VERSION ""

NS_ :

BS_:

BU_: CH DIPF DIPR ETH FC HVI HVS PARTY SDCV VEH VIRT

BO_ 536 UI_driverAssistRoadSign: 8 CH
 SG_ UI_roadSignChecksum : 56|8@1+ (1,0) [0|255] ""  X
 SG_ UI_roadSignCounter : 52|4@1+ (1,0) [0|15] ""  X
 SG_ UI_splineID : 48|4@1+ (1,0) [0|15] ""  X
 SG_ UI_splineLocConfidence : 40|7@1+ (1,0) [0|127] "1"  das
 SG_ UI_rampType m4 : 32|3@1+ (1,0) [0|4] ""  das
 SG_ UI_meanFleetSplineAccelMPS2 m4 : 24|8@1+ (0.05,-6.35) [-6.35|6.4] "m/s^2"  das
 SG_ UI_topQrtlFleetSpeedMPS m3 : 24|8@1+ (0.25,0) [0|63.75] "m/s"  das
 SG_ UI_stopSignStopLineConf m1 : 18|7@1+ (1,0) [0|127] "1"  X
 SG_ UI_trafficLightStopLineConf m2 : 18|7@1+ (1,0) [0|127] "1"  X
 SG_ UI_medianFleetSpeedMPS m4 : 16|8@1+ (0.25,0) [0|63.75] "m/s"  das
 SG_ UI_bottomQrtlFleetSpeedMPS m3 : 16|8@1+ (0.25,0) [0|63.75] "m/s"  das
 SG_ UI_currSplineIdFull m5 : 8|32@1+ (1,0) [0|4294967295] "1"  app
 SG_ UI_meanFleetSplineSpeedMPS m4 : 8|8@1+ (0.25,0) [0|63.75] "m/s"  das
 SG_ UI_trafficLightStopLineDist m2 : 8|10@1+ (0.25,-8) [-8|247.5] "m"  X
 SG_ UI_stopSignStopLineDist m1 : 8|10@1+ (0.25,-8) [-8|247.5] "m"  X
 SG_ UI_baseMapSpeedLimitMPS m3 : 8|8@1+ (0.25,0) [0|63.75] "m/s"  das
 SG_ UI_dummyData m0 : 8|1@1+ (1,0) [0|1] ""  X
 SG_ UI_roadSign M : 0|8@1+ (1,0) [0|255] ""  das

BO_ 2046 dynamicMessage0_0: 1 CH
 SG_ DAS_tbarTorqueOffset : 0|8@1+ (0.005,-0.64) [-0.64|0.63] "Nm"  aps

BO_ 845 TAS_warningMatrix1: 8 CH
 SG_ TAS_w041_PWMopenRR : 40|1@1+ (1,0) [0|1] ""  gtw
 SG_ TAS_w040_PWMopenRL : 39|1@1+ (1,0) [0|1] ""  gtw
 SG_ TAS_w039_PWMopenFR : 38|1@1+ (1,0) [0|1] ""  gtw
 SG_ TAS_w038_PWMopenFL : 37|1@1+ (1,0) [0|1] ""  gtw
 SG_ TAS_w037_PWMshortRR : 36|1@1+ (1,0) [0|1] ""  gtw
 SG_ TAS_w036_PWMshortRL : 35|1@1+ (1,0) [0|1] ""  gtw
 SG_ TAS_w035_PWMshortFR : 34|1@1+ (1,0) [0|1] ""  gtw
 SG_ TAS_w034_PWMshortFL : 33|1@1+ (1,0) [0|1] ""  gtw
 SG_ TAS_w033_PWMerrorRR : 32|1@1+ (1,0) [0|1] ""  gtw
 SG_ TAS_w032_PWMerrorRL : 31|1@1+ (1,0) [0|1] ""  gtw
 SG_ TAS_w031_PWMerrorFR : 30|1@1+ (1,0) [0|1] ""  gtw
 SG_ TAS_w030_PWMerrorFL : 29|1@1+ (1,0) [0|1] ""  gtw
 SG_ TAS_w029_NVRAMUninitialized : 28|1@1+ (1,0) [0|1] ""  gtw
 SG_ TAS_w028_NVRAMNotResponding : 27|1@1+ (1,0) [0|1] ""  gtw
 SG_ TAS_w027_NVRAMCorruption : 26|1@1+ (1,0) [0|1] ""  gtw
 SG_ TAS_w026_FlashMemoryError : 25|1@1+ (1,0) [0|1] ""  gtw
 SG_ TAS_w025_CrashEvent : 24|1@1+ (1,0) [0|1] ""  gtw
 SG_ TAS_w024_WakeError : 23|1@1+ (1,0) [0|1] ""  gtw
 SG_ TAS_w023_SleepError : 22|1@1+ (1,0) [0|1] ""  gtw
 SG_ TAS_w022_TaskInitError : 21|1@1+ (1,0) [0|1] ""  gtw
 SG_ TAS_w021_TaskSchedulerError : 20|1@1+ (1,0) [0|1] ""  gtw
 SG_ TAS_w020_PWMError : 19|1@1+ (1,0) [0|1] ""  gtw
 SG_ TAS_w019_I2CError : 18|1@1+ (1,0) [0|1] ""  gtw
 SG_ TAS_w018_ADCError : 17|1@1+ (1,0) [0|1] ""  gtw
 SG_ TAS_w017_AwakeForTooLong : 16|1@1+ (1,0) [0|1] ""  gtw
 SG_ TAS_w016_MessageTimingError : 15|1@1+ (1,0) [0|1] ""  gtw
 SG_ TAS_w015_NVMMAlert : 14|1@1+ (1,0) [0|1] ""  gtw
 SG_ TAS_w014_BridgeFault : 13|1@1+ (1,0) [0|1] ""  gtw
 SG_ TAS_w013_Shared13 : 12|1@1+ (1,0) [0|1] ""  gtw
 SG_ TAS_w012_CPUReset : 11|1@1+ (1,0) [0|1] ""  gtw
 SG_ TAS_w011_ECUSupplyVoltError : 10|1@1+ (1,0) [0|1] ""  gtw
 SG_ TAS_w010_ExtSupplyVoltError : 9|1@1+ (1,0) [0|1] ""  gtw
 SG_ TAS_w009_LIN3Error : 8|1@1+ (1,0) [0|1] ""  gtw
 SG_ TAS_w008_LIN2Error : 7|1@1+ (1,0) [0|1] ""  gtw
 SG_ TAS_w007_LINTimeout : 6|1@1+ (1,0) [0|1] ""  gtw
 SG_ TAS_w006_CANLowError : 5|1@1+ (1,0) [0|1] ""  gtw
 SG_ TAS_w005_CANHighError : 4|1@1+ (1,0) [0|1] ""  gtw
 SG_ TAS_w004_CANMIA : 3|1@1+ (1,0) [0|1] ""  gtw
 SG_ TAS_w003_SWAssertion : 2|1@1+ (1,0) [0|1] ""  gtw
 SG_ TAS_w002_PowerLossReset : 1|1@1+ (1,0) [0|1] ""  gtw
 SG_ TAS_w001_WatchdogReset : 0|1@1+ (1,0) [0|1] ""  gtw

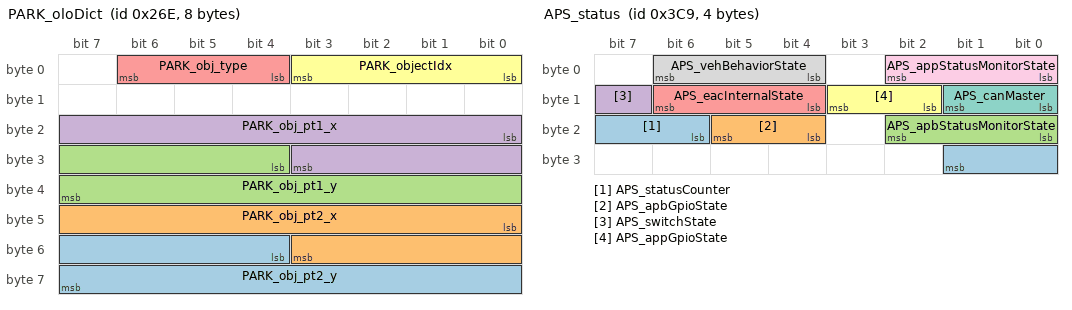
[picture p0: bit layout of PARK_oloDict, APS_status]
BO_ 622 PARK_oloDict: 8 CH
 SG_ PARK_obj_pt2_y : 52|12@1+ (1,0) [0|4095] ""  das
 SG_ PARK_obj_pt2_x : 40|12@1+ (1,0) [0|4095] ""  das
 SG_ PARK_obj_pt1_y : 28|12@1+ (1,0) [0|4095] ""  das
 SG_ PARK_obj_pt1_x : 16|12@1+ (1,0) [0|4095] ""  das
 SG_ PARK_obj_type : 4|3@1+ (1,0) [0|4] ""  das
 SG_ PARK_objectIdx : 0|4@1+ (1,0) [0|15] ""  das

BO_ 969 APS_status: 4 CH
 SG_ APS_statusCounter : 22|4@1+ (1,0) [0|15] ""  X
 SG_ APS_apbGpioState : 20|2@1+ (1,0) [0|3] ""  gtw
 SG_ APS_apbStatusMonitorState : 16|3@1+ (1,0) [0|7] ""  gtw
 SG_ APS_switchState : 15|1@1+ (1,0) [0|1] ""  X
 SG_ APS_eacInternalState : 12|3@1+ (1,0) [0|7] ""  gtw
 SG_ APS_appGpioState : 10|2@1+ (1,0) [0|3] ""  gtw
 SG_ APS_canMaster : 8|2@1+ (1,0) [0|3] ""  gtw
 SG_ APS_vehBehaviorState : 4|3@1+ (1,0) [0|7] ""  gtw
 SG_ APS_appStatusMonitorState : 0|3@1+ (1,0) [0|7] ""  gtw

BO_ 1848 EPAS3S_udsResponse: 8 CH
 SG_ EPAS3S_udsResponseData : 7|64@0+ (1,0) [0|18446744073709551615] ""  gtw

BO_ 874 DAS_warningMatrix1: 8 CH
 SG_ DAS_w106_torsionBarCalibrated : 41|1@1+ (1,0) [0|1] ""  gtw
 SG_ DAS_w105_DEPRECATED : 40|1@1+ (1,0) [0|1] ""  gtw
 SG_ DAS_w104_DEPRECATED : 39|1@1+ (1,0) [0|1] ""  gtw
 SG_ DAS_w103_robExperimentalAEB : 38|1@1+ (1,0) [0|1] ""  gtw
 SG_ DAS_w102_DEPRECATED : 37|1@1+ (1,0) [0|1] ""  gtw
 SG_ DAS_w101_DEPRECATED : 36|1@1+ (1,0) [0|1] ""  gtw
 SG_ DAS_w100_DEPRECATED : 35|1@1+ (1,0) [0|1] ""  gtw
 SG_ DAS_w099_DEPRECATED : 34|1@1+ (1,0) [0|1] ""  gtw
 SG_ DAS_w098_DEPRECATED : 33|1@1+ (1,0) [0|1] ""  gtw
 SG_ DAS_w097_DEPRECATED : 32|1@1+ (1,0) [0|1] ""  gtw
 SG_ DAS_w096_DEPRECATED : 31|1@1+ (1,0) [0|1] ""  gtw
 SG_ DAS_w095_DEPRECATED : 30|1@1+ (1,0) [0|1] ""  gtw
 SG_ DAS_w094_DEPRECATED : 29|1@1+ (1,0) [0|1] ""  gtw
 SG_ DAS_w093_DEPRECATED : 28|1@1+ (1,0) [0|1] ""  gtw
 SG_ DAS_w092_DEPRECATED : 27|1@1+ (1,0) [0|1] ""  gtw
 SG_ DAS_w091_DEPRECATED : 26|1@1+ (1,0) [0|1] ""  gtw
 SG_ DAS_w090_DEPRECATED : 25|1@1+ (1,0) [0|1] ""  gtw
 SG_ DAS_w089_DEPRECATED : 24|1@1+ (1,0) [0|1] ""  gtw
 SG_ DAS_w088_DEPRECATED : 23|1@1+ (1,0) [0|1] ""  gtw
 SG_ DAS_w087_DEPRECATED : 22|1@1+ (1,0) [0|1] ""  gtw
 SG_ DAS_w086_robCollision : 21|1@1+ (1,0) [0|1] ""  gtw
 SG_ DAS_w085_pmmSteering : 20|1@1+ (1,0) [0|1] ""  gtw
 SG_ DAS_w084_pmmIPSO : 19|1@1+ (1,0) [0|1] ""  gtw
 SG_ DAS_w083_inPathRADObject : 18|1@1+ (1,0) [0|1] ""  gtw
 SG_ DAS_w082_inPathFSviolation : 17|1@1+ (1,0) [0|1] ""  gtw
 SG_ DAS_w081_pmmActiveBraking : 16|1@1+ (1,0) [0|1] ""  gtw
 SG_ DAS_w080_accFailedActivation : 15|1@1+ (1,0) [0|1] ""  gtw
 SG_ DAS_w079_edrAvailable : 14|1@1+ (1,0) [0|1] ""  gtw
 SG_ DAS_w078_pmmActive2 : 13|1@1+ (1,0) [0|1] ""  gtw
 SG_ DAS_w077_pmmActive : 12|1@1+ (1,0) [0|1] ""  gtw
 SG_ DAS_w076_mobilEyeSetC : 11|1@1+ (1,0) [0|1] ""  gtw
 SG_ DAS_w075_scMia : 10|1@1+ (1,0) [0|1] ""  gtw
 SG_ DAS_w074_inPathStationaryObst : 9|1@1+ (1,0) [0|1] ""  gtw
 SG_ DAS_w073_issueEscalatedLDW : 8|1@1+ (1,0) [0|1] ""  gtw
 SG_ DAS_w072_selfparkComplete : 7|1@1+ (1,0) [0|1] ""  gtw
 SG_ DAS_w071_selfparkStarted : 6|1@1+ (1,0) [0|1] ""  gtw
 SG_ DAS_w070_apcIncompleteCal : 5|1@1+ (1,0) [0|1] ""  gtw
 SG_ DAS_w069_apcSpaceMasked : 4|1@1+ (1,0) [0|1] ""  gtw
 SG_ DAS_w068_vlInconsistency : 3|1@1+ (1,0) [0|1] ""  gtw
 SG_ DAS_w067_steeringAlignment : 2|1@1+ (1,0) [0|1] ""  gtw
 SG_ DAS_w066_deserializerLockLost : 1|1@1+ (1,0) [0|1] ""  gtw
 SG_ DAS_w065_deserializerOvercurrent : 0|1@1+ (1,0) [0|1] ""  gtw

BO_ 1469 IBST_alertLog: 8 CH
 SG_ IBST_alertState : 15|1@1+ (1,0) [0|1] ""  gtw
 SG_ IBST_alertID : 0|8@1+ (1,0) [0|176] ""  gtw

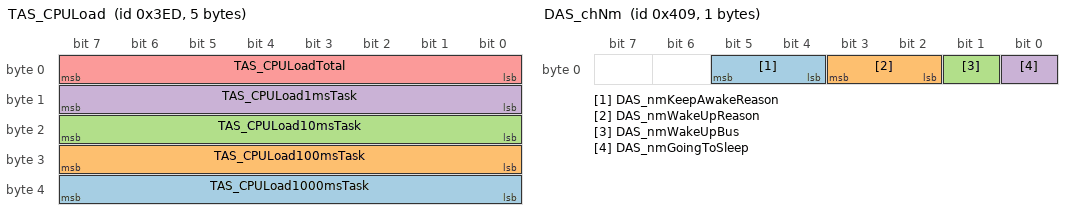
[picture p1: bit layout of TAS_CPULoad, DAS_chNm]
BO_ 1005 TAS_CPULoad: 5 CH
 SG_ TAS_CPULoad1000msTask : 32|8@1+ (1,0) [0|255] ""  X
 SG_ TAS_CPULoad100msTask : 24|8@1+ (1,0) [0|255] ""  X
 SG_ TAS_CPULoad10msTask : 16|8@1+ (1,0) [0|255] ""  X
 SG_ TAS_CPULoad1msTask : 8|8@1+ (1,0) [0|255] ""  X
 SG_ TAS_CPULoadTotal : 0|8@1+ (1,0) [0|255] ""  X

BO_ 1033 DAS_chNm: 1 CH
 SG_ DAS_nmKeepAwakeReason : 4|2@1+ (1,0) [0|2] ""  aps
 SG_ DAS_nmWakeUpReason : 2|2@1+ (1,0) [0|3] ""  aps
 SG_ DAS_nmWakeUpBus : 1|1@1+ (1,0) [0|1] ""  aps
 SG_ DAS_nmGoingToSleep : 0|1@1+ (1,0) [0|1] ""  aps

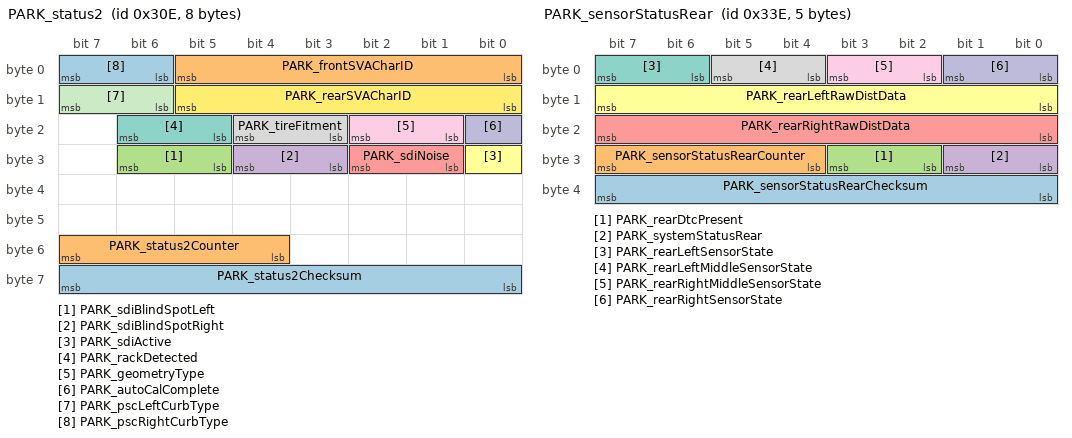
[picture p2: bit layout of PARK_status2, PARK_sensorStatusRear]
BO_ 782 PARK_status2: 8 CH
 SG_ PARK_status2Checksum : 56|8@1+ (1,0) [0|255] ""  X
 SG_ PARK_status2Counter : 52|4@1+ (1,0) [0|15] ""  das
 SG_ PARK_sdiBlindSpotLeft : 29|2@1+ (1,0) [0|3] ""  das
 SG_ PARK_sdiBlindSpotRight : 27|2@1+ (1,0) [0|3] ""  das
 SG_ PARK_sdiNoise : 25|2@1+ (1,0) [0|3] ""  das
 SG_ PARK_sdiActive : 24|1@1+ (1,0) [0|1] ""  das
 SG_ PARK_rackDetected : 21|2@1+ (1,0) [0|3] ""  das
 SG_ PARK_tireFitment : 19|2@1+ (1,0) [0|3] ""  das
 SG_ PARK_geometryType : 17|2@1+ (1,0) [0|3] ""  X
 SG_ PARK_autoCalComplete : 16|1@1+ (1,0) [0|1] ""  das
 SG_ PARK_pscLeftCurbType : 14|2@1+ (1,0) [0|2] ""  das
 SG_ PARK_rearSVACharID : 8|6@1+ (1,0) [0|63] ""  das
 SG_ PARK_pscRightCurbType : 6|2@1+ (1,0) [0|2] ""  das
 SG_ PARK_frontSVACharID : 0|6@1+ (1,0) [0|63] ""  das

BO_ 2023 CMP_EOLTest: 8 CH
 SG_ CMP_EOLData : 0|64@1+ (1,0) [0|18446744073709551615] ""  X

BO_ 557 TAS_data: 7 CH
 SG_ TAS_componentPressureRL m2 : 43|8@1+ (0.1,0) [0|25.5] "bar"  X
 SG_ TAS_componentPressureFR m1 : 43|8@1+ (0.1,0) [0|25.5] "bar"  X
 SG_ TAS_componentPressureFL m0 : 43|8@1+ (0.1,0) [0|25.5] "bar"  X
 SG_ TAS_componentPressureRR m3 : 43|8@1+ (0.1,0) [0|25.5] "bar"  X
 SG_ TAS_componentPressureIndex M : 39|2@1+ (1,0) [0|3] ""  X
 SG_ TAS_valveCommandBoost : 38|1@1+ (1,0) [0|1] ""  X
 SG_ TAS_valveCommandExhaust : 37|1@1+ (1,0) [0|1] ""  X
 SG_ TAS_valveCommandReservoir : 36|1@1+ (1,0) [0|1] ""  X
 SG_ TAS_valveCommandRR : 35|1@1+ (1,0) [0|1] ""  X
 SG_ TAS_valveCommandRL : 34|1@1+ (1,0) [0|1] ""  X
 SG_ TAS_valveCommandFR : 33|1@1+ (1,0) [0|1] ""  X
 SG_ TAS_valveCommandFL : 32|1@1+ (1,0) [0|1] ""  X
 SG_ TAS_rawHeightRR : 24|8@1+ (1,-128) [-128|127] "mm"  X
 SG_ TAS_rawHeightRL : 16|8@1+ (1,-128) [-128|127] "mm"  X
 SG_ TAS_rawHeightFR : 8|8@1+ (1,-128) [-128|127] "mm"  X
 SG_ TAS_rawHeightFL : 0|8@1+ (1,-128) [-128|127] "mm"  X

BO_ 806 PARK_info: 8 CH
 SG_ PARK_infoComponentID m10 : 48|16@1+ (1,0) [0|65535] ""  gtw
 SG_ PARK_infoUsageID m11 : 32|16@1+ (1,0) [0|65535] ""  gtw
 SG_ PARK_infoApplicationCRC m13 : 32|32@1+ (1,0) [0|4294967295] ""  gtw
 SG_ PARK_infoBootloaderCRC m20 : 32|32@1+ (1,0) [0|4294967295] ""  gtw
 SG_ PARK_infoAssemblyID m11 : 24|8@1+ (1,0) [0|255] ""  gtw
 SG_ PARK_infoPcbaID m11 : 16|8@1+ (1,0) [0|255] ""  gtw
 SG_ PARK_infoBuildType m10 : 8|8@1+ (1,0) [0|4] ""  gtw
 SG_ PARK_infoBootUdsProtoVersion m20 : 8|8@1+ (1,0) [0|255] ""  gtw
 SG_ PARK_infoIndex M : 0|8@1+ (1,0) [0|255] ""  gtw

BO_ 1592 EPAS3P_udsResponseCH: 8 CH
 SG_ EPAS3P_udsResponseDataCH : 7|64@0+ (1,0) [0|18446744073709551615] ""  gtw

BO_ 830 PARK_sensorStatusRear: 5 CH
 SG_ PARK_sensorStatusRearChecksum : 32|8@1+ (1,0) [0|255] ""  X
 SG_ PARK_sensorStatusRearCounter : 28|4@1+ (1,0) [0|15] ""  das
 SG_ PARK_rearDtcPresent : 26|2@1+ (1,0) [0|3] ""  das
 SG_ PARK_systemStatusRear : 24|2@1+ (1,0) [0|3] ""  das
 SG_ PARK_rearRightRawDistData : 16|8@1+ (1,0) [0|255] "cm"  das
 SG_ PARK_rearLeftRawDistData : 8|8@1+ (1,0) [0|255] "cm"  das
 SG_ PARK_rearLeftSensorState : 6|2@1+ (1,0) [0|3] ""  das
 SG_ PARK_rearLeftMiddleSensorState : 4|2@1+ (1,0) [0|3] ""  das
 SG_ PARK_rearRightMiddleSensorState : 2|2@1+ (1,0) [0|0] "cm"  das
 SG_ PARK_rearRightSensorState : 0|2@1+ (1,0) [0|3] ""  das

BO_ 783 OCS1P_debugCushionMutCNTComp: 8 CH
 SG_ OCS1P_deltaFreqCushionMut : 32|32@1- (0.001,0) [-2147483.648|2147483.647] "Hz"  X
 SG_ OCS1P_cushionMutCNTFreqComp : 0|32@1+ (0.001,0) [0|4294967.295] "Hz"  X

BO_ 2047 GTW_carConfig: 8 CH
 SG_ GTW_eCallEnabled m2 : 63|1@1+ (1,0) [0|1] ""  X
 SG_ GTW_trackModePackage m2 : 62|1@1+ (1,0) [0|1] ""  X
 SG_ GTW_roofGlassType m2 : 61|1@1+ (1,0) [0|1] ""  X
 SG_ GTW_restraintsHardwareType m2 : 56|5@1+ (1,0) [21|23] ""  X
 SG_ GTW_brakeHWType m2 : 55|1@1+ (1,0) [0|1] ""  X
 SG_ GTW_pedestrianWarningSound m2 : 54|1@1+ (1,0) [0|1] ""  X
 SG_ GTW_numberHVILNodes m2 : 51|3@1+ (1,0) [0|5] ""  X
 SG_ GTW_exteriorColor m2 : 48|3@1+ (1,0) [0|6] ""  X
 SG_ GTW_wheelType m2 : 46|2@1+ (1,0) [0|3] ""  X
 SG_ GTW_superchargingAccess m2 : 44|2@1+ (1,0) [0|2] ""  X
 SG_ GTW_autopilot m2 : 42|2@1+ (1,0) [0|3] ""  das
 SG_ GTW_dasHw m1 : 40|3@1+ (1,0) [3|4] ""  X
 SG_ GTW_roofType m2 : 40|2@1+ (1,0) [0|2] ""  X
 SG_ GTW_rearFogLamps m2 : 39|1@1+ (1,0) [0|1] ""  X
 SG_ GTW_rearGlassType m2 : 38|1@1+ (1,0) [0|1] ""  X
 SG_ GTW_spoilerType m2 : 37|1@1+ (1,0) [0|1] ""  X
 SG_ GTW_intrusionSensorType m2 : 36|1@1+ (1,0) [0|1] ""  X
 SG_ GTW_airbagCutoffSwitch m2 : 35|1@1+ (1,0) [0|1] ""  X
 SG_ GTW_activeHighBeam m2 : 34|1@1+ (1,0) [0|1] ""  X
 SG_ GTW_windshieldType m2 : 33|1@1+ (1,0) [0|1] ""  X
 SG_ GTW_tireType m1 : 32|3@1+ (1,0) [0|5] ""  X
 SG_ GTW_eBuckConfig m2 : 32|1@1+ (1,0) [0|1] ""  X
 SG_ GTW_performancePackage m2 : 31|1@1+ (1,0) [0|1] ""  X
 SG_ GTW_CabinBlowerCtrlType m2 : 30|1@1+ (1,0) [0|1] ""  X
 SG_ GTW_hvacPanelVaneType m2 : 29|1@1+ (1,0) [0|1] ""  X
 SG_ GTW_hvacQuietSnorkelType m2 : 28|1@1+ (1,0) [0|1] ""  X
 SG_ GTW_auxParkLamps m2 : 26|2@1+ (1,0) [0|2] ""  X
 SG_ GTW_frontSeatType m2 : 25|1@1+ (1,0) [0|1] ""  X
 SG_ GTW_ibstWakeType m2 : 24|1@1+ (1,0) [0|1] ""  X
 SG_ GTW_lumbarECUType m2 : 23|1@1+ (1,0) [0|1] ""  X
 SG_ GTW_audioType m2 : 22|1@1+ (1,0) [0|1] ""  X
 SG_ GTW_headlamps m2 : 21|1@1+ (1,0) [0|1] ""  X
 SG_ GTW_frontFogLamps m2 : 20|1@1+ (1,0) [0|1] ""  X
 SG_ GTW_interiorLighting m2 : 19|1@1+ (1,0) [0|1] ""  X
 SG_ GTW_powerSteeringColumn m2 : 18|1@1+ (1,0) [0|1] ""  X
 SG_ GTW_memoryMirrors m2 : 17|1@1+ (1,0) [0|1] ""  das
 SG_ GTW_country m1 : 16|16@1+ (1,0) [0|65535] ""  das
 SG_ GTW_rearLightType m3 : 16|1@1+ (1,0) [0|1] ""  X
 SG_ GTW_xcpESP m2 : 16|1@1+ (1,0) [0|1] ""  X
 SG_ GTW_xcpIbst m2 : 15|1@1+ (1,0) [0|1] ""  X
 SG_ GTW_vdcType m2 : 14|1@1+ (1,0) [0|1] ""  X
 SG_ GTW_homelinkType m2 : 13|1@1+ (1,0) [0|1] ""  X
 SG_ GTW_rightHandDrive m1 : 11|1@1+ (1,0) [0|1] ""  das
 SG_ GTW_packEnergy m2 : 11|2@1+ (1,0) [0|2] ""  X
 SG_ GTW_rearSeatHeaters m2 : 10|1@1+ (1,0) [0|1] ""  X
 SG_ GTW_drivetrainType m1 : 10|1@1+ (1,0) [0|1] ""  das
 SG_ GTW_epasType m1 : 9|1@1+ (1,0) [0|0] ""  das
 SG_ GTW_frontSeatHeaters m2 : 9|1@1+ (1,0) [0|1] ""  X
 SG_ GTW_mapRegion m3 : 8|4@1+ (1,0) [0|8] ""  X
 SG_ GTW_heatedWipers m2 : 8|1@1+ (1,0) [0|1] ""  X
 SG_ GTW_airSuspension m1 : 8|1@1+ (1,0) [0|1] ""  das
 SG_ GTW_carConfigMultiplexer M : 0|8@1+ (1,0) [0|255] ""  epas3s

BO_ 1924 DBG_xcpPMSCommand: 8 CH
 SG_ DBG_xcpPMSCommand : 7|64@0+ (1,0) [0|18446744073709551615] ""  X

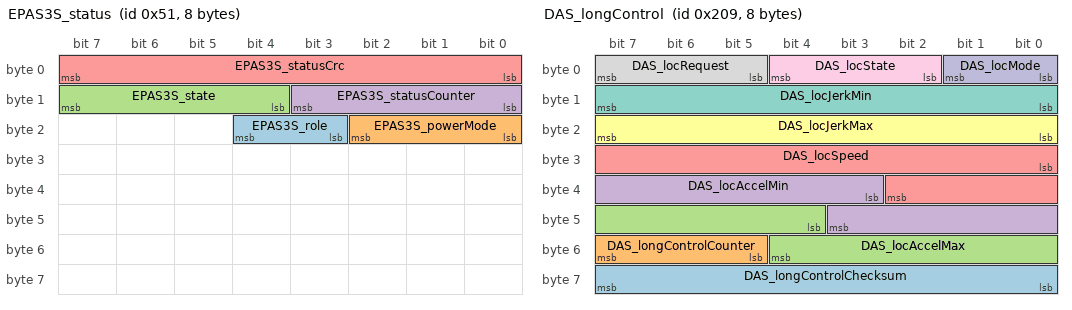
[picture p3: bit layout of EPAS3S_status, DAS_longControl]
BO_ 81 EPAS3S_status: 8 CH
 SG_ EPAS3S_role : 19|2@1+ (1,0) [0|2] ""  app
 SG_ EPAS3S_powerMode : 16|3@1+ (1,0) [0|7] ""  app
 SG_ EPAS3S_state : 12|4@1+ (1,0) [0|15] ""  app
 SG_ EPAS3S_statusCounter : 8|4@1+ (1,0) [0|15] ""  app
 SG_ EPAS3S_statusCrc : 0|8@1+ (1,0) [0|255] ""  app

BO_ 941 TAS_warningMatrix4: 8 CH
 SG_ TAS_w229_PWMfastDetectRR : 36|1@1+ (1,0) [0|1] ""  gtw
 SG_ TAS_w228_PWMfastDetectRL : 35|1@1+ (1,0) [0|1] ""  gtw
 SG_ TAS_w227_PWMfastDetectFR : 34|1@1+ (1,0) [0|1] ""  gtw
 SG_ TAS_w226_PWMfastDetectFL : 33|1@1+ (1,0) [0|1] ""  gtw
 SG_ TAS_w225_galleryPressureTooHigh : 32|1@1+ (1,0) [0|1] ""  gtw
 SG_ TAS_w224_openAirline : 31|1@1+ (1,0) [0|1] ""  gtw
 SG_ TAS_w223_blockedAirline : 30|1@1+ (1,0) [0|1] ""  gtw
 SG_ TAS_w222_compressorPrefillFault : 29|1@1+ (1,0) [0|1] ""  gtw
 SG_ TAS_w221_valveLeakDetected : 28|1@1+ (1,0) [0|1] ""  gtw
 SG_ TAS_w220_exhaustGalleryFault : 27|1@1+ (1,0) [0|1] ""  gtw
 SG_ TAS_w218_limpHomeMode40 : 25|1@1+ (1,0) [0|1] ""  gtw
 SG_ TAS_w217_limpHomeMode30 : 24|1@1+ (1,0) [0|1] ""  gtw
 SG_ TAS_w216_limpHomeMode20 : 23|1@1+ (1,0) [0|1] ""  gtw
 SG_ TAS_w215_limpHomeMode10 : 22|1@1+ (1,0) [0|1] ""  gtw
 SG_ TAS_w214_redWarningLamp : 21|1@1+ (1,0) [0|1] ""  gtw
 SG_ TAS_w213_yellowWarningLamp : 20|1@1+ (1,0) [0|1] ""  gtw
 SG_ TAS_w212_noCurrentSenseCalib : 19|1@1+ (1,0) [0|1] ""  gtw
 SG_ TAS_w211_noRideHeightCalib : 18|1@1+ (1,0) [0|1] ""  gtw
 SG_ TAS_w210_outOfRangeCalibration : 17|1@1+ (1,0) [0|1] ""  gtw
 SG_ TAS_w201_lowHVBattery : 8|1@1+ (1,0) [0|1] ""  gtw
 SG_ TAS_w200_jackModeActive : 7|1@1+ (1,0) [0|1] ""  gtw

BO_ 1081 APP_warningMatrix3: 8 CH
 SG_ APP_w231_idfEvent : 38|1@1+ (1,0) [0|1] ""  gtw
 SG_ APP_w230_alcUltrasoundBlocked : 37|1@1+ (1,0) [0|1] ""  gtw
 SG_ APP_w229_alcUltrasoundDamaged : 36|1@1+ (1,0) [0|1] ""  gtw
 SG_ APP_w228_DEPRECATED : 35|1@1+ (1,0) [0|1] ""  gtw
 SG_ APP_w227_virtualWallBlocked : 34|1@1+ (1,0) [0|1] ""  gtw
 SG_ APP_w226_lcCamCalNeededSpeedLmt : 33|1@1+ (1,0) [0|1] ""  gtw
 SG_ APP_w225_lcDegradedVisSpeedLmt : 32|1@1+ (1,0) [0|1] ""  gtw
 SG_ APP_w224_accCameraCalibration : 31|1@1+ (1,0) [0|1] ""  gtw
 SG_ APP_w223_accObjectInPath : 30|1@1+ (1,0) [0|1] ""  gtw
 SG_ APP_w222_accCameraBlind : 29|1@1+ (1,0) [0|1] ""  gtw
 SG_ APP_w221_accRadarBlind : 28|1@1+ (1,0) [0|1] ""  gtw
 SG_ APP_w220_lcTempUnavailableRoad : 27|1@1+ (1,0) [0|1] ""  gtw
 SG_ APP_w219_lcTempUnavailableSpeed : 26|1@1+ (1,0) [0|1] ""  gtw
 SG_ APP_w218_lcSpeedExceededLimit : 25|1@1+ (1,0) [0|1] ""  gtw
 SG_ APP_w217_lcUnavailableSpeeding : 24|1@1+ (1,0) [0|1] ""  gtw
 SG_ APP_w216_driverOverriding : 23|1@1+ (1,0) [0|1] ""  gtw
 SG_ APP_w215_contDriverNotIntracting : 22|1@1+ (1,0) [0|1] ""  gtw
 SG_ APP_w214_driverNotIntracting : 21|1@1+ (1,0) [0|1] ""  gtw
 SG_ APP_w213_autosteerStruckOut : 20|1@1+ (1,0) [0|1] ""  gtw
 SG_ APP_w212_lcUnavailableStrikeOut : 19|1@1+ (1,0) [0|1] ""  gtw
 SG_ APP_w211_accNoSeatBelt : 18|1@1+ (1,0) [0|1] ""  gtw
 SG_ APP_w210_camObstrcted : 17|1@1+ (1,0) [0|1] ""  gtw
 SG_ APP_w209_autoSummonRequest : 16|1@1+ (1,0) [0|1] ""  gtw
 SG_ APP_w208_rackDetected : 15|1@1+ (1,0) [0|1] ""  gtw
 SG_ APP_w207_autosteerUnavailable : 14|1@1+ (1,0) [0|1] ""  gtw
 SG_ APP_w206_autosteerNotEnabled : 13|1@1+ (1,0) [0|1] ""  gtw
 SG_ APP_w205_apcFinalRear : 12|1@1+ (1,0) [0|1] ""  gtw
 SG_ APP_w204_apcFinalFront : 11|1@1+ (1,0) [0|1] ""  gtw
 SG_ APP_w203_apcActivation : 10|1@1+ (1,0) [0|1] ""  gtw
 SG_ APP_w202_scwNoisyEnvironment : 9|1@1+ (1,0) [0|1] ""  gtw
 SG_ APP_w201_lcAborting : 8|1@1+ (1,0) [0|1] ""  gtw
 SG_ APP_w200_lcSlowdown : 7|1@1+ (1,0) [0|1] ""  gtw
 SG_ APP_w199_apcAbort : 6|1@1+ (1,0) [0|1] ""  gtw
 SG_ APP_w198_tsrUnavailable : 5|1@1+ (1,0) [0|1] ""  gtw
 SG_ APP_w197_redLightWarning : 4|1@1+ (1,0) [0|1] ""  gtw
 SG_ APP_w196_stopSignWarning : 3|1@1+ (1,0) [0|1] ""  gtw
 SG_ APP_w195_scwUnavailable : 2|1@1+ (1,0) [0|1] ""  gtw
 SG_ APP_w194_accDriverResumeRqrd : 1|1@1+ (1,0) [0|1] ""  gtw
 SG_ APP_w193_camWindshieldUnclean : 0|1@1+ (1,0) [0|1] ""  gtw

BO_ 781 TAS_compTemp: 2 CH
 SG_ TAS_compTempModel : 8|8@1+ (1,-40) [-40|120] "C"  gtw
 SG_ TAS_compTempSensor : 0|8@1+ (1,-40) [-40|120] "C"  gtw

BO_ 521 DAS_longControl: 8 CH
 SG_ DAS_longControlChecksum : 56|8@1+ (1,0) [0|255] ""  X
 SG_ DAS_longControlCounter : 53|3@1+ (1,0) [0|7] ""  X
 SG_ DAS_locAccelMax : 44|9@1+ (0.04,-15) [-15|5.44] "m/s^2"  X
 SG_ DAS_locAccelMin : 35|9@1+ (0.04,-15) [-15|5.44] "m/s^2"  X
 SG_ DAS_locSpeed : 24|11@1+ (0.1,0) [0|204.7] "kph"  X
 SG_ DAS_locJerkMax : 16|8@1+ (0.034,0) [0|8.67] "m/s^3"  X
 SG_ DAS_locJerkMin : 8|8@1+ (0.034,-8.67) [-8.67|0] "m/s^3"  X
 SG_ DAS_locRequest : 5|3@1+ (1,0) [0|4] ""  X
 SG_ DAS_locState : 2|3@1+ (1,0) [0|7] ""  X
 SG_ DAS_locMode : 0|2@1+ (1,0) [0|3] ""  X

BO_ 943 OCS1P_debugSeatbackSelfCNTComp: 8 CH
 SG_ OCS1P_deltaFreqSeatbackSelf : 32|32@1- (0.001,0) [-2147483.648|2147483.647] "Hz"  X
 SG_ OCS1P_seatbackSelfCNTFreqComp : 0|32@1+ (0.001,0) [0|4294967.295] "Hz"  X

BO_ 963 VCRIGHT_switchStatus: 7 CH
 SG_ VCRIGHT_trunkExtReleasePressed : 48|1@1+ (1,0) [0|1] ""  X
 SG_ VCRIGHT_rearRightBuckleSwitch : 46|2@1+ (1,0) [0|3] ""  X
 SG_ VCRIGHT_rearCenterBuckleSwitch : 44|2@1+ (1,0) [0|3] ""  X
 SG_ VCRIGHT_frontOccupancySwitch : 42|2@1+ (1,0) [0|3] ""  X
 SG_ VCRIGHT_frontBuckleSwitch : 40|2@1+ (1,0) [0|3] ""  ocs1p
 SG_ VCRIGHT_btnWindowSwPackAutoDwnLR : 39|1@1+ (1,0) [0|1] ""  X
 SG_ VCRIGHT_btnWindowSwPackDownLR : 38|1@1+ (1,0) [0|1] ""  X
 SG_ VCRIGHT_btnWindowSwPackAutoUpLR : 37|1@1+ (1,0) [0|1] ""  X
 SG_ VCRIGHT_btnWindowSwPackUpLR : 36|1@1+ (1,0) [0|1] ""  X
 SG_ VCRIGHT_btnWindowSwPackAutoDwnLF : 35|1@1+ (1,0) [0|1] ""  X
 SG_ VCRIGHT_btnWindowSwPackDownLF : 34|1@1+ (1,0) [0|1] ""  X
 SG_ VCRIGHT_btnWindowSwPackAutoUpLF : 33|1@1+ (1,0) [0|1] ""  X
 SG_ VCRIGHT_btnWindowSwPackUpLF : 32|1@1+ (1,0) [0|1] ""  X
 SG_ VCRIGHT_btnWindowAutoDownRR : 31|1@1+ (1,0) [0|1] ""  X
 SG_ VCRIGHT_btnWindowDownRR : 30|1@1+ (1,0) [0|1] ""  X
 SG_ VCRIGHT_btnWindowAutoUpRR : 29|1@1+ (1,0) [0|1] ""  X
 SG_ VCRIGHT_btnWindowUpRR : 28|1@1+ (1,0) [0|1] ""  X
 SG_ VCRIGHT_btnWindowAutoDownRF : 27|1@1+ (1,0) [0|1] ""  X
 SG_ VCRIGHT_btnWindowDownRF : 26|1@1+ (1,0) [0|1] ""  X
 SG_ VCRIGHT_btnWindowAutoUpRF : 25|1@1+ (1,0) [0|1] ""  X
 SG_ VCRIGHT_btnWindowUpRF : 24|1@1+ (1,0) [0|1] ""  X
 SG_ VCRIGHT_frontSeatLumbarOut : 22|2@1+ (1,0) [0|3] ""  X
 SG_ VCRIGHT_frontSeatLumbarIn : 20|2@1+ (1,0) [0|3] ""  X
 SG_ VCRIGHT_frontSeatLumbarUp : 18|2@1+ (1,0) [0|3] ""  X
 SG_ VCRIGHT_frontSeatLumbarDown : 16|2@1+ (1,0) [0|3] ""  X
 SG_ VCRIGHT_frontSeatBackrestForward : 14|2@1+ (1,0) [0|3] ""  X
 SG_ VCRIGHT_frontSeatBackrestBack : 12|2@1+ (1,0) [0|3] ""  X
 SG_ VCRIGHT_frontSeatLiftUp : 10|2@1+ (1,0) [0|3] ""  X
 SG_ VCRIGHT_frontSeatLiftDown : 8|2@1+ (1,0) [0|3] ""  X
 SG_ VCRIGHT_frontSeatTiltUp : 6|2@1+ (1,0) [0|3] ""  X
 SG_ VCRIGHT_frontSeatTiltDown : 4|2@1+ (1,0) [0|3] ""  X
 SG_ VCRIGHT_frontSeatTrackForward : 2|2@1+ (1,0) [0|3] ""  X
 SG_ VCRIGHT_frontSeatTrackBack : 0|2@1+ (1,0) [0|3] ""  X

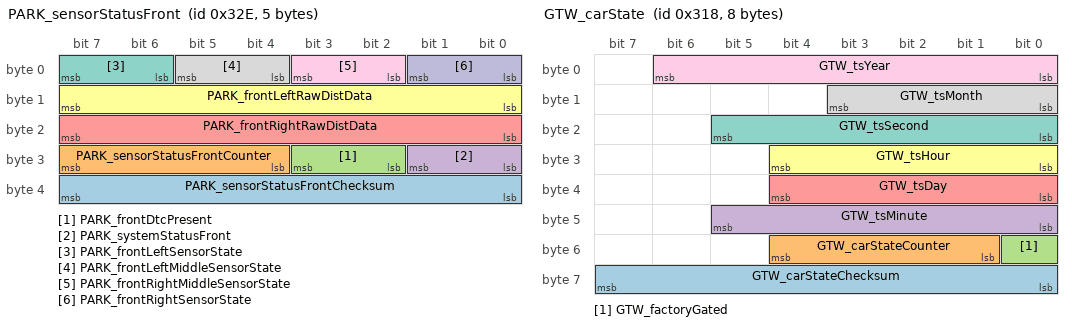
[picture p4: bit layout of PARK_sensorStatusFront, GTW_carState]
BO_ 814 PARK_sensorStatusFront: 5 CH
 SG_ PARK_sensorStatusFrontChecksum : 32|8@1+ (1,0) [0|255] ""  X
 SG_ PARK_sensorStatusFrontCounter : 28|4@1+ (1,0) [0|15] ""  X
 SG_ PARK_frontDtcPresent : 26|2@1+ (1,0) [0|3] ""  das
 SG_ PARK_systemStatusFront : 24|2@1+ (1,0) [0|3] ""  das
 SG_ PARK_frontRightRawDistData : 16|8@1+ (1,0) [0|255] "cm"  das
 SG_ PARK_frontLeftRawDistData : 8|8@1+ (1,0) [0|255] "cm"  das
 SG_ PARK_frontLeftSensorState : 6|2@1+ (1,0) [0|3] ""  das
 SG_ PARK_frontLeftMiddleSensorState : 4|2@1+ (1,0) [0|3] ""  das
 SG_ PARK_frontRightMiddleSensorState : 2|2@1+ (1,0) [0|3] ""  das
 SG_ PARK_frontRightSensorState : 0|2@1+ (1,0) [0|3] ""  das

BO_ 1513 APP_alertLog: 8 CH
 SG_ APP_sw076_accActive m76 : 63|1@1+ (1,0) [0|1] ""  gtw
 SG_ APP_sw060_accActive m60 : 63|1@1+ (1,0) [0|1] ""  gtw
 SG_ APP_sw074_autopilotActive m74 : 63|1@1+ (1,0) [0|1] ""  gtw
 SG_ APP_sw016_accActive m16 : 63|1@1+ (1,0) [0|1] ""  gtw
 SG_ APP_sw053_a62strRackMismatch m53 : 63|1@1+ (1,0) [0|1] ""  gtw
 SG_ APP_sw050_accActive m50 : 63|1@1+ (1,0) [0|1] ""  gtw
 SG_ APP_sw017_Any_FCW_PCW_Msg_Recd m17 : 63|1@1+ (1,0) [0|1] ""  gtw
 SG_ APP_sw257_user_sensitivity m257 : 62|2@1+ (1,0) [0|3] ""  gtw
 SG_ APP_sw027_Unused_word m27 : 62|2@1+ (1,0) [0|3] ""  gtw
 SG_ APP_sw053_a61radPositionMismatch m53 : 62|1@1+ (1,0) [0|1] ""  gtw
 SG_ APP_sw074_cruiseActive m74 : 62|1@1+ (1,0) [0|1] ""  gtw
 SG_ APP_sw017_Any_Common_Msg_Recd m17 : 62|1@1+ (1,0) [0|1] ""  gtw
 SG_ APP_sw260_user_sensitivity m260 : 62|2@1+ (1,0) [0|3] ""  gtw
 SG_ APP_sw072_userTimeout m72 : 62|1@1+ (1,0) [0|1] ""  gtw
 SG_ APP_sw016_fcmModeAtEvent m16 : 61|2@1+ (1,0) [0|3] ""  gtw
 SG_ APP_sw017_Any_Hlb_Msg_Recd m17 : 61|1@1+ (1,0) [0|1] ""  gtw
 SG_ APP_sw191_cameraFailsafes m191 : 61|3@1+ (1,0) [0|7] ""  gtw
 SG_ APP_sw027_PORST m27 : 61|1@1+ (1,0) [0|1] ""  gtw
 SG_ APP_sw004_visionNotRunning m4 : 61|1@1+ (1,0) [0|1] ""  gtw
 SG_ APP_sw076_fcmModeAtEvent m76 : 61|2@1+ (1,0) [0|3] ""  gtw
 SG_ APP_sw072_garageOpened m72 : 61|1@1+ (1,0) [0|1] ""  gtw
 SG_ APP_sw050_fcmModeAtEvent m50 : 61|2@1+ (1,0) [0|3] ""  gtw
 SG_ APP_sw053_a60drmiInvalidCount m53 : 61|1@1+ (1,0) [0|1] ""  gtw
 SG_ APP_sw050_overrideSteer m50 : 60|1@1+ (1,0) [0|1] ""  gtw
 SG_ APP_sw199_numShifts m199 : 60|4@1+ (1,0) [0|15] ""  gtw
 SG_ APP_sw017_Any_Tsr_Msg_Recd m17 : 60|1@1+ (1,0) [0|1] ""  gtw
 SG_ APP_sw053_a59drmiInvalidChkSm m53 : 60|1@1+ (1,0) [0|1] ""  gtw
 SG_ APP_sw027_STDBY_WDG m27 : 60|1@1+ (1,0) [0|1] ""  gtw
 SG_ APP_sw143_predOverlap m143 : 60|4@1+ (10,0) [0|150] "percent"  gtw
 SG_ APP_sw191_radarBlind m191 : 60|1@1+ (1,0) [0|1] ""  gtw
 SG_ APP_sw060_collisionWarningSource m60 : 60|3@1+ (1,0) [0|7] ""  gtw
 SG_ APP_sw013_numTransportErrors m13 : 60|4@1+ (1,0) [0|15] ""  gtw
 SG_ APP_sw073_freespaceRightFarZ m73 : 60|4@1+ (4,0) [0|60] "m"  gtw
 SG_ APP_sw072_keyfobPress m72 : 60|1@1+ (1,0) [0|1] ""  gtw
 SG_ APP_sw016_overrideSteer m16 : 60|1@1+ (1,0) [0|1] ""  gtw
 SG_ APP_sw004_SelfGlare m4 : 60|1@1+ (1,0) [0|1] ""  gtw
 SG_ APP_sw231_predOverlap m231 : 60|4@1+ (10,0) [0|150] "percent"  gtw
 SG_ APP_sw076_overrideSteer m76 : 60|1@1+ (1,0) [0|1] ""  gtw
 SG_ APP_sw050_overrideBrake m50 : 59|1@1+ (1,0) [0|1] ""  gtw
 SG_ APP_sw072_handlePress m72 : 59|1@1+ (1,0) [0|1] ""  gtw
 SG_ APP_sw060_overrideSteer m60 : 59|1@1+ (1,0) [0|1] ""  gtw
 SG_ APP_sw143_steeringOverride m143 : 59|1@1+ (1,0) [0|1] ""  gtw
 SG_ APP_sw103_radAlignment m103 : 59|5@1+ (0.015625,-0.2343) [-0.2343|0.25] "rad"  gtw
 SG_ APP_sw016_overrideBrake m16 : 59|1@1+ (1,0) [0|1] ""  gtw
 SG_ APP_sw053_a57dimodValidity m53 : 59|1@1+ (1,0) [0|1] ""  gtw
 SG_ APP_sw083_Targ5_wNonObj m83 : 59|5@1+ (0.03125,0) [0|0.96875] "%"  gtw
 SG_ APP_sw074_roadClass m74 : 59|3@1+ (1,0) [0|7] ""  gtw
 SG_ APP_sw027_SWD m27 : 59|1@1+ (1,0) [0|1] ""  gtw
 SG_ APP_sw191_radarFault m191 : 59|1@1+ (1,0) [0|1] ""  gtw
 SG_ APP_sw076_overrideBrake m76 : 59|1@1+ (1,0) [0|1] ""  gtw
 SG_ APP_sw231_steeringOverride m231 : 59|1@1+ (1,0) [0|1] ""  gtw
 SG_ APP_sw004_FoggyLights m4 : 59|1@1+ (1,0) [0|1] ""  gtw
 SG_ APP_sw050_overrideBlinker m50 : 58|1@1+ (1,0) [0|1] ""  gtw
 SG_ APP_sw006_timeOfDay m6 : 58|2@1+ (1,0) [0|3] ""  gtw
 SG_ APP_sw060_overrideBrake m60 : 58|1@1+ (1,0) [0|1] ""  gtw
 SG_ APP_sw053_a56bcmodValidity m53 : 58|1@1+ (1,0) [0|1] ""  gtw
 SG_ APP_sw027_EVR33 m27 : 58|1@1+ (1,0) [0|1] ""  gtw
 SG_ APP_sw072_guidanceTimer m72 : 58|1@1+ (1,0) [0|1] ""  gtw
 SG_ APP_sw004_SmearedHalos m4 : 58|1@1+ (1,0) [0|1] ""  gtw
 SG_ APP_sw085_freeSpaceC0Right m85 : 58|5@1+ (1,-15) [-15|16] "m"  gtw
 SG_ APP_sw016_overrideBlinker m16 : 58|1@1+ (1,0) [0|1] ""  gtw
 SG_ APP_sw076_overrideBlinker m76 : 58|1@1+ (1,0) [0|1] ""  gtw
 SG_ APP_sw047_unused m47 : 58|6@1+ (1,0) [0|63] ""  gtw
 SG_ APP_sw072_guidanceRunaway m72 : 57|1@1+ (1,0) [0|1] ""  gtw
 SG_ APP_sw053_a55stwmodValidity m53 : 57|1@1+ (1,0) [0|1] ""  gtw
 SG_ APP_sw027_EVR13 m27 : 57|1@1+ (1,0) [0|1] ""  gtw
 SG_ APP_sw050_overrideAccelPed m50 : 57|1@1+ (1,0) [0|1] ""  gtw
 SG_ APP_sw006_trailerMode m6 : 57|1@1+ (1,0) [0|1] ""  gtw
 SG_ APP_sw060_overrideBlinker m60 : 57|1@1+ (1,0) [0|1] ""  gtw
 SG_ APP_sw076_overrideAccelPed m76 : 57|1@1+ (1,0) [0|1] ""  gtw
 SG_ APP_sw004_FullBlockage m4 : 57|1@1+ (1,0) [0|1] ""  gtw
 SG_ APP_sw191_roadEstMode m191 : 57|2@1+ (1,0) [0|2] ""  gtw
 SG_ APP_sw103_constArea m103 : 57|2@1+ (1,0) [0|3] ""  gtw
 SG_ APP_sw016_overrideAccelPed m16 : 57|1@1+ (1,0) [0|1] ""  gtw
 SG_ APP_sw026_veh_mean_utilization m26 : 57|7@1+ (1,0) [0|127] "percent"  gtw
 SG_ APP_sw006_brakeLights m6 : 56|1@1+ (1,0) [0|1] ""  gtw
 SG_ APP_sw279_maxTemperature m279 : 56|8@1+ (1,-60) [-60|194] "degC"  gtw
 SG_ APP_sw060_overrideAccelPed m60 : 56|1@1+ (1,0) [0|1] ""  gtw
 SG_ APP_sw187_maxTemperature m187 : 56|8@1+ (1,-60) [-60|194] "degC"  gtw
 SG_ APP_sw053_a54gtwmodValidity m53 : 56|1@1+ (1,0) [0|1] ""  gtw
 SG_ APP_sw184_maxTemperature m184 : 56|8@1+ (1,-60) [-60|194] "degC"  gtw
 SG_ APP_sw015_NarrowCameraBadAssoc m15 : 56|2@1+ (1,0) [0|3] ""  gtw
 SG_ APP_sw275_maxTemperature m275 : 56|8@1+ (1,-60) [-60|194] "degC"  gtw
 SG_ APP_sw073_freespaceLeftFarZ m73 : 56|4@1+ (4,0) [0|60] "m"  gtw
 SG_ APP_sw282_maxTemperature m282 : 56|8@1+ (1,-60) [-60|194] "degC"  gtw
 SG_ APP_sw078_radarTarg1_VxRel m78 : 56|8@1+ (0.2,-25.6) [-25.6|25.4] "m/s"  gtw
 SG_ APP_sw042_road_class m42 : 56|3@1+ (1,0) [0|7] ""  gtw
 SG_ APP_sw072_guidanceComplete m72 : 56|1@1+ (1,0) [0|1] ""  gtw
 SG_ APP_sw063_detectedSubMinorVer m63 : 56|8@1+ (1,0) [0|255] ""  gtw
 SG_ APP_sw188_maxTemperature m188 : 56|8@1+ (1,-60) [-60|194] "degC"  gtw
 SG_ APP_sw263_stabilityControlActive m263 : 56|1@1+ (1,0) [0|1] ""  gtw
 SG_ APP_sw103_ipsoApproved m103 : 56|1@1+ (1,0) [0|1] ""  gtw
 SG_ APP_sw047_edrLoggerBuffer m47 : 56|2@1+ (1,0) [0|3] ""  gtw
 SG_ APP_sw257_driver_reqd_accel m257 : 56|6@1+ (0.2,-12.6) [-12.6|0] "m/s2"  gtw
 SG_ APP_sw185_maxTemperature m185 : 56|8@1+ (1,-60) [-60|194] "degC"  gtw
 SG_ APP_sw276_maxTemperature m276 : 56|8@1+ (1,-60) [-60|194] "degC"  gtw
 SG_ APP_sw281_maxTemperature m281 : 56|8@1+ (1,-60) [-60|194] "degC"  gtw
 SG_ APP_sw258_driver_reqd_accel m258 : 56|8@1+ (0.05,-12.75) [-12.75|0] "m/s2"  gtw
 SG_ APP_sw182_maxTemperature m182 : 56|8@1+ (1,-60) [-60|194] "degC"  gtw
 SG_ APP_sw259_unusedB03 m259 : 56|8@1+ (1,0) [0|255] ""  gtw
 SG_ APP_sw050_driverPressedBrakePed m50 : 56|1@1+ (1,0) [0|1] ""  gtw
 SG_ APP_sw278_maxTemperature m278 : 56|8@1+ (1,-60) [-60|194] "degC"  gtw
 SG_ APP_sw204_maxSpeed m204 : 56|8@1+ (0.1,-12.2) [-12.2|12.2] "mph"  gtw
 SG_ APP_sw189_maxTemperature m189 : 56|8@1+ (1,-60) [-60|194] "degC"  gtw
 SG_ APP_sw190_maxTemperature m190 : 56|8@1+ (1,-60) [-60|194] "degC"  gtw
 SG_ APP_sw273_distanceToLaneExit m273 : 56|8@1- (0.02,0.0) [-2.53|2.53] "meters"  gtw
 SG_ APP_sw011_laneWidth m11 : 56|8@1+ (0.025,0) [0|6.375] "m"  gtw
 SG_ APP_sw260_driver_reqd_accel m260 : 56|6@1+ (0.2,-12.6) [-12.6|0] "m/s2"  gtw
 SG_ APP_sw186_maxTemperature m186 : 56|8@1+ (1,-60) [-60|194] "degC"  gtw
 SG_ APP_sw076_driverPressedBrakePed m76 : 56|1@1+ (1,0) [0|1] ""  gtw
 SG_ APP_sw071_activationType m71 : 56|2@1+ (1,0) [0|3] ""  gtw
 SG_ APP_sw280_maxTemperature m280 : 56|8@1+ (1,-60) [-60|194] "degC"  gtw
 SG_ APP_sw205_rrRightMiddle m205 : 56|8@1+ (1,0) [0|255] "cm"  gtw
 SG_ APP_sw183_maxTemperature m183 : 56|8@1+ (1,-60) [-60|194] "degC"  gtw
 SG_ APP_sw277_maxTemperature m277 : 56|8@1+ (1,-60) [-60|194] "degC"  gtw
 SG_ APP_sw067_offsetEstimator m67 : 56|8@1+ (0.1,-12.8) [-12.8|12.8] "deg"  gtw
 SG_ APP_sw274_maxTemperature m274 : 56|8@1+ (1,-60) [-60|194] "degC"  gtw
 SG_ APP_sw040_view_range m40 : 56|8@1+ (1,0) [0|255] "m"  gtw
 SG_ APP_sw004_AutofixOutOfCalibYaw m4 : 56|1@1+ (1,0) [0|1] ""  gtw
 SG_ APP_sw016_driverPressedBrakePed m16 : 56|1@1+ (1,0) [0|1] ""  gtw
 SG_ APP_sw027_CBS_APP m27 : 56|1@1+ (1,0) [0|1] ""  gtw
 SG_ APP_sw050_driverPressedAccelPed m50 : 55|1@1+ (1,0) [0|1] ""  gtw
 SG_ APP_sw060_driverPressedBrakePed m60 : 55|1@1+ (1,0) [0|1] ""  gtw
 SG_ APP_sw004_AutofixOutOfCalibHorzn m4 : 55|1@1+ (1,0) [0|1] ""  gtw
 SG_ APP_sw042_controlled_access m42 : 55|1@1+ (1,0) [0|1] ""  gtw
 SG_ APP_sw191_roadEstHealth m191 : 55|2@1+ (1,0) [0|3] ""  gtw
 SG_ APP_sw263_tractionControlActive m263 : 55|1@1+ (1,0) [0|1] ""  gtw
 SG_ APP_sw053_a53espmodValidity m53 : 55|1@1+ (1,0) [0|1] ""  gtw
 SG_ APP_sw016_driverPressedAccelPed m16 : 55|1@1+ (1,0) [0|1] ""  gtw
 SG_ APP_sw006_DIaebStateUnavailable m6 : 55|1@1+ (1,0) [0|1] ""  gtw
 SG_ APP_sw076_driverPressedAccelPed m76 : 55|1@1+ (1,0) [0|1] ""  gtw
 SG_ APP_sw027_CBS_DEBUG m27 : 55|1@1+ (1,0) [0|1] ""  gtw
 SG_ APP_sw053_a51yawSanity m53 : 54|1@1+ (1,0) [0|1] ""  gtw
 SG_ APP_sw143_egoVehicleSpeed m143 : 54|5@1+ (5,0) [0|155] "kph"  gtw
 SG_ APP_sw004_AutofixOutOfCalib m4 : 54|1@1+ (1,0) [0|1] ""  gtw
 SG_ APP_sw027_CBS_SYSTEM m27 : 54|1@1+ (1,0) [0|1] ""  gtw
 SG_ APP_sw077_oocOffCourseDist_cm m77 : 54|10@1- (1,0) [-512|511] ""  gtw
 SG_ APP_sw015_MainCameraBadAssoc m15 : 54|2@1+ (1,0) [0|3] ""  gtw
 SG_ APP_sw069_drivingLaneRight m69 : 54|8@1+ (1,0) [0|255] ""  gtw
 SG_ APP_sw042_road_match m42 : 54|1@1+ (1,0) [0|1] ""  gtw
 SG_ APP_sw231_egoVehicleSpeed m231 : 54|5@1+ (5,0) [0|155] "kph"  gtw
 SG_ APP_sw074_ipsowExist m74 : 54|5@1+ (1,0) [0|31] ""  gtw
 SG_ APP_sw083_Targ5_wObj m83 : 54|5@1+ (0.03125,0) [0|0.96875] "%"  gtw
 SG_ APP_sw006_DIaebState_SNA m6 : 54|1@1+ (1,0) [0|1] ""  gtw
 SG_ APP_sw143_targetIsACar m143 : 53|1@1+ (1,0) [0|1] ""  gtw
 SG_ APP_sw191_solverHealth m191 : 53|2@1+ (1,0) [0|3] ""  gtw
 SG_ APP_sw004_PartialBlockage m4 : 53|1@1+ (1,0) [0|1] ""  gtw
 SG_ APP_sw080_cruise_speed_check m80 : 53|1@1+ (1,0) [0|1] ""  gtw
 SG_ APP_sw012_freescaleTemp m12 : 53|8@1- (1,0) [-128|127] "degC"  gtw
 SG_ APP_sw006_yawRate m6 : 53|1@1+ (1,0) [0|1] ""  gtw
 SG_ APP_sw027_STM2 m27 : 53|1@1+ (1,0) [0|1] ""  gtw
 SG_ APP_sw042_cam_OutofFocus m42 : 53|1@1+ (1,0) [0|1] ""  gtw
 SG_ APP_sw053_a50velocitySanity m53 : 53|1@1+ (1,0) [0|1] ""  gtw
 SG_ APP_sw085_freeSpaceC0Left m85 : 53|5@1+ (1,-15) [-15|16] "m"  gtw
 SG_ APP_sw011_scaReasonEldw m11 : 53|1@1+ (1,0) [0|1] ""  gtw
 SG_ APP_sw231_targetIsACar m231 : 53|1@1+ (1,0) [0|1] ""  gtw
 SG_ APP_sw006_longAccel m6 : 52|1@1+ (1,0) [0|1] ""  gtw
 SG_ APP_sw004_SmearedSpots m4 : 52|1@1+ (1,0) [0|1] ""  gtw
 SG_ APP_sw027_STM1 m27 : 52|1@1+ (1,0) [0|1] ""  gtw
 SG_ APP_sw053_a49tireSizeSanity m53 : 52|1@1+ (1,0) [0|1] ""  gtw
 SG_ APP_sw015_NarrowCameraLowLight m15 : 52|2@1+ (1,0) [0|3] ""  gtw
 SG_ APP_sw042_cam_SelfGlare m42 : 52|1@1+ (1,0) [0|1] ""  gtw
 SG_ APP_sw011_egoCentered m11 : 52|1@1+ (1,0) [0|1] ""  gtw
 SG_ APP_sw203_vehicleSkew m203 : 52|12@1+ (0.002,0) [0|8.19] "radians"  gtw
 SG_ APP_sw199_maxSpeed m199 : 52|8@1+ (0.1,-12.2) [-12.2|12.2] "mph"  gtw
 SG_ APP_sw011_polyValid m11 : 51|1@1+ (1,0) [0|1] ""  gtw
 SG_ APP_sw191_referenceHealth m191 : 51|2@1+ (1,0) [0|2] ""  gtw
 SG_ APP_sw042_cam_FoggySpots m42 : 51|1@1+ (1,0) [0|1] ""  gtw
 SG_ APP_sw060_RadarAssociationAge m60 : 51|4@1+ (100,0) [0|1500] "ms"  gtw
 SG_ APP_sw086_activeBraking m86 : 51|1@1+ (1,0) [0|1] ""  gtw
 SG_ APP_sw027_STM0 m27 : 51|1@1+ (1,0) [0|1] ""  gtw
 SG_ APP_sw053_a48steerAngOffSanity m53 : 51|1@1+ (1,0) [0|1] ""  gtw
 SG_ APP_sw006_camFcwPcwMsg m6 : 51|1@1+ (1,0) [0|1] ""  gtw
 SG_ APP_sw004_LowSun m4 : 51|1@1+ (1,0) [0|1] ""  gtw
 SG_ APP_sw042_cam_SmearedHalos m42 : 50|1@1+ (1,0) [0|1] ""  gtw
 SG_ APP_sw012_mespDDRTempStatus m12 : 50|3@1+ (1,0) [0|7] ""  gtw
 SG_ APP_sw004_BlurredImage m4 : 50|1@1+ (1,0) [0|1] ""  gtw
 SG_ APP_sw026_mob_mean_utilization m26 : 50|7@1+ (1,0) [0|127] "percent"  gtw
 SG_ APP_sw027_SW m27 : 50|1@1+ (1,0) [0|1] ""  gtw
 SG_ APP_sw015_MainCameraLowLight m15 : 50|2@1+ (1,0) [0|3] ""  gtw
 SG_ APP_sw080_cruise_lever_state m80 : 50|3@1+ (1,0) [0|7] ""  gtw
 SG_ APP_sw006_camCommonMsg m6 : 50|1@1+ (1,0) [0|1] ""  gtw
 SG_ APP_sw011_egoMovingLeft m11 : 50|1@1+ (1,0) [0|1] ""  gtw
 SG_ APP_sw053_a44yawValidity m53 : 50|1@1+ (1,0) [0|1] ""  gtw
 SG_ APP_sw080_min_speed_check m80 : 49|1@1+ (1,0) [0|1] ""  gtw
 SG_ APP_sw027_ESR1 m27 : 49|1@1+ (1,0) [0|1] ""  gtw
 SG_ APP_sw006_camObjHeader m6 : 49|1@1+ (1,0) [0|1] ""  gtw
 SG_ APP_sw011_egoLeftOfCenter m11 : 49|1@1+ (1,0) [0|1] ""  gtw
 SG_ APP_sw042_cam_FullBlock m42 : 49|1@1+ (1,0) [0|1] ""  gtw
 SG_ APP_sw273_timeToLaneExit m273 : 49|7@1+ (0.02,0) [0|2.53] "seconds"  gtw
 SG_ APP_sw004_Splashes m4 : 49|1@1+ (1,0) [0|1] ""  gtw
 SG_ APP_sw053_a43yawOffValidity m53 : 49|1@1+ (1,0) [0|1] ""  gtw
 SG_ APP_sw006_camWatchdog m6 : 48|1@1+ (1,0) [0|1] ""  gtw
 SG_ APP_sw280_minTemperature m280 : 48|8@1+ (1,-60) [-60|194] "degC"  gtw
 SG_ APP_sw277_minTemperature m277 : 48|8@1+ (1,-60) [-60|194] "degC"  gtw
 SG_ APP_sw001_APP_alertDataW2 m1 : 48|16@1+ (1,0) [0|65535] ""  gtw
 SG_ APP_sw055_expectedCrcLsw m55 : 48|16@1+ (1,0) [0|65535] ""  gtw
 SG_ APP_sw183_minTemperature m183 : 48|8@1+ (1,-60) [-60|194] "degC"  gtw
 SG_ APP_sw025_torsionBarTorque m25 : 48|8@1+ (0.1,-12.8) [-12.8|12.7] "Nm"  gtw
 SG_ APP_sw032_errorData2 m32 : 48|16@1+ (1,0) [0|65535] ""  gtw
 SG_ APP_sw077_oocUntrackedTime m77 : 48|6@1+ (0.1,0) [0|6.3] "s"  gtw
 SG_ APP_sw201_viewRangeOAL m201 : 48|3@1+ (1,0) [0|7] ""  gtw
 SG_ APP_sw103_distanceEllipse m103 : 48|8@1+ (0.5,0) [0|127.5] "m"  gtw
 SG_ APP_sw184_minTemperature m184 : 48|8@1+ (1,-60) [-60|194] "degC"  gtw
 SG_ APP_sw004_SunRay m4 : 48|1@1+ (1,0) [0|1] ""  gtw
 SG_ APP_sw190_minTemperature m190 : 48|8@1+ (1,-60) [-60|194] "degC"  gtw
 SG_ APP_sw189_minTemperature m189 : 48|8@1+ (1,-60) [-60|194] "degC"  gtw
 SG_ APP_sw051_unusedW1 m51 : 48|16@1+ (1,0) [0|65535] ""  gtw
 SG_ APP_sw037_unusedW1 m37 : 48|16@1+ (1,0) [0|65535] ""  gtw
 SG_ APP_sw034_unusedW1 m34 : 48|16@1+ (1,0) [0|65535] ""  gtw
 SG_ APP_sw016_hostLongAccel m16 : 48|7@1+ (0.15625,-10) [-10|10] "m/s^2"  gtw
 SG_ APP_sw080_cipv_valid m80 : 48|1@1+ (1,0) [0|1] ""  gtw
 SG_ APP_sw075_unusedW1 m75 : 48|16@1+ (1,0) [0|65535] ""  gtw
 SG_ APP_sw053_a42xwdValidity m53 : 48|1@1+ (1,0) [0|1] ""  gtw
 SG_ APP_sw204_frRightMiddle m204 : 48|8@1+ (1,0) [0|255] "cm"  gtw
 SG_ APP_sw258_ego_acceleration m258 : 48|8@1+ (0.1,-15.5) [-15.5|10] "m/s2"  gtw
 SG_ APP_sw058_unusedW1 m58 : 48|16@1+ (1,0) [0|65535] ""  gtw
 SG_ APP_sw014_assertData m14 : 48|16@1+ (1,0) [0|65535] ""  gtw
 SG_ APP_sw274_minTemperature m274 : 48|8@1+ (1,-60) [-60|194] "degC"  gtw
 SG_ APP_sw263_laneWidth m263 : 48|7@1+ (0.05,0) [0|6.375] "m"  gtw
 SG_ APP_sw205_rrRight m205 : 48|8@1+ (1,0) [0|255] "cm"  gtw
 SG_ APP_sw259_unusedB02 m259 : 48|8@1+ (1,0) [0|255] ""  gtw
 SG_ APP_sw047_edrStateMachine m47 : 48|8@1+ (1,0) [0|255] ""  gtw
 SG_ APP_sw185_minTemperature m185 : 48|8@1+ (1,-60) [-60|194] "degC"  gtw
 SG_ APP_sw054_unusedW0 m54 : 48|16@1+ (1,0) [0|65535] ""  gtw
 SG_ APP_sw066_unusedW1 m66 : 48|16@1+ (1,0) [0|65535] ""  gtw
 SG_ APP_sw072_endDistance m72 : 48|8@1+ (1,0) [0|255] "cm"  gtw
 SG_ APP_sw027_ESR0 m27 : 48|1@1+ (1,0) [0|1] ""  gtw
 SG_ APP_sw013_highestSeqRecd m13 : 48|12@1+ (1,0) [0|4095] ""  gtw
 SG_ APP_sw065_unusedW1 m65 : 48|16@1+ (1,0) [0|65535] ""  gtw
 SG_ APP_sw011_egoMovingRight m11 : 48|1@1+ (1,0) [0|1] ""  gtw
 SG_ APP_sw063_expectedSubMinorVer m63 : 48|8@1+ (1,0) [0|255] ""  gtw
 SG_ APP_sw078_radarTarg1_dx m78 : 48|8@1+ (0.0625,0) [0|15.9375] "m"  gtw
 SG_ APP_sw186_minTemperature m186 : 48|8@1+ (1,-60) [-60|194] "degC"  gtw
 SG_ APP_sw042_cam_AutofixYaw m42 : 48|1@1+ (1,0) [0|1] ""  gtw
 SG_ APP_sw081_pedalPosition m81 : 48|7@1+ (1,0) [0|127] "%"  gtw
 SG_ APP_sw082_road_class m82 : 48|3@1+ (1,0) [0|7] ""  gtw
 SG_ APP_sw020_unusedW2 m20 : 48|16@1+ (1,0) [0|65535] ""  gtw
 SG_ APP_sw076_hostLongAccel m76 : 48|7@1+ (0.15625,-10) [-10|10] "m/s^2"  gtw
 SG_ APP_sw278_minTemperature m278 : 48|8@1+ (1,-60) [-60|194] "degC"  gtw
 SG_ APP_sw073_freespaceRightC1 m73 : 48|8@1+ (0.0016,-0.2) [-0.2|0.2] "rad"  gtw
 SG_ APP_sw275_minTemperature m275 : 48|8@1+ (1,-60) [-60|194] "degC"  gtw
 SG_ APP_sw282_minTemperature m282 : 48|8@1+ (1,-60) [-60|194] "degC"  gtw
 SG_ APP_sw260_driver_reaction_time m260 : 48|8@1+ (0.02,0) [0|5.1] "s"  gtw
 SG_ APP_sw017_highestSeqRecd m17 : 48|12@1+ (1,0) [0|4095] ""  gtw
 SG_ APP_sw269_laneDepartureWarning m269 : 48|4@1+ (1,0) [0|15] ""  gtw
 SG_ APP_sw276_minTemperature m276 : 48|8@1+ (1,-60) [-60|194] "degC"  gtw
 SG_ APP_sw049_ffs_version_msw m49 : 48|16@1+ (1,0) [0|65535] ""  gtw
 SG_ APP_sw281_minTemperature m281 : 48|8@1+ (1,-60) [-60|194] "degC"  gtw
 SG_ APP_sw043_camLongRunTime_unused m43 : 48|16@1+ (1,0) [0|65535] ""  gtw
 SG_ APP_sw182_minTemperature m182 : 48|8@1+ (1,-60) [-60|194] "degC"  gtw
 SG_ APP_sw015_OutOfFocusImage m15 : 48|2@1+ (1,0) [0|3] ""  gtw
 SG_ APP_sw031_errorData2 m31 : 48|16@1+ (1,0) [0|65535] ""  gtw
 SG_ APP_sw039_unusedW1 m39 : 48|16@1+ (1,0) [0|65535] ""  gtw
 SG_ APP_sw187_minTemperature m187 : 48|8@1+ (1,-60) [-60|194] "degC"  gtw
 SG_ APP_sw040_torsion_bar_torque m40 : 48|8@1+ (0.1,-12.8) [-12.8|12.7] "Nm"  gtw
 SG_ APP_sw188_minTemperature m188 : 48|8@1+ (1,-60) [-60|194] "degC"  gtw
 SG_ APP_sw028_multifrm_rx_len m28 : 48|16@1+ (1,0) [0|65535] ""  gtw
 SG_ APP_sw050_hostLongAccel m50 : 48|7@1+ (0.15625,-10) [-10|10] "m/s^2"  gtw
 SG_ APP_sw083_Targ5_dz m83 : 48|6@1+ (0.25,-5) [-5|10.75] "m"  gtw
 SG_ APP_sw086_ellipseAge m86 : 48|3@1+ (1,0) [0|7] ""  gtw
 SG_ APP_sw036_unusedW1 m36 : 48|16@1+ (1,0) [0|65535] ""  gtw
 SG_ APP_sw062_VmaPlausibility m62 : 48|16@1+ (1.52587890625005e-05,0) [0|0.99998474121097] "FIXME"  gtw
 SG_ APP_sw191_roadClass m191 : 48|3@1+ (1,0) [0|6] ""  gtw
 SG_ APP_sw279_minTemperature m279 : 48|8@1+ (1,-60) [-60|194] "degC"  gtw
 SG_ APP_sw071_temperature m71 : 48|8@1+ (0.5,-40) [-40|87.5] "C"  gtw
 SG_ APP_sw074_ipsoConfidence m74 : 48|6@1+ (2,0) [0|126] "percent"  gtw
 SG_ APP_sw257_driver_reaction_time m257 : 48|8@1+ (0.02,0) [0|5.1] "s"  gtw
 SG_ APP_sw018_currentVoltage m18 : 48|16@1+ (1,0) [0|6600] "mV"  gtw
 SG_ APP_sw010_VmaPlausibility m10 : 48|16@1+ (1.52587890625005e-05,0) [0|0.99998474121097] "FIXME"  gtw
 SG_ APP_sw199_internalState m199 : 48|4@1+ (1,0) [0|15] ""  gtw
 SG_ APP_sw029_unusedW1 m29 : 48|16@1+ (1,0) [0|65535] ""  gtw
 SG_ APP_sw194_timeInHold m194 : 48|16@1+ (1,0) [0|65535] ""  gtw
 SG_ APP_sw030_unusedW1 m30 : 48|16@1+ (1,0) [0|65535] ""  gtw
 SG_ APP_sw021_unusedWord m21 : 48|16@1+ (1,0) [0|65535] ""  gtw
 SG_ APP_sw056_unusedW1 m56 : 48|16@1+ (1,0) [0|65535] ""  gtw
 SG_ APP_sw018_railControl m18 : 47|1@1+ (1,0) [0|1] ""  gtw
 SG_ APP_sw011_egoRightOfCenter m11 : 47|1@1+ (1,0) [0|1] ""  gtw
 SG_ APP_sw085_averageSpeedHist m85 : 47|6@1+ (0.25,0) [0|16] "mps"  gtw
 SG_ APP_sw053_a41wiperValidity m53 : 47|1@1+ (1,0) [0|1] ""  gtw
 SG_ APP_sw004_ImpairedVD m4 : 47|1@1+ (1,0) [0|1] ""  gtw
 SG_ APP_sw060_hostLongAccel m60 : 47|4@1+ (1,-7.5) [-7.5|7.5] "m/s^2"  gtw
 SG_ APP_sw006_speedDerivative m6 : 47|1@1+ (1,0) [0|1] ""  gtw
 SG_ APP_sw042_cam_AutofixHorizon m42 : 47|1@1+ (1,0) [0|1] ""  gtw
 SG_ APP_sw069_drivingLaneLeft m69 : 46|8@1+ (1,0) [0|255] ""  gtw
 SG_ APP_sw015_SelfGlare m15 : 46|2@1+ (1,0) [0|3] ""  gtw
 SG_ APP_sw145_camExtRollCal m145 : 46|9@1+ (0.05,-12.5) [-12.5|12.5] "deg"  gtw
 SG_ APP_sw004_OutOfFocusImage m4 : 46|1@1+ (1,0) [0|1] ""  gtw
 SG_ APP_sw006_dasDisabled m6 : 46|1@1+ (1,0) [0|1] ""  gtw
 SG_ APP_sw041_unusedW2 m41 : 46|18@1+ (1,0) [0|262143] ""  gtw
 SG_ APP_sw042_cam_Autofix m42 : 46|1@1+ (1,0) [0|1] ""  gtw
 SG_ APP_sw053_a40whlStndStllValidty m53 : 46|1@1+ (1,0) [0|1] ""  gtw
 SG_ APP_sw010_unusedBits m10 : 46|2@1+ (1,0) [0|3] ""  gtw
 SG_ APP_sw042_cam_PartialBlock m42 : 45|1@1+ (1,0) [0|1] ""  gtw
 SG_ APP_sw006_stabilityControl m6 : 45|1@1+ (1,0) [0|1] ""  gtw
 SG_ APP_sw143_targetRelAcceleration m143 : 45|8@1+ (0.1,-12.8) [-12.8|12.7] "m/s2"  gtw
 SG_ APP_sw004_RadarMisalignment m4 : 45|1@1+ (1,0) [0|1] ""  gtw
 SG_ APP_sw053_a39whlSpdValidity m53 : 45|1@1+ (1,0) [0|1] ""  gtw
 SG_ APP_sw231_targetRelAcceleration m231 : 45|8@1+ (0.1,-12.8) [-12.8|12.7] "m/s2"  gtw
 SG_ APP_sw053_a38whlRotValidity m53 : 44|1@1+ (1,0) [0|1] ""  gtw
 SG_ APP_sw067_vehSpeed m67 : 44|12@1+ (0.1,-50) [-50|359.6] "kph"  gtw
 SG_ APP_sw269_blindspot m269 : 44|4@1+ (1,0) [0|15] ""  gtw
 SG_ APP_sw006_gear m6 : 44|1@1+ (1,0) [0|1] ""  gtw
 SG_ APP_sw042_cam_SmearedSpots m42 : 44|1@1+ (1,0) [0|1] ""  gtw
 SG_ APP_sw194_reasonForHold m194 : 44|4@1+ (1,0) [0|15] ""  gtw
 SG_ APP_sw005_RadarLowVisibility m5 : 44|1@1+ (1,0) [0|1] ""  gtw
 SG_ APP_sw259_unusedN01 m259 : 44|4@1+ (1,0) [0|15] ""  gtw
 SG_ APP_sw004_RadarLowVisibility m4 : 44|1@1+ (1,0) [0|1] ""  gtw
 SG_ APP_sw071_airSuspension m71 : 44|3@1+ (1,0) [0|7] ""  gtw
 SG_ APP_sw015_ImpairedVD m15 : 44|2@1+ (1,0) [0|3] ""  gtw
 SG_ APP_sw080_ego_speed m80 : 43|5@1+ (1,0) [0|31] "mph"  gtw
 SG_ APP_sw053_a37vinValidity m53 : 43|1@1+ (1,0) [0|1] ""  gtw
 SG_ APP_sw042_cam_LowSun m42 : 43|1@1+ (1,0) [0|1] ""  gtw
 SG_ APP_sw006_speed m6 : 43|1@1+ (1,0) [0|1] ""  gtw
 SG_ APP_sw026_uds_mean_utilization m26 : 43|7@1+ (1,0) [0|127] "percent"  gtw
 SG_ APP_sw071_driverPresent m71 : 43|1@1+ (1,0) [0|1] ""  gtw
 SG_ APP_sw004_CamWatchdog m4 : 43|1@1+ (1,0) [0|1] ""  gtw
 SG_ APP_sw005_AutofixOutOfCalibHorzn m5 : 43|1@1+ (1,0) [0|1] ""  gtw
 SG_ APP_sw062_unusedBits m62 : 42|6@1+ (1,0) [0|63] ""  gtw
 SG_ APP_sw042_cam_BlurredImage m42 : 42|1@1+ (1,0) [0|1] ""  gtw
 SG_ APP_sw053_a36vehStndStllValidty m53 : 42|1@1+ (1,0) [0|1] ""  gtw
 SG_ APP_sw006_steeringAngleRate m6 : 42|1@1+ (1,0) [0|1] ""  gtw
 SG_ APP_sw012_mespFatalErrDetails m12 : 42|8@1+ (1,0) [0|255] ""  gtw
 SG_ APP_sw069_roadClass m69 : 42|4@1+ (1,0) [0|15] ""  gtw
 SG_ APP_sw015_SunRay m15 : 42|2@1+ (1,0) [0|3] ""  gtw
 SG_ APP_sw004_CamObjectsMIA m4 : 42|1@1+ (1,0) [0|1] ""  gtw
 SG_ APP_sw005_camWatchdog m5 : 42|1@1+ (1,0) [0|1] ""  gtw
 SG_ APP_sw085_rightLaneExist m85 : 41|6@1+ (2,0) [0|128] "%"  gtw
 SG_ APP_sw005_speedDerivative m5 : 41|1@1+ (1,0) [0|1] ""  gtw
 SG_ APP_sw004_CamCommonMIA m4 : 41|1@1+ (1,0) [0|1] ""  gtw
 SG_ APP_sw053_a35indctrValidity m53 : 41|1@1+ (1,0) [0|1] ""  gtw
 SG_ APP_sw273_latDistanceToVehicle m273 : 41|8@1+ (0.02,0) [0|5.11] "meters"  gtw
 SG_ APP_sw042_cam_RoadSpray m42 : 41|1@1+ (1,0) [0|1] ""  gtw
 SG_ APP_sw203_startDistance m203 : 41|11@1+ (1,0) [0|2047] "cm"  gtw
 SG_ APP_sw006_steeringAngle m6 : 41|1@1+ (1,0) [0|1] ""  gtw
 SG_ APP_sw027_Unused_Byte m27 : 40|8@1+ (1,0) [0|255] ""  gtw
 SG_ APP_sw068_navigationSTW m68 : 40|14@1+ (0.1,-819.2) [-819.2|819.2] "deg"  gtw
 SG_ APP_sw274_currentTemperature m274 : 40|8@1+ (1,-60) [-60|194] "degC"  gtw
 SG_ APP_sw227_ambientTemperature m227 : 40|8@1+ (0.5,-40) [-40|87.5] "C"  gtw
 SG_ APP_sw187_currentTemperature m187 : 40|8@1+ (1,-60) [-60|194] "degC"  gtw
 SG_ APP_sw005_dasDisabled m5 : 40|1@1+ (1,0) [0|1] ""  gtw
 SG_ APP_sw081_cameraTTC m81 : 40|8@1+ (0.02,0) [0|5.11] "seconds"  gtw
 SG_ APP_sw076_hostSpeed m76 : 40|8@1+ (1,0) [0|255] "kph"  gtw
 SG_ APP_sw021_currentTemperature m21 : 40|8@1- (1,0) [-128|127] "degC"  gtw
 SG_ APP_sw149_diskUsageAutopilot m149 : 40|8@1+ (1,0) [0|255] "percent"  gtw
 SG_ APP_sw257_ego_speed m257 : 40|8@1+ (0.2,0) [0|51] "m/s"  gtw
 SG_ APP_sw189_currentTemperature m189 : 40|8@1+ (1,-60) [-60|194] "degC"  gtw
 SG_ APP_sw063_detectedMinorVer m63 : 40|8@1+ (1,0) [0|255] ""  gtw
 SG_ APP_sw190_currentTemperature m190 : 40|8@1+ (1,-60) [-60|194] "degC"  gtw
 SG_ APP_sw071_roadClass m71 : 40|3@1+ (1,0) [0|7] ""  gtw
 SG_ APP_sw017_numTransportErrors m17 : 40|8@1+ (1,0) [0|255] ""  gtw
 SG_ APP_sw194_numPedstrian m194 : 40|4@1+ (1,0) [0|15] ""  gtw
 SG_ APP_sw278_currentTemperature m278 : 40|8@1+ (1,-60) [-60|194] "degC"  gtw
 SG_ APP_sw016_hostSpeed m16 : 40|8@1+ (1,0) [0|255] "kph"  gtw
 SG_ APP_sw053_a34steerAngSpdValidity m53 : 40|1@1+ (1,0) [0|1] ""  gtw
 SG_ APP_sw171_APP_pascalExtTemp m171 : 40|8@1+ (1,-128) [-128|127] "C"  gtw
 SG_ APP_sw263_speed m263 : 40|8@1+ (1,0) [0|255] "kph"  gtw
 SG_ APP_sw280_currentTemperature m280 : 40|8@1+ (1,-60) [-60|194] "degC"  gtw
 SG_ APP_sw277_currentTemperature m277 : 40|8@1+ (1,-60) [-60|194] "degC"  gtw
 SG_ APP_sw004_appMobileyeNotInVision m4 : 40|1@1+ (1,0) [0|1] ""  gtw
 SG_ APP_sw183_currentTemperature m183 : 40|8@1+ (1,-60) [-60|194] "degC"  gtw
 SG_ APP_sw202_vehicleSpeed m202 : 40|12@1+ (0.1,0) [0|409.6] "kph"  gtw
 SG_ APP_sw199_currentSpeed m199 : 40|8@1+ (0.1,-12.2) [-12.2|12.2] "mph"  gtw
 SG_ APP_sw205_rrMiddle m205 : 40|8@1+ (1,0) [0|255] "cm"  gtw
 SG_ APP_sw051_unusedB0 m51 : 40|8@1+ (1,0) [0|255] ""  gtw
 SG_ APP_sw186_currentTemperature m186 : 40|8@1+ (1,-60) [-60|194] "degC"  gtw
 SG_ APP_sw195_vehicleSpeed m195 : 40|12@1+ (0.1,0) [0|409.6] "kph"  gtw
 SG_ APP_sw070_currentSpeed m70 : 40|12@1+ (0.1,-204.7) [-204.7|204.8] "mph"  gtw
 SG_ APP_sw260_ego_speed m260 : 40|8@1+ (0.2,0) [0|51] "m/s"  gtw
 SG_ APP_sw082_R_Lane m82 : 40|8@1+ (0.05,-6.4) [-6.4|6.35] "m"  gtw
 SG_ APP_sw025_offsetSide m25 : 40|2@1+ (1,0) [0|3] ""  gtw
 SG_ APP_sw015_FoggyLights m15 : 40|2@1+ (1,0) [0|3] ""  gtw
 SG_ APP_sw185_currentTemperature m185 : 40|8@1+ (1,-60) [-60|194] "degC"  gtw
 SG_ APP_sw259_previous_lcm_app_state m259 : 40|4@1+ (1,0) [0|10] ""  gtw
 SG_ APP_sw084_ipsoDy m84 : 40|8@1+ (0.1,-12.6) [-12.6|12.9] "meters"  gtw
 SG_ APP_sw074_ipsoRCS m74 : 40|8@1+ (1,0) [0|255] "dB"  gtw
 SG_ APP_sw013_numNaksReceived m13 : 40|8@1+ (1,0) [0|255] ""  gtw
 SG_ APP_sw078_radarTarg5_VxRel m78 : 40|8@1+ (0.2,-25.6) [-25.6|25.4] "m/s"  gtw
 SG_ APP_sw042_cam_SunRay m42 : 40|1@1+ (1,0) [0|1] ""  gtw
 SG_ APP_sw188_currentTemperature m188 : 40|8@1+ (1,-60) [-60|194] "degC"  gtw
 SG_ APP_sw191_viewRange m191 : 40|8@1+ (1,0) [0|255] "m"  gtw
 SG_ APP_sw281_currentTemperature m281 : 40|8@1+ (1,-60) [-60|194] "degC"  gtw
 SG_ APP_sw182_currentTemperature m182 : 40|8@1+ (1,-60) [-60|194] "degC"  gtw
 SG_ APP_sw276_currentTemperature m276 : 40|8@1+ (1,-60) [-60|194] "degC"  gtw
 SG_ APP_sw006_brakePedal m6 : 40|1@1+ (1,0) [0|1] ""  gtw
 SG_ APP_sw282_currentTemperature m282 : 40|8@1+ (1,-60) [-60|194] "degC"  gtw
 SG_ APP_sw073_freespaceLeftC1 m73 : 40|8@1+ (0.0016,-0.2) [-0.2|0.2] "rad"  gtw
 SG_ APP_sw040_epas_internal_sas m40 : 40|8@1+ (1,-128) [-128|127] "deg"  gtw
 SG_ APP_sw275_currentTemperature m275 : 40|8@1+ (1,-60) [-60|194] "degC"  gtw
 SG_ APP_sw184_currentTemperature m184 : 40|8@1+ (1,-60) [-60|194] "degC"  gtw
 SG_ APP_sw141_temperature m141 : 40|8@1- (1,0) [-128|127] "degC"  gtw
 SG_ APP_sw269_laneKeepAssist m269 : 40|4@1+ (1,0) [0|15] ""  gtw
 SG_ APP_sw201_vehSpeed m201 : 40|8@1+ (1,0) [0|255] "kph"  gtw
 SG_ APP_sw086_ellipseOverlap m86 : 40|8@1+ (0.1,-12.5) [-12.5|12.5] "m"  gtw
 SG_ APP_sw054_unusedByte m54 : 40|8@1+ (1,0) [0|255] ""  gtw
 SG_ APP_sw204_frRight m204 : 40|8@1+ (1,0) [0|255] "cm"  gtw
 SG_ APP_sw258_ego_speed m258 : 40|8@1+ (0.2,0) [0|51] "m/s"  gtw
 SG_ APP_sw050_hostSpeed m50 : 40|8@1+ (1,0) [0|255] "kph"  gtw
 SG_ APP_sw060_hostSpeed m60 : 40|7@1+ (2,0) [0|254] "kph"  gtw
 SG_ APP_sw080_road_class m80 : 40|3@1+ (1,0) [0|7] ""  gtw
 SG_ APP_sw279_currentTemperature m279 : 40|8@1+ (1,-60) [-60|194] "degC"  gtw
 SG_ APP_sw103_objectDz m103 : 40|8@1+ (0.25,-5) [-5|10.75] "m"  gtw
 SG_ APP_sw143_targetRelVelocity m143 : 39|6@1+ (0.5,0) [0|31.5] "m/s"  gtw
 SG_ APP_sw004_DASFeaturesDisabled m4 : 39|1@1+ (1,0) [0|1] ""  gtw
 SG_ APP_sw231_targetRelVelocity m231 : 39|6@1+ (0.5,0) [0|31.5] "m/s"  gtw
 SG_ APP_sw053_a33steerAngValidity m53 : 39|1@1+ (1,0) [0|1] ""  gtw
 SG_ APP_sw005_fcmSensitivity m5 : 39|1@1+ (1,0) [0|1] ""  gtw
 SG_ APP_sw202_sdiSystemStatus m202 : 39|1@1+ (1,0) [0|1] ""  gtw
 SG_ APP_sw027_Unused_Bit_4 m27 : 39|1@1+ (1,0) [0|1] ""  gtw
 SG_ APP_sw006_radSGUFailure m6 : 39|1@1+ (1,0) [0|1] ""  gtw
 SG_ APP_sw195_sdiSystemStatus m195 : 39|1@1+ (1,0) [0|1] ""  gtw
 SG_ APP_sw015_SmearedHalos m15 : 38|2@1+ (1,0) [0|3] ""  gtw
 SG_ APP_sw027_LVD_2v7_IO m27 : 38|1@1+ (1,0) [0|1] ""  gtw
 SG_ APP_sw265_rRepeaterLanesFailsafe m265 : 38|1@1+ (1,0) [0|1] ""  gtw
 SG_ APP_sw053_a32gearValidity m53 : 38|1@1+ (1,0) [0|1] ""  gtw
 SG_ APP_sw025_bottsDotsUsage m25 : 38|2@1+ (1,0) [0|3] ""  gtw
 SG_ APP_sw006_radSensorBlind m6 : 38|1@1+ (1,0) [0|1] ""  gtw
 SG_ APP_sw004_diSpeedInvalid m4 : 38|1@1+ (1,0) [0|1] ""  gtw
 SG_ APP_sw005_accelPedal m5 : 38|1@1+ (1,0) [0|1] ""  gtw
 SG_ APP_sw265_lRepeaterLanesFailsafe m265 : 37|1@1+ (1,0) [0|1] ""  gtw
 SG_ APP_sw279_numCaptureRecoveries m279 : 37|3@1+ (1,0) [0|7] ""  gtw
 SG_ APP_sw274_numCaptureRecoveries m274 : 37|3@1+ (1,0) [0|7] ""  gtw
 SG_ APP_sw183_numCaptureRecoveries m183 : 37|3@1+ (1,0) [0|7] ""  gtw
 SG_ APP_sw011_scaSteerAngle m11 : 37|10@1+ (0.1,-51.2) [-51.2|51.1] "deg"  gtw
 SG_ APP_sw277_numCaptureRecoveries m277 : 37|3@1+ (1,0) [0|7] ""  gtw
 SG_ APP_sw280_numCaptureRecoveries m280 : 37|3@1+ (1,0) [0|7] ""  gtw
 SG_ APP_sw186_numCaptureRecoveries m186 : 37|3@1+ (1,0) [0|7] ""  gtw
 SG_ APP_sw190_numCaptureRecoveries m190 : 37|3@1+ (1,0) [0|7] ""  gtw
 SG_ APP_sw189_numCaptureRecoveries m189 : 37|3@1+ (1,0) [0|7] ""  gtw
 SG_ APP_sw004_accelerationInvalid m4 : 37|1@1+ (1,0) [0|1] ""  gtw
 SG_ APP_sw278_numCaptureRecoveries m278 : 37|3@1+ (1,0) [0|7] ""  gtw
 SG_ APP_sw281_numCaptureRecoveries m281 : 37|3@1+ (1,0) [0|7] ""  gtw
 SG_ APP_sw276_numCaptureRecoveries m276 : 37|3@1+ (1,0) [0|7] ""  gtw
 SG_ APP_sw182_numCaptureRecoveries m182 : 37|3@1+ (1,0) [0|7] ""  gtw
 SG_ APP_sw185_numCaptureRecoveries m185 : 37|3@1+ (1,0) [0|7] ""  gtw
 SG_ APP_sw053_a31odoValidity m53 : 37|1@1+ (1,0) [0|1] ""  gtw
 SG_ APP_sw006_radHWFailure m6 : 37|1@1+ (1,0) [0|1] ""  gtw
 SG_ APP_sw188_numCaptureRecoveries m188 : 37|3@1+ (1,0) [0|7] ""  gtw
 SG_ APP_sw202_sdiSystemNoise m202 : 37|2@1+ (1,0) [0|3] ""  gtw
 SG_ APP_sw195_sdiSystemNoise m195 : 37|2@1+ (1,0) [0|3] ""  gtw
 SG_ APP_sw027_LVD_2v7_Flash m27 : 37|1@1+ (1,0) [0|1] ""  gtw
 SG_ APP_sw145_camExtYawCal m145 : 37|9@1+ (0.05,-12.5) [-12.5|12.5] "deg"  gtw
 SG_ APP_sw282_numCaptureRecoveries m282 : 37|3@1+ (1,0) [0|7] ""  gtw
 SG_ APP_sw077_vehicleSpeed m77 : 37|10@1+ (0.05,-25) [-25|26.15] "MPH"  gtw
 SG_ APP_sw005_longAccel m5 : 37|1@1+ (1,0) [0|1] ""  gtw
 SG_ APP_sw275_numCaptureRecoveries m275 : 37|3@1+ (1,0) [0|7] ""  gtw
 SG_ APP_sw184_numCaptureRecoveries m184 : 37|3@1+ (1,0) [0|7] ""  gtw
 SG_ APP_sw187_numCaptureRecoveries m187 : 37|3@1+ (1,0) [0|7] ""  gtw
 SG_ APP_sw281_deserLineLengthError m281 : 36|1@1+ (1,0) [0|1] ""  gtw
 SG_ APP_sw182_deserLineLengthError m182 : 36|1@1+ (1,0) [0|1] ""  gtw
 SG_ APP_sw006_radMia m6 : 36|1@1+ (1,0) [0|1] ""  gtw
 SG_ APP_sw276_deserLineLengthError m276 : 36|1@1+ (1,0) [0|1] ""  gtw
 SG_ APP_sw185_deserLineLengthError m185 : 36|1@1+ (1,0) [0|1] ""  gtw
 SG_ APP_sw188_deserLineLengthError m188 : 36|1@1+ (1,0) [0|1] ""  gtw
 SG_ APP_sw027_LVD_2v7_VREG m27 : 36|1@1+ (1,0) [0|1] ""  gtw
 SG_ APP_sw025_modelUsage m25 : 36|2@1+ (1,0) [0|3] ""  gtw
 SG_ APP_sw072_vehicleHeading m72 : 36|10@1+ (0.005,-2.56) [-2.56|2.55] "rad"  gtw
 SG_ APP_sw026_can_mean_utilization m26 : 36|7@1+ (1,0) [0|127] "percent"  gtw
 SG_ APP_sw041_ego_speed m41 : 36|10@1+ (0.05,0) [0|51.15] "m/s"  gtw
 SG_ APP_sw275_deserLineLengthError m275 : 36|1@1+ (1,0) [0|1] ""  gtw
 SG_ APP_sw282_deserLineLengthError m282 : 36|1@1+ (1,0) [0|1] ""  gtw
 SG_ APP_sw184_deserLineLengthError m184 : 36|1@1+ (1,0) [0|1] ""  gtw
 SG_ APP_sw005_yaw m5 : 36|1@1+ (1,0) [0|1] ""  gtw
 SG_ APP_sw187_deserLineLengthError m187 : 36|1@1+ (1,0) [0|1] ""  gtw
 SG_ APP_sw004_stwAngleInvalid m4 : 36|1@1+ (1,0) [0|1] ""  gtw
 SG_ APP_sw042_epas_error_code m42 : 36|4@1+ (1,0) [0|15] ""  gtw
 SG_ APP_sw010_VerticalMisalignment m10 : 36|10@1+ (0.087977,-45) [-45|45.000471] "deg"  gtw
 SG_ APP_sw279_deserLineLengthError m279 : 36|1@1+ (1,0) [0|1] ""  gtw
 SG_ APP_sw274_deserLineLengthError m274 : 36|1@1+ (1,0) [0|1] ""  gtw
 SG_ APP_sw015_SmearedSpots m15 : 36|2@1+ (1,0) [0|3] ""  gtw
 SG_ APP_sw183_deserLineLengthError m183 : 36|1@1+ (1,0) [0|1] ""  gtw
 SG_ APP_sw277_deserLineLengthError m277 : 36|1@1+ (1,0) [0|1] ""  gtw
 SG_ APP_sw053_a30longAccValidity m53 : 36|1@1+ (1,0) [0|1] ""  gtw
 SG_ APP_sw280_deserLineLengthError m280 : 36|1@1+ (1,0) [0|1] ""  gtw
 SG_ APP_sw186_deserLineLengthError m186 : 36|1@1+ (1,0) [0|1] ""  gtw
 SG_ APP_sw194_numObstacles m194 : 36|4@1+ (1,0) [0|15] ""  gtw
 SG_ APP_sw189_deserLineLengthError m189 : 36|1@1+ (1,0) [0|1] ""  gtw
 SG_ APP_sw190_deserLineLengthError m190 : 36|1@1+ (1,0) [0|1] ""  gtw
 SG_ APP_sw265_rPillarLanesFailsafe m265 : 36|1@1+ (1,0) [0|1] ""  gtw
 SG_ APP_sw278_deserLineLengthError m278 : 36|1@1+ (1,0) [0|1] ""  gtw
 SG_ APP_sw263_side m263 : 35|1@1+ (1,0) [0|1] ""  gtw
 SG_ APP_sw077_oocHeight m77 : 35|2@1+ (1,0) [0|3] ""  gtw
 SG_ APP_sw027_Unused_Bit_3 m27 : 35|1@1+ (1,0) [0|1] ""  gtw
 SG_ APP_sw053_a29longAccOffValidity m53 : 35|1@1+ (1,0) [0|1] ""  gtw
 SG_ APP_sw140_backupCamHDMISerFault m140 : 35|1@1+ (1,0) [0|1] ""  gtw
 SG_ APP_sw265_lPillarLanesFailsafe m265 : 35|1@1+ (1,0) [0|1] ""  gtw
 SG_ APP_sw005_blinkers m5 : 35|1@1+ (1,0) [0|1] ""  gtw
 SG_ APP_sw085_leftLaneExist m85 : 35|6@1+ (2,0) [0|128] "%"  gtw
 SG_ APP_sw006_accelPedal m6 : 35|1@1+ (1,0) [0|1] ""  gtw
 SG_ APP_sw004_accelPedalInvalid m4 : 35|1@1+ (1,0) [0|1] ""  gtw
 SG_ APP_sw177_fisheyeCamExtYawCal m177 : 34|9@1- (0.05,0.0) [-12.5|12.5] "deg"  gtw
 SG_ APP_sw012_mespFatalErrCode m12 : 34|8@1+ (1,0) [0|255] ""  gtw
 SG_ APP_sw265_exceptionListInvalid m265 : 34|1@1+ (1,0) [0|1] ""  gtw
 SG_ APP_sw016_targetOverlap m16 : 34|6@1+ (0.1,0) [0|6.3] "m"  gtw
 SG_ APP_sw180_lRepeatCamExtYawCal m180 : 34|9@1- (0.05,0.0) [-12.5|12.5] "deg"  gtw
 SG_ APP_sw025_navigationUsage m25 : 34|2@1+ (1,0) [0|3] ""  gtw
 SG_ APP_sw179_rPillarCamExtYawCal m179 : 34|9@1- (0.05,0.0) [-12.5|12.5] "deg"  gtw
 SG_ APP_sw131_mainCamExtYawCal m131 : 34|9@1- (0.05,0.0) [-12.5|12.5] "deg"  gtw
 SG_ APP_sw015_Splashes m15 : 34|2@1+ (1,0) [0|3] ""  gtw
 SG_ APP_sw005_stabilityControl m5 : 34|1@1+ (1,0) [0|1] ""  gtw
 SG_ APP_sw006_seatbelt m6 : 34|1@1+ (1,0) [0|1] ""  gtw
 SG_ APP_sw142_problemCamPosition m142 : 34|4@1+ (1,0) [0|15] ""  gtw
 SG_ APP_sw053_a28espValidity m53 : 34|1@1+ (1,0) [0|1] ""  gtw
 SG_ APP_sw060_targetOverlap m60 : 34|6@1+ (0.1,0) [0|6.3] "m"  gtw
 SG_ APP_sw051_unusedBits m51 : 34|6@1+ (1,0) [0|63] ""  gtw
 SG_ APP_sw004_diMIA m4 : 34|1@1+ (1,0) [0|1] ""  gtw
 SG_ APP_sw076_targetOverlap m76 : 34|6@1+ (0.1,0) [0|6.3] "m"  gtw
 SG_ APP_sw027_Watchdog m27 : 34|1@1+ (1,0) [0|1] ""  gtw
 SG_ APP_sw132_narrowCamExtYawCal m132 : 34|9@1- (0.05,0.0) [-12.5|12.5] "deg"  gtw
 SG_ APP_sw050_targetOverlap m50 : 34|6@1+ (0.1,0) [0|6.3] "m"  gtw
 SG_ APP_sw178_lPillarCamExtYawCal m178 : 34|9@1- (0.05,0.0) [-12.5|12.5] "deg"  gtw
 SG_ APP_sw181_rRepeatCamExtYawCal m181 : 34|9@1- (0.05,0.0) [-12.5|12.5] "deg"  gtw
 SG_ APP_sw269_emergencyLaneKeep m269 : 34|4@1+ (1,0) [0|15] ""  gtw
 SG_ APP_sw027_Unused_Bit_2 m27 : 33|1@1+ (1,0) [0|1] ""  gtw
 SG_ APP_sw005_gear m5 : 33|1@1+ (1,0) [0|1] ""  gtw
 SG_ APP_sw006_blinkers m6 : 33|1@1+ (1,0) [0|1] ""  gtw
 SG_ APP_sw051_SGUFail m51 : 33|1@1+ (1,0) [0|1] ""  gtw
 SG_ APP_sw004_diCruiseStateFault m4 : 33|1@1+ (1,0) [0|1] ""  gtw
 SG_ APP_sw269_rRepeaterLanesFailsafe m269 : 33|1@1+ (1,0) [0|1] ""  gtw
 SG_ APP_sw203_slotSizeY m203 : 33|8@1+ (4,0) [0|1020] "cm"  gtw
 SG_ APP_sw273_lngDistanceToVehicle m273 : 33|8@1+ (0.02,0) [0|5.11] "meters"  gtw
 SG_ APP_sw053_a27CntryCdValidity m53 : 33|1@1+ (1,0) [0|1] ""  gtw
 SG_ APP_sw265_backupBlocked m265 : 33|1@1+ (1,0) [0|1] ""  gtw
 SG_ APP_sw207_lcUnavailableReason m207 : 32|8@1+ (1,0) [0|255] ""  gtw
 SG_ APP_sw034_unusedW0 m34 : 32|16@1+ (1,0) [0|65535] ""  gtw
 SG_ APP_sw266_backupStreamStatus m266 : 32|3@1+ (1,0) [0|7] ""  gtw
 SG_ APP_sw017_numSeqErrors m17 : 32|8@1+ (1,0) [0|255] ""  gtw
 SG_ APP_sw024_taskProgramCounter m24 : 32|32@1+ (1,0) [0|4294967295] ""  gtw
 SG_ APP_sw191_epasErrorCode m191 : 32|4@1+ (1,0) [0|15] ""  gtw
 SG_ APP_sw085_roadClass m85 : 32|3@1+ (1,0) [0|7] ""  gtw
 SG_ APP_sw029_highestSeqRcvd m29 : 32|16@1+ (1,0) [0|65535] ""  gtw
 SG_ APP_sw011_scaSonicDist m11 : 32|5@1+ (0.05,0) [0|1.5] "m"  gtw
 SG_ APP_sw070_temperature m70 : 32|8@1+ (0.5,-40) [-40|87.5] "C"  gtw
 SG_ APP_sw081_cameraDistance m81 : 32|8@1+ (0.0625,0) [0|15.9375] "m"  gtw
 SG_ APP_sw043_mesp_health_main_state m43 : 32|16@1+ (1,0) [0|65535] ""  gtw
 SG_ APP_sw260_target_ax m260 : 32|8@1+ (0.1,-15.5) [-15.5|10] "m/s2"  gtw
 SG_ APP_sw141_tempSensorId m141 : 32|8@1+ (1,0) [0|255] ""  gtw
 SG_ APP_sw058_unusedW0 m58 : 32|16@1+ (1,0) [0|65535] ""  gtw
 SG_ APP_sw053_a26brakeValidity m53 : 32|1@1+ (1,0) [0|1] ""  gtw
 SG_ APP_sw200_startSpeed m200 : 32|10@1+ (0.1,-10) [-10|92.3] "m/s"  gtw
 SG_ APP_sw083_Targ5_dx m83 : 32|12@1+ (0.0625,0) [0|255.9375] "m"  gtw
 SG_ APP_sw022_errorCode m22 : 32|32@1+ (1,0) [0|4294967295] ""  gtw
 SG_ APP_sw063_expectedMinorVer m63 : 32|8@1+ (1,0) [0|255] ""  gtw
 SG_ APP_sw015_AutofixOOfCalibHorizon m15 : 32|2@1+ (1,0) [0|3] ""  gtw
 SG_ APP_sw258_target_ax m258 : 32|8@1+ (0.1,-15.5) [-15.5|10] "m/s2"  gtw
 SG_ APP_sw065_unusedW0 m65 : 32|16@1+ (1,0) [0|65535] ""  gtw
 SG_ APP_sw032_errorData1 m32 : 32|16@1+ (1,0) [0|65535] ""  gtw
 SG_ APP_sw261_fatalUncorrErrors m261 : 32|8@1+ (1,0) [0|255] ""  gtw
 SG_ APP_sw204_frMiddle m204 : 32|8@1+ (1,0) [0|255] "cm"  gtw
 SG_ APP_sw195_sdiRearCC m195 : 32|5@1+ (1,0) [0|31] ""  gtw
 SG_ APP_sw037_unusedW0 m37 : 32|16@1+ (1,0) [0|65535] ""  gtw
 SG_ APP_sw006_SelfGlare m6 : 32|1@1+ (1,0) [0|1] ""  gtw
 SG_ APP_sw057_phoneLocStatusMia m57 : 32|1@1+ (1,0) [0|1] ""  gtw
 SG_ APP_sw012_bootDDRTempStatus m12 : 32|2@1+ (1,0) [0|3] ""  gtw
 SG_ APP_sw049_app_version_msw m49 : 32|16@1+ (1,0) [0|65535] ""  gtw
 SG_ APP_sw213_startSpeed m213 : 32|10@1+ (0.1,-10) [-10|92.3] "m/s"  gtw
 SG_ APP_sw140_backupCamSerFault m140 : 32|3@1+ (1,0) [0|4] ""  gtw
 SG_ APP_sw231_targetDistance m231 : 32|7@1+ (0.1,0) [0|12.7] "m"  gtw
 SG_ APP_sw103_objectDy m103 : 32|8@1+ (0.5,-15.5) [-15.5|16] "m"  gtw
 SG_ APP_sw028_highestSeqRcvd m28 : 32|16@1+ (1,0) [0|65535] ""  gtw
 SG_ APP_sw018_maxThreshold m18 : 32|15@1+ (1,50) [50|5500] "mV"  gtw
 SG_ APP_sw086_ellipseWidth m86 : 32|8@1+ (0.1,0) [0|25.5] "m"  gtw
 SG_ APP_sw054_Autofix_yaw m54 : 32|8@1+ (1,0) [0|255] ""  gtw
 SG_ APP_sw201_timeHorizon m201 : 32|8@1+ (0.1,0) [0|25.5] "s"  gtw
 SG_ APP_sw027_LVD_1v2 m27 : 32|1@1+ (1,0) [0|1] ""  gtw
 SG_ APP_sw075_unusedW0 m75 : 32|16@1+ (1,0) [0|65535] ""  gtw
 SG_ APP_sw205_rrLeftMiddle m205 : 32|8@1+ (1,0) [0|255] "cm"  gtw
 SG_ APP_sw143_targetDistance m143 : 32|7@1+ (0.1,0) [0|12.7] "m"  gtw
 SG_ APP_sw066_unusedW0 m66 : 32|16@1+ (1,0) [0|65535] ""  gtw
 SG_ APP_sw031_errorData1 m31 : 32|16@1+ (1,0) [0|65535] ""  gtw
 SG_ APP_sw218_pedalPosition m218 : 32|7@1+ (1,0) [0|127] "%"  gtw
 SG_ APP_sw036_unusedW0 m36 : 32|16@1+ (1,0) [0|65535] ""  gtw
 SG_ APP_sw259_ego_acceleration m259 : 32|8@1+ (0.1,-15.5) [-15.5|10] "m/s2"  gtw
 SG_ APP_sw062_VerticalMisalignment m62 : 32|10@1+ (0.087977,-45) [-45|45.000471] "deg"  gtw
 SG_ APP_sw019_timeStamp m19 : 32|32@1+ (1,0) [0|4294967295] "ms"  gtw
 SG_ APP_sw271_egoSpeed m271 : 32|8@1+ (0.2,0) [0|51] "m/s"  gtw
 SG_ APP_sw077_oocCollisionSide m77 : 32|3@1+ (1,0) [0|7] ""  gtw
 SG_ APP_sw078_radarTarg5_dx m78 : 32|8@1+ (0.0625,0) [0|15.9375] "m"  gtw
 SG_ APP_sw263_markerType m263 : 32|3@1+ (1,0) [0|7] ""  gtw
 SG_ APP_sw084_ipsoDx m84 : 32|8@1+ (0.1,0) [0|25.5] "meters"  gtw
 SG_ APP_sw020_unusedW1 m20 : 32|16@1+ (1,0) [0|65535] ""  gtw
 SG_ APP_sw030_unusedW0 m30 : 32|16@1+ (1,0) [0|65535] ""  gtw
 SG_ APP_sw021_maxThreshold m21 : 32|8@1- (1,0) [-128|127] "degC"  gtw
 SG_ APP_sw056_unusedW0 m56 : 32|16@1+ (1,0) [0|65535] ""  gtw
 SG_ APP_sw149_diskUsageMap m149 : 32|8@1+ (1,0) [0|255] "percent"  gtw
 SG_ APP_sw013_numSeqErrors m13 : 32|8@1+ (1,0) [0|255] ""  gtw
 SG_ APP_sw044_timestampms m44 : 32|32@1+ (1,0) [0|4294967295] "ms"  gtw
 SG_ APP_sw074_ipsoDz m74 : 32|6@1+ (0.2,-6.4) [-6.4|6.2] "m"  gtw
 SG_ APP_sw257_target_ax m257 : 32|8@1+ (0.1,-15.5) [-15.5|10] "m/s2"  gtw
 SG_ APP_sw080_stw_angle_deg m80 : 32|8@1+ (1,0) [0|255] "deg"  gtw
 SG_ APP_sw269_lRepeaterLanesFailsafe m269 : 32|1@1+ (1,0) [0|1] ""  gtw
 SG_ APP_sw046_errorCode m46 : 32|32@1+ (1,0) [0|4294967295] ""  gtw
 SG_ APP_sw073_freespaceRightC0 m73 : 32|8@1+ (0.1,-12.8) [-12.8|12.7] "m"  gtw
 SG_ APP_sw082_L_Lane m82 : 32|8@1+ (0.05,-6.4) [-6.4|6.35] "m"  gtw
 SG_ APP_sw001_APP_alertDataW1 m1 : 32|16@1+ (1,0) [0|65535] ""  gtw
 SG_ APP_sw202_sdiRearCC m202 : 32|5@1+ (1,0) [0|31] ""  gtw
 SG_ APP_sw047_edrReturn m47 : 32|16@1+ (1,0) [0|65535] ""  gtw
 SG_ APP_sw042_state_before_abort m42 : 32|4@1+ (1,0) [0|15] ""  gtw
 SG_ APP_sw005_speed m5 : 32|1@1+ (1,0) [0|1] ""  gtw
 SG_ APP_sw025_hppUsage m25 : 32|2@1+ (1,0) [0|3] ""  gtw
 SG_ APP_sw014_lineNumberInCode m14 : 32|16@1+ (1,0) [0|65535] ""  gtw
 SG_ APP_sw051_HWFail m51 : 32|1@1+ (1,0) [0|1] ""  gtw
 SG_ APP_sw039_unusedW0 m39 : 32|16@1+ (1,0) [0|65535] ""  gtw
 SG_ APP_sw171_APP_pascalTemp m171 : 32|8@1+ (1,-128) [-128|127] "C"  gtw
 SG_ APP_sw265_rightRepeaterBlocked m265 : 32|1@1+ (1,0) [0|1] ""  gtw
 SG_ APP_sw040_das_steering_req m40 : 32|8@1+ (1,-128) [-128|127] "deg"  gtw
 SG_ APP_sw005_steeringAngleRate m5 : 31|1@1+ (1,0) [0|1] ""  gtw
 SG_ APP_sw146_telemSize m146 : 31|9@1+ (100,0) [0|51100] "kB"  gtw
 SG_ APP_sw269_rPillarLanesFailsafe m269 : 31|1@1+ (1,0) [0|1] ""  gtw
 SG_ APP_sw053_a25ambTValidity m53 : 31|1@1+ (1,0) [0|1] ""  gtw
 SG_ APP_sw057_vehicleControl2 m57 : 31|1@1+ (1,0) [0|1] ""  gtw
 SG_ APP_sw018_powerSequnceError m18 : 31|1@1+ (1,0) [0|1] ""  gtw
 SG_ APP_sw006_FoggyLights m6 : 31|1@1+ (1,0) [0|1] ""  gtw
 SG_ APP_sw213_epasHandsOnDetected m213 : 31|1@1+ (1,0) [0|1] ""  gtw
 SG_ APP_sw265_leftRepeaterBlocked m265 : 31|1@1+ (1,0) [0|1] ""  gtw
 SG_ APP_sw200_epasHandsOnDetected m200 : 31|1@1+ (1,0) [0|1] ""  gtw
 SG_ APP_sw053_a24absValidity m53 : 30|1@1+ (1,0) [0|1] ""  gtw
 SG_ APP_sw067_epasSTW m67 : 30|14@1+ (0.1,-819.2) [-819.2|819] "deg"  gtw
 SG_ APP_sw006_SmearedHalos m6 : 30|1@1+ (1,0) [0|1] ""  gtw
 SG_ APP_sw269_lPillarLanesFailsafe m269 : 30|1@1+ (1,0) [0|1] ""  gtw
 SG_ APP_sw005_steeringAngle m5 : 30|1@1+ (1,0) [0|1] ""  gtw
 SG_ APP_sw015_AutofixOutOfCalibYaw m15 : 30|2@1+ (1,0) [0|3] ""  gtw
 SG_ APP_sw071_endPosY m71 : 30|10@1+ (0.05,-25.6) [-25.6|25.5] "m"  gtw
 SG_ APP_sw069_torsionBar m69 : 30|12@1+ (0.01,-20.5) [-20.5|20.45] "Nm"  gtw
 SG_ APP_sw227_sensorMeasurement m227 : 30|9@1+ (1,0) [0|511] "cm"  gtw
 SG_ APP_sw265_rightPillarBlocked m265 : 30|1@1+ (1,0) [0|1] ""  gtw
 SG_ APP_sw194_leadVx m194 : 30|6@1- (0.2,0.0) [-6|6] "m/s"  gtw
 SG_ APP_sw057_vehicleControl m57 : 30|1@1+ (1,0) [0|1] ""  gtw
 SG_ APP_sw047_edrBlackBox m47 : 30|2@1+ (1,0) [0|3] ""  gtw
 SG_ APP_sw265_leftPillarBlocked m265 : 29|1@1+ (1,0) [0|1] ""  gtw
 SG_ APP_sw218_mcuAutosteerRestricted m218 : 29|1@1+ (1,0) [0|1] ""  gtw
 SG_ APP_sw006_FullBlockage m6 : 29|1@1+ (1,0) [0|1] ""  gtw
 SG_ APP_sw053_a23sccmInvalidChkSm m53 : 29|1@1+ (1,0) [0|1] ""  gtw
 SG_ APP_sw140_backupCamDeserLock m140 : 29|2@1+ (1,0) [0|2] ""  gtw
 SG_ APP_sw005_brakePedal m5 : 29|1@1+ (1,0) [0|1] ""  gtw
 SG_ APP_sw057_cruiseControl m57 : 29|1@1+ (1,0) [0|1] ""  gtw
 SG_ APP_sw269_rRepeaterBlocked m269 : 29|1@1+ (1,0) [0|1] ""  gtw
 SG_ APP_sw018_railID m18 : 29|2@1+ (1,0) [0|3] ""  gtw
 SG_ APP_sw069_parkCal m69 : 29|1@1+ (1,0) [0|1] ""  gtw
 SG_ APP_sw025_vehiclesUsage m25 : 29|2@1+ (1,0) [0|3] ""  gtw
 SG_ APP_sw263_dtleAboveThresholdLdw m263 : 29|1@1+ (1,0) [0|1] ""  gtw
 SG_ APP_sw279_serializerCrcErrCount m279 : 28|8@1+ (1,0) [0|255] ""  gtw
 SG_ APP_sw044_meMainState m44 : 28|4@1+ (1,0) [0|15] ""  gtw
 SG_ APP_sw276_serializerCrcErrCount m276 : 28|8@1+ (1,0) [0|255] ""  gtw
 SG_ APP_sw182_serializerCrcErrCount m182 : 28|8@1+ (1,0) [0|255] ""  gtw
 SG_ APP_sw281_serializerCrcErrCount m281 : 28|8@1+ (1,0) [0|255] ""  gtw
 SG_ APP_sw187_serializerCrcErrCount m187 : 28|8@1+ (1,0) [0|255] ""  gtw
 SG_ APP_sw053_a22sccmInvalidChkSm m53 : 28|1@1+ (1,0) [0|1] ""  gtw
 SG_ APP_sw145_camExtPitchCal m145 : 28|9@1+ (0.05,-12.5) [-12.5|12.5] "deg"  gtw
 SG_ APP_sw278_serializerCrcErrCount m278 : 28|8@1+ (1,0) [0|255] ""  gtw
 SG_ APP_sw004_appMobileyeStatus m4 : 28|5@1+ (1,0) [0|31] ""  gtw
 SG_ APP_sw263_notEncroaching m263 : 28|1@1+ (1,0) [0|1] ""  gtw
 SG_ APP_sw070_accRail m70 : 28|1@1+ (1,0) [0|1] ""  gtw
 SG_ APP_sw275_serializerCrcErrCount m275 : 28|8@1+ (1,0) [0|255] ""  gtw
 SG_ APP_sw282_serializerCrcErrCount m282 : 28|8@1+ (1,0) [0|255] ""  gtw
 SG_ APP_sw186_serializerCrcErrCount m186 : 28|8@1+ (1,0) [0|255] ""  gtw
 SG_ APP_sw269_lRepeaterBlocked m269 : 28|1@1+ (1,0) [0|1] ""  gtw
 SG_ APP_sw140_backupCamSXDeserFailed m140 : 28|1@1+ (1,0) [0|1] ""  gtw
 SG_ APP_sw274_serializerCrcErrCount m274 : 28|8@1+ (1,0) [0|255] ""  gtw
 SG_ APP_sw185_serializerCrcErrCount m185 : 28|8@1+ (1,0) [0|255] ""  gtw
 SG_ APP_sw006_AutofixOutOfCalibYaw m6 : 28|1@1+ (1,0) [0|1] ""  gtw
 SG_ APP_sw015_AutofixOutOfCalib m15 : 28|2@1+ (1,0) [0|3] ""  gtw
 SG_ APP_sw184_serializerCrcErrCount m184 : 28|8@1+ (1,0) [0|255] ""  gtw
 SG_ APP_sw191_cruiseState m191 : 28|3@1+ (1,0) [0|7] ""  gtw
 SG_ APP_sw005_radCalibration m5 : 28|1@1+ (1,0) [0|1] ""  gtw
 SG_ APP_sw027_Unused_Nibble m27 : 28|4@1+ (1,0) [0|15] ""  gtw
 SG_ APP_sw190_serializerCrcErrCount m190 : 28|8@1+ (1,0) [0|255] ""  gtw
 SG_ APP_sw189_serializerCrcErrCount m189 : 28|8@1+ (1,0) [0|255] ""  gtw
 SG_ APP_sw183_serializerCrcErrCount m183 : 28|8@1+ (1,0) [0|255] ""  gtw
 SG_ APP_sw277_serializerCrcErrCount m277 : 28|8@1+ (1,0) [0|255] ""  gtw
 SG_ APP_sw280_serializerCrcErrCount m280 : 28|8@1+ (1,0) [0|255] ""  gtw
 SG_ APP_sw057_vehicleModes m57 : 28|1@1+ (1,0) [0|1] ""  gtw
 SG_ APP_sw048_parkerIssue m48 : 28|1@1+ (1,0) [0|1] ""  gtw
 SG_ APP_sw188_serializerCrcErrCount m188 : 28|8@1+ (1,0) [0|255] ""  gtw
 SG_ APP_sw230_sensor12Blocked m230 : 27|1@1+ (1,0) [0|1] ""  gtw
 SG_ APP_sw263_blinkerActive m263 : 27|1@1+ (1,0) [0|1] ""  gtw
 SG_ APP_sw053_a21espInvalidChkSm m53 : 27|1@1+ (1,0) [0|1] ""  gtw
 SG_ APP_sw269_rPillarBlocked m269 : 27|1@1+ (1,0) [0|1] ""  gtw
 SG_ APP_sw140_backupCamUARTbusFault m140 : 27|1@1+ (1,0) [0|1] ""  gtw
 SG_ APP_sw005_radMia m5 : 27|1@1+ (1,0) [0|1] ""  gtw
 SG_ APP_sw048_camIssue m48 : 27|1@1+ (1,0) [0|1] ""  gtw
 SG_ APP_sw270_rRepeaterLanesFailsafe m270 : 27|1@1+ (1,0) [0|1] ""  gtw
 SG_ APP_sw057_solarData m57 : 27|1@1+ (1,0) [0|1] ""  gtw
 SG_ APP_sw026_execution_time m26 : 27|9@1+ (0.125,0) [0|65.411] "ms"  gtw
 SG_ APP_sw025_rightLaneUsage m25 : 27|2@1+ (1,0) [0|3] ""  gtw
 SG_ APP_sw006_AutofixOutOfCalibHorzn m6 : 27|1@1+ (1,0) [0|1] ""  gtw
 SG_ APP_sw070_driveRail m70 : 27|1@1+ (1,0) [0|1] ""  gtw
 SG_ APP_sw266_rRepeaterStreamStatus m266 : 27|3@1+ (1,0) [0|7] ""  gtw
 SG_ APP_sw059_status m59 : 27|1@1+ (1,0) [0|1] ""  gtw
 SG_ APP_sw027_f_PLL_1_Off m27 : 27|1@1+ (1,0) [0|1] ""  gtw
 SG_ APP_sw041_max_rate m41 : 26|10@1- (1,0) [-512|511] "deg/s"  gtw
 SG_ APP_sw274_imagerHeartbeat m274 : 26|2@1+ (1,0) [0|3] ""  gtw
 SG_ APP_sw269_lPillarBlocked m269 : 26|1@1+ (1,0) [0|1] ""  gtw
 SG_ APP_sw057_odo m57 : 26|1@1+ (1,0) [0|1] ""  gtw
 SG_ APP_sw275_imagerHeartbeat m275 : 26|2@1+ (1,0) [0|3] ""  gtw
 SG_ APP_sw282_imagerHeartbeat m282 : 26|2@1+ (1,0) [0|3] ""  gtw
 SG_ APP_sw278_imagerHeartbeat m278 : 26|2@1+ (1,0) [0|3] ""  gtw
 SG_ APP_sw230_sensor11Blocked m230 : 26|1@1+ (1,0) [0|1] ""  gtw
 SG_ APP_sw048_eyeQVersionMismatch m48 : 26|1@1+ (1,0) [0|1] ""  gtw
 SG_ APP_sw186_imagerHeartbeat m186 : 26|2@1+ (1,0) [0|3] ""  gtw
 SG_ APP_sw263_noCollisionImminent m263 : 26|1@1+ (1,0) [0|1] ""  gtw
 SG_ APP_sw279_imagerHeartbeat m279 : 26|2@1+ (1,0) [0|3] ""  gtw
 SG_ APP_sw068_virtualLaneSTW m68 : 26|14@1+ (0.1,-819.2) [-819.2|819.2] "deg"  gtw
 SG_ APP_sw017_numCrcErrors m17 : 26|6@1+ (1,0) [0|63] ""  gtw
 SG_ APP_sw072_vehicleY m72 : 26|10@1+ (0.05,-25.6) [-25.6|25.5] "m"  gtw
 SG_ APP_sw006_AutofixOutOfCalib m6 : 26|1@1+ (1,0) [0|1] ""  gtw
 SG_ APP_sw188_imagerHeartbeat m188 : 26|2@1+ (1,0) [0|3] ""  gtw
 SG_ APP_sw005_radSGUFailure m5 : 26|1@1+ (1,0) [0|1] ""  gtw
 SG_ APP_sw187_imagerHeartbeat m187 : 26|2@1+ (1,0) [0|3] ""  gtw
 SG_ APP_sw281_imagerHeartbeat m281 : 26|2@1+ (1,0) [0|3] ""  gtw
 SG_ APP_sw276_imagerHeartbeat m276 : 26|2@1+ (1,0) [0|3] ""  gtw
 SG_ APP_sw182_imagerHeartbeat m182 : 26|2@1+ (1,0) [0|3] ""  gtw
 SG_ APP_sw190_imagerHeartbeat m190 : 26|2@1+ (1,0) [0|3] ""  gtw
 SG_ APP_sw189_imagerHeartbeat m189 : 26|2@1+ (1,0) [0|3] ""  gtw
 SG_ APP_sw015_PartialBlockage m15 : 26|2@1+ (1,0) [0|3] ""  gtw
 SG_ APP_sw053_a20bdyInvalidChkSm m53 : 26|1@1+ (1,0) [0|1] ""  gtw
 SG_ APP_sw184_imagerHeartbeat m184 : 26|2@1+ (1,0) [0|3] ""  gtw
 SG_ APP_sw199_currentSTW m199 : 26|14@1+ (0.1,-819.2) [-819.2|819] "deg"  gtw
 SG_ APP_sw277_imagerHeartbeat m277 : 26|2@1+ (1,0) [0|3] ""  gtw
 SG_ APP_sw183_imagerHeartbeat m183 : 26|2@1+ (1,0) [0|3] ""  gtw
 SG_ APP_sw027_Unused_Bit_1 m27 : 26|1@1+ (1,0) [0|1] ""  gtw
 SG_ APP_sw280_imagerHeartbeat m280 : 26|2@1+ (1,0) [0|3] ""  gtw
 SG_ APP_sw270_lRepeaterLanesFailsafe m270 : 26|1@1+ (1,0) [0|1] ""  gtw
 SG_ APP_sw059_status2 m59 : 26|1@1+ (1,0) [0|1] ""  gtw
 SG_ APP_sw185_imagerHeartbeat m185 : 26|2@1+ (1,0) [0|3] ""  gtw
 SG_ APP_sw076_targetRelSpeed m76 : 25|9@1+ (0.0625,-31) [-31|0.9375] "m/s"  gtw
 SG_ APP_sw185_deserCrcError m185 : 25|1@1+ (1,0) [0|1] ""  gtw
 SG_ APP_sw270_rPillarLanesFailsafe m270 : 25|1@1+ (1,0) [0|1] ""  gtw
 SG_ APP_sw274_deserCrcError m274 : 25|1@1+ (1,0) [0|1] ""  gtw
 SG_ APP_sw273_timeToCollision m273 : 25|8@1+ (0.02,0) [0|5.11] "seconds"  gtw
 SG_ APP_sw057_chassisControl m57 : 25|1@1+ (1,0) [0|1] ""  gtw
 SG_ APP_sw178_lPillarCamExtRollCal m178 : 25|9@1- (0.05,0.0) [-12.5|12.5] "deg"  gtw
 SG_ APP_sw048_radcMia m48 : 25|1@1+ (1,0) [0|1] ""  gtw
 SG_ APP_sw203_slotSizeX m203 : 25|8@1+ (4,0) [0|1020] "cm"  gtw
 SG_ APP_sw143_predImpactVelocity m143 : 25|7@1+ (0.5,0) [0|63.5] "m/s"  gtw
 SG_ APP_sw186_deserCrcError m186 : 25|1@1+ (1,0) [0|1] ""  gtw
 SG_ APP_sw282_deserCrcError m282 : 25|1@1+ (1,0) [0|1] ""  gtw
 SG_ APP_sw275_deserCrcError m275 : 25|1@1+ (1,0) [0|1] ""  gtw
 SG_ APP_sw179_rPillarCamExtRollCal m179 : 25|9@1- (0.05,0.0) [-12.5|12.5] "deg"  gtw
 SG_ APP_sw016_targetRelSpeed m16 : 25|9@1+ (0.0625,-31) [-31|0.9375] "m/s"  gtw
 SG_ APP_sw278_deserCrcError m278 : 25|1@1+ (1,0) [0|1] ""  gtw
 SG_ APP_sw177_fisheyeCamExtRollCal m177 : 25|9@1- (0.05,0.0) [-12.5|12.5] "deg"  gtw
 SG_ APP_sw005_radSensorBlind m5 : 25|1@1+ (1,0) [0|1] ""  gtw
 SG_ APP_sw187_deserCrcError m187 : 25|1@1+ (1,0) [0|1] ""  gtw
 SG_ APP_sw281_deserCrcError m281 : 25|1@1+ (1,0) [0|1] ""  gtw
 SG_ APP_sw069_diAPState m69 : 25|4@1+ (1,0) [0|9] ""  gtw
 SG_ APP_sw027_PLL_1_Failure m27 : 25|1@1+ (1,0) [0|1] ""  gtw
 SG_ APP_sw276_deserCrcError m276 : 25|1@1+ (1,0) [0|1] ""  gtw
 SG_ APP_sw182_deserCrcError m182 : 25|1@1+ (1,0) [0|1] ""  gtw
 SG_ APP_sw142_pitchOffsetAtmptVal m142 : 25|9@1+ (1,-256) [-256|255] "pixels"  gtw
 SG_ APP_sw053_a19sccmInvalidCount m53 : 25|1@1+ (1,0) [0|1] ""  gtw
 SG_ APP_sw060_targetRelSpeed m60 : 25|9@1+ (0.0625,-31) [-31|0.9375] "m/s"  gtw
 SG_ APP_sw279_deserCrcError m279 : 25|1@1+ (1,0) [0|1] ""  gtw
 SG_ APP_sw188_deserCrcError m188 : 25|1@1+ (1,0) [0|1] ""  gtw
 SG_ APP_sw230_sensor10Blocked m230 : 25|1@1+ (1,0) [0|1] ""  gtw
 SG_ APP_sw231_predImpactVelocity m231 : 25|7@1+ (0.5,0) [0|63.5] "m/s"  gtw
 SG_ APP_sw218_handsOnState m218 : 25|4@1+ (1,0) [0|15] ""  gtw
 SG_ APP_sw131_mainCamExtRollCal m131 : 25|9@1- (0.05,0.0) [-12.5|12.5] "deg"  gtw
 SG_ APP_sw183_deserCrcError m183 : 25|1@1+ (1,0) [0|1] ""  gtw
 SG_ APP_sw277_deserCrcError m277 : 25|1@1+ (1,0) [0|1] ""  gtw
 SG_ APP_sw280_deserCrcError m280 : 25|1@1+ (1,0) [0|1] ""  gtw
 SG_ APP_sw269_fisheyeBlocked m269 : 25|1@1+ (1,0) [0|1] ""  gtw
 SG_ APP_sw181_rRepeatCamExtRollCal m181 : 25|9@1- (0.05,0.0) [-12.5|12.5] "deg"  gtw
 SG_ APP_sw263_multiLane m263 : 25|1@1+ (1,0) [0|1] ""  gtw
 SG_ APP_sw017_Any_TFL_Msg_Recd m17 : 25|1@1+ (1,0) [0|1] ""  gtw
 SG_ APP_sw050_targetRelSpeed m50 : 25|9@1+ (0.0625,-31) [-31|0.9375] "m/s"  gtw
 SG_ APP_sw190_deserCrcError m190 : 25|1@1+ (1,0) [0|1] ""  gtw
 SG_ APP_sw006_PartialBlockage m6 : 25|1@1+ (1,0) [0|1] ""  gtw
 SG_ APP_sw189_deserCrcError m189 : 25|1@1+ (1,0) [0|1] ""  gtw
 SG_ APP_sw077_oocConfidence m77 : 25|7@1+ (1,0) [0|100] "%"  gtw
 SG_ APP_sw180_lRepeatCamExtRollCal m180 : 25|9@1- (0.05,0.0) [-12.5|12.5] "deg"  gtw
 SG_ APP_sw025_leftLaneUsage m25 : 25|2@1+ (1,0) [0|3] ""  gtw
 SG_ APP_sw059_sensorStatusRear m59 : 25|1@1+ (1,0) [0|1] ""  gtw
 SG_ APP_sw184_deserCrcError m184 : 25|1@1+ (1,0) [0|1] ""  gtw
 SG_ APP_sw132_narrowCamExtRollCal m132 : 25|9@1- (0.05,0.0) [-12.5|12.5] "deg"  gtw
 SG_ APP_sw277_deserLockError m277 : 24|1@1+ (1,0) [0|1] ""  gtw
 SG_ APP_sw183_deserLockError m183 : 24|1@1+ (1,0) [0|1] ""  gtw
 SG_ APP_sw078_ttc m78 : 24|8@1+ (0.02,0) [0|5.11] "seconds"  gtw
 SG_ APP_sw137_rPillarCamSerFault m137 : 24|3@1+ (1,0) [0|4] ""  gtw
 SG_ APP_sw260_target_vx m260 : 24|8@1+ (0.2,-51) [-51|0] "m/s"  gtw
 SG_ APP_sw201_stwAngleReq m201 : 24|8@1- (1,0) [-128|127] "deg"  gtw
 SG_ APP_sw204_frLeftMiddle m204 : 24|8@1+ (1,0) [0|255] "cm"  gtw
 SG_ APP_sw039_unusedByte m39 : 24|8@1+ (1,0) [0|255] ""  gtw
 SG_ APP_sw280_deserLockError m280 : 24|1@1+ (1,0) [0|1] ""  gtw
 SG_ APP_sw058_unusedByte m58 : 24|8@1+ (1,0) [0|255] ""  gtw
 SG_ APP_sw147_selfieCamSerFault m147 : 24|3@1+ (1,0) [0|4] ""  gtw
 SG_ APP_sw259_ego_speed m259 : 24|8@1+ (0.2,0) [0|51] "m/s"  gtw
 SG_ APP_sw065_mobileye_main_state m65 : 24|8@1+ (1,0) [0|255] ""  gtw
 SG_ APP_sw184_deserLockError m184 : 24|1@1+ (1,0) [0|1] ""  gtw
 SG_ APP_sw149_diskUsageHome m149 : 24|8@1+ (1,0) [0|255] "percent"  gtw
 SG_ APP_sw084_ipsoRCS m84 : 24|8@1+ (1,0) [0|255] ""  gtw
 SG_ APP_sw025_controlled_access m25 : 24|1@1+ (1,0) [0|1] ""  gtw
 SG_ APP_sw190_deserLockError m190 : 24|1@1+ (1,0) [0|1] ""  gtw
 SG_ APP_sw024_currentVehicleApp m24 : 24|8@1+ (1,0) [0|161] ""  gtw
 SG_ APP_sw189_deserLockError m189 : 24|1@1+ (1,0) [0|1] ""  gtw
 SG_ APP_sw266_lRepeaterStreamStatus m266 : 24|3@1+ (1,0) [0|7] ""  gtw
 SG_ APP_sw081_radarTTC m81 : 24|8@1+ (0.02,0) [0|5.11] "seconds"  gtw
 SG_ APP_sw011_scaSpeed m11 : 24|7@1+ (1,0) [0|127] "MPH"  gtw
 SG_ APP_sw021_minThreshold m21 : 24|8@1- (1,0) [-128|127] "degC"  gtw
 SG_ APP_sw030_unusedByte m30 : 24|8@1+ (1,0) [0|255] ""  gtw
 SG_ APP_sw051_SCUTemperature m51 : 24|8@1- (1,0) [-128|127] ""  gtw
 SG_ APP_sw103_objectRCS m103 : 24|8@1+ (1,0) [0|255] ""  gtw
 SG_ APP_sw270_lPillarLanesFailsafe m270 : 24|1@1+ (1,0) [0|1] ""  gtw
 SG_ APP_sw037_issue m37 : 24|8@1+ (1,0) [0|255] ""  gtw
 SG_ APP_sw082_R_VL m82 : 24|8@1+ (0.05,-6.4) [-6.4|6.35] "m"  gtw
 SG_ APP_sw015_FullBlockage m15 : 24|2@1+ (1,0) [0|3] ""  gtw
 SG_ APP_sw056_unusedByte m56 : 24|8@1+ (1,0) [0|255] ""  gtw
 SG_ APP_sw257_target_vx m257 : 24|8@1+ (0.2,-51) [-51|0] "m/s"  gtw
 SG_ APP_sw047_edrType m47 : 24|6@1+ (1,0) [0|63] ""  gtw
 SG_ APP_sw066_mobileye_main_state m66 : 24|8@1+ (1,0) [0|255] ""  gtw
 SG_ APP_sw138_lRepeatCamSerFault m138 : 24|3@1+ (1,0) [0|4] ""  gtw
 SG_ APP_sw191_handsOnState m191 : 24|4@1+ (1,0) [0|15] ""  gtw
 SG_ APP_sw139_rRepeatCamSerFault m139 : 24|3@1+ (1,0) [0|4] ""  gtw
 SG_ APP_sw273_handsOn m273 : 24|1@1+ (1,0) [0|1] ""  gtw
 SG_ APP_sw059_sensorStatusFront m59 : 24|1@1+ (1,0) [0|1] ""  gtw
 SG_ APP_sw202_sdiFrontCC m202 : 24|5@1+ (1,0) [0|31] ""  gtw
 SG_ APP_sw274_deserLockError m274 : 24|1@1+ (1,0) [0|1] ""  gtw
 SG_ APP_sw195_sdiFrontCC m195 : 24|5@1+ (1,0) [0|31] ""  gtw
 SG_ APP_sw269_narrowBlocked m269 : 24|1@1+ (1,0) [0|1] ""  gtw
 SG_ APP_sw031_errorType m31 : 24|8@1+ (1,0) [0|8] ""  gtw
 SG_ APP_sw218_drivingOnHighway m218 : 24|1@1+ (1,0) [0|1] ""  gtw
 SG_ APP_sw207_eyeq3MainState m207 : 24|8@1+ (1,0) [0|255] ""  gtw
 SG_ APP_sw185_deserLockError m185 : 24|1@1+ (1,0) [0|1] ""  gtw
 SG_ APP_sw063_detectedMajorVer m63 : 24|8@1+ (1,0) [0|255] ""  gtw
 SG_ APP_sw186_deserLockError m186 : 24|1@1+ (1,0) [0|1] ""  gtw
 SG_ APP_sw271_progress m271 : 24|8@1+ (0.0039215,0) [0|1] "%"  gtw
 SG_ APP_sw205_rrLeft m205 : 24|8@1+ (1,0) [0|255] "cm"  gtw
 SG_ APP_sw006_SmearedSpots m6 : 24|1@1+ (1,0) [0|1] ""  gtw
 SG_ APP_sw075_unusedByte m75 : 24|8@1+ (1,0) [0|255] ""  gtw
 SG_ APP_sw263_ldwConditionsMet m263 : 24|1@1+ (1,0) [0|1] ""  gtw
 SG_ APP_sw073_freespaceLeftC0 m73 : 24|8@1+ (0.1,-12.8) [-12.8|12.7] "m"  gtw
 SG_ APP_sw136_lPillarCamSerFault m136 : 24|3@1+ (1,0) [0|4] ""  gtw
 SG_ APP_sw019_numFreeBytes m19 : 24|8@1+ (1,-191) [-191|64] "# of bytes"  gtw
 SG_ APP_sw042_view_range m42 : 24|8@1+ (1,0) [0|255] ""  gtw
 SG_ APP_sw036_unusedByte m36 : 24|8@1+ (1,0) [0|255] ""  gtw
 SG_ APP_sw074_ipsoDy m74 : 24|6@1+ (0.1,-3.2) [-3.2|3.1] "m"  gtw
 SG_ APP_sw070_diGear m70 : 24|3@1+ (1,0) [0|7] ""  gtw
 SG_ APP_sw278_deserLockError m278 : 24|1@1+ (1,0) [0|1] ""  gtw
 SG_ APP_sw135_fisheyeCamSerFault m135 : 24|3@1+ (1,0) [0|4] ""  gtw
 SG_ APP_sw027_Flash_Fatal_Error m27 : 24|1@1+ (1,0) [0|1] ""  gtw
 SG_ APP_sw133_mainCamSerFault m133 : 24|3@1+ (1,0) [0|4] ""  gtw
 SG_ APP_sw230_sensor9Blocked m230 : 24|1@1+ (1,0) [0|1] ""  gtw
 SG_ APP_sw282_deserLockError m282 : 24|1@1+ (1,0) [0|1] ""  gtw
 SG_ APP_sw275_deserLockError m275 : 24|1@1+ (1,0) [0|1] ""  gtw
 SG_ APP_sw276_deserLockError m276 : 24|1@1+ (1,0) [0|1] ""  gtw
 SG_ APP_sw005_radHWFailure m5 : 24|1@1+ (1,0) [0|1] ""  gtw
 SG_ APP_sw040_ego_veh_speed m40 : 24|8@1+ (0.2,0) [0|51] "m/s"  gtw
 SG_ APP_sw145_problemCamPosition m145 : 24|4@1+ (1,0) [0|15] ""  gtw
 SG_ APP_sw281_deserLockError m281 : 24|1@1+ (1,0) [0|1] ""  gtw
 SG_ APP_sw044_appStatus m44 : 24|4@1+ (1,0) [0|15] ""  gtw
 SG_ APP_sw013_numCrcErrors m13 : 24|8@1+ (1,0) [0|255] ""  gtw
 SG_ APP_sw182_deserLockError m182 : 24|1@1+ (1,0) [0|1] ""  gtw
 SG_ APP_sw134_narrowCamSerFault m134 : 24|3@1+ (1,0) [0|4] ""  gtw
 SG_ APP_sw261_nonFatalUncorrErrors m261 : 24|8@1+ (1,0) [0|255] ""  gtw
 SG_ APP_sw187_deserLockError m187 : 24|1@1+ (1,0) [0|1] ""  gtw
 SG_ APP_sw080_rad_tar_5_dist m80 : 24|6@1+ (1,0) [0|63] "m"  gtw
 SG_ APP_sw140_backupCamSensorFault m140 : 24|3@1+ (1,0) [0|4] ""  gtw
 SG_ APP_sw171_APP_parkerBTemp m171 : 24|8@1+ (1,-128) [-128|127] "C"  gtw
 SG_ APP_sw017_Any_Objects_Msg_Recd m17 : 24|1@1+ (1,0) [0|1] ""  gtw
 SG_ APP_sw188_deserLockError m188 : 24|1@1+ (1,0) [0|1] ""  gtw
 SG_ APP_sw086_distanceEllipse m86 : 24|8@1+ (0.5,0) [0|127.5] "m"  gtw
 SG_ APP_sw265_unavailableReason m265 : 24|5@1+ (1,0) [0|16] ""  gtw
 SG_ APP_sw258_target_vx m258 : 24|8@1+ (0.2,-51) [-51|0] "m/s"  gtw
 SG_ APP_sw053_a18espInvalidCount m53 : 24|1@1+ (1,0) [0|1] ""  gtw
 SG_ APP_sw085_radarTTC m85 : 24|8@1+ (0.02,0) [0|5.11] "seconds"  gtw
 SG_ APP_sw048_radcCalibration m48 : 24|1@1+ (1,0) [0|1] ""  gtw
 SG_ APP_sw004_accState m4 : 24|4@1+ (1,0) [0|15] ""  gtw
 SG_ APP_sw279_deserLockError m279 : 24|1@1+ (1,0) [0|1] ""  gtw
 SG_ APP_sw057_telemetryControl m57 : 24|1@1+ (1,0) [0|1] ""  gtw
 SG_ APP_sw054_Autofix_horizon m54 : 24|8@1+ (1,0) [0|255] ""  gtw
 SG_ APP_sw141_minThreshold m141 : 24|8@1- (1,0) [-128|127] "degC"  gtw
 SG_ APP_sw034_unusedByte m34 : 24|8@1+ (1,0) [0|255] ""  gtw
 SG_ APP_sw032_errorType m32 : 24|8@1+ (1,0) [0|255] ""  gtw
 SG_ APP_sw053_a17adasInvalidCount m53 : 23|1@1+ (1,0) [0|1] ""  gtw
 SG_ APP_sw187_deserParityError m187 : 23|1@1+ (1,0) [0|1] ""  gtw
 SG_ APP_sw274_deserParityError m274 : 23|1@1+ (1,0) [0|1] ""  gtw
 SG_ APP_sw027_LVD_4v5 m27 : 23|1@1+ (1,0) [0|1] ""  gtw
 SG_ APP_sw011_scaThreshold m11 : 23|1@1+ (1,0) [0|1] ""  gtw
 SG_ APP_sw048_radcVersionMismatch m48 : 23|1@1+ (1,0) [0|1] ""  gtw
 SG_ APP_sw279_deserParityError m279 : 23|1@1+ (1,0) [0|1] ""  gtw
 SG_ APP_sw080_pedestrian_check m80 : 23|1@1+ (1,0) [0|1] ""  gtw
 SG_ APP_sw047_controlledAccess m47 : 23|1@1+ (1,0) [0|1] ""  gtw
 SG_ APP_sw263_lkaConditionsMet m263 : 23|1@1+ (1,0) [0|1] ""  gtw
 SG_ APP_sw184_deserParityError m184 : 23|1@1+ (1,0) [0|1] ""  gtw
 SG_ APP_sw230_sensor8Blocked m230 : 23|1@1+ (1,0) [0|1] ""  gtw
 SG_ APP_sw275_deserParityError m275 : 23|1@1+ (1,0) [0|1] ""  gtw
 SG_ APP_sw006_LowSun m6 : 23|1@1+ (1,0) [0|1] ""  gtw
 SG_ APP_sw282_deserParityError m282 : 23|1@1+ (1,0) [0|1] ""  gtw
 SG_ APP_sw057_csaRoadCurv m57 : 23|1@1+ (1,0) [0|1] ""  gtw
 SG_ APP_sw182_deserParityError m182 : 23|1@1+ (1,0) [0|1] ""  gtw
 SG_ APP_sw276_deserParityError m276 : 23|1@1+ (1,0) [0|1] ""  gtw
 SG_ APP_sw281_deserParityError m281 : 23|1@1+ (1,0) [0|1] ""  gtw
 SG_ APP_sw259_max_dv_reached m259 : 23|1@1+ (1,0) [0|1] ""  gtw
 SG_ APP_sw017_Any_Lanes_Msg_Recd m17 : 23|1@1+ (1,0) [0|1] ""  gtw
 SG_ APP_sw188_deserParityError m188 : 23|1@1+ (1,0) [0|1] ""  gtw
 SG_ APP_sw025_road_match m25 : 23|1@1+ (1,0) [0|1] ""  gtw
 SG_ APP_sw185_deserParityError m185 : 23|1@1+ (1,0) [0|1] ""  gtw
 SG_ APP_sw059_sdiRear m59 : 23|1@1+ (1,0) [0|1] ""  gtw
 SG_ APP_sw269_mainBlocked m269 : 23|1@1+ (1,0) [0|1] ""  gtw
 SG_ APP_sw005_camFcwPcwMsg m5 : 23|1@1+ (1,0) [0|1] ""  gtw
 SG_ APP_sw186_deserParityError m186 : 23|1@1+ (1,0) [0|1] ""  gtw
 SG_ APP_sw280_deserParityError m280 : 23|1@1+ (1,0) [0|1] ""  gtw
 SG_ APP_sw277_deserParityError m277 : 23|1@1+ (1,0) [0|1] ""  gtw
 SG_ APP_sw183_deserParityError m183 : 23|1@1+ (1,0) [0|1] ""  gtw
 SG_ APP_sw278_deserParityError m278 : 23|1@1+ (1,0) [0|1] ""  gtw
 SG_ APP_sw270_rRepeaterBlocked m270 : 23|1@1+ (1,0) [0|1] ""  gtw
 SG_ APP_sw189_deserParityError m189 : 23|1@1+ (1,0) [0|1] ""  gtw
 SG_ APP_sw190_deserParityError m190 : 23|1@1+ (1,0) [0|1] ""  gtw
 SG_ APP_sw052_sensorBlocked m52 : 23|1@1+ (1,0) [0|1] ""  gtw
 SG_ APP_sw194_leadDx m194 : 22|8@1+ (0.1,0) [0|25] "m"  gtw
 SG_ APP_sw184_firstFrameGrabFailure m184 : 22|1@1+ (1,0) [0|1] ""  gtw
 SG_ APP_sw073_freespaceLDW m73 : 22|2@1+ (1,0) [0|3] ""  gtw
 SG_ APP_sw006_BlurredImage m6 : 22|1@1+ (1,0) [0|1] ""  gtw
 SG_ APP_sw192_vehicleAutopilotType m192 : 22|2@1+ (1,0) [0|2] ""  gtw
 SG_ APP_sw052_rspError m52 : 22|1@1+ (1,0) [0|1] ""  gtw
 SG_ APP_sw053_a16bdyInvalidCount m53 : 22|1@1+ (1,0) [0|1] ""  gtw
 SG_ APP_sw146_numElementsQueued m146 : 22|9@1+ (10,0) [0|5110] "1"  gtw
 SG_ APP_sw185_firstFrameGrabFailure m185 : 22|1@1+ (1,0) [0|1] ""  gtw
 SG_ APP_sw188_firstFrameGrabFailure m188 : 22|1@1+ (1,0) [0|1] ""  gtw
 SG_ APP_sw230_sensor7Blocked m230 : 22|1@1+ (1,0) [0|1] ""  gtw
 SG_ APP_sw004_espMIA m4 : 22|1@1+ (1,0) [0|1] ""  gtw
 SG_ APP_sw048_ecuReset m48 : 22|1@1+ (1,0) [0|1] ""  gtw
 SG_ APP_sw281_firstFrameGrabFailure m281 : 22|1@1+ (1,0) [0|1] ""  gtw
 SG_ APP_sw276_firstFrameGrabFailure m276 : 22|1@1+ (1,0) [0|1] ""  gtw
 SG_ APP_sw038_TooManyResets m38 : 22|1@1+ (1,0) [0|1] ""  gtw
 SG_ APP_sw057_radarMapData m57 : 22|1@1+ (1,0) [0|1] ""  gtw
 SG_ APP_sw182_firstFrameGrabFailure m182 : 22|1@1+ (1,0) [0|1] ""  gtw
 SG_ APP_sw140_backupCamI2CbusFault m140 : 22|1@1+ (1,0) [0|1] ""  gtw
 SG_ APP_sw190_firstFrameGrabFailure m190 : 22|1@1+ (1,0) [0|1] ""  gtw
 SG_ APP_sw027_Clock_Monitor_0_Off m27 : 22|1@1+ (1,0) [0|1] ""  gtw
 SG_ APP_sw263_elkConditionsMet m263 : 22|1@1+ (1,0) [0|1] ""  gtw
 SG_ APP_sw270_lRepeaterBlocked m270 : 22|1@1+ (1,0) [0|1] ""  gtw
 SG_ APP_sw189_firstFrameGrabFailure m189 : 22|1@1+ (1,0) [0|1] ""  gtw
 SG_ APP_sw278_firstFrameGrabFailure m278 : 22|1@1+ (1,0) [0|1] ""  gtw
 SG_ APP_sw269_rRepeaterStreamExit m269 : 22|1@1+ (1,0) [0|1] ""  gtw
 SG_ APP_sw277_firstFrameGrabFailure m277 : 22|1@1+ (1,0) [0|1] ""  gtw
 SG_ APP_sw183_firstFrameGrabFailure m183 : 22|1@1+ (1,0) [0|1] ""  gtw
 SG_ APP_sw045_lrrObj00A m45 : 22|1@1+ (1,0) [0|1] ""  gtw
 SG_ APP_sw059_sdiFront m59 : 22|1@1+ (1,0) [0|1] ""  gtw
 SG_ APP_sw280_firstFrameGrabFailure m280 : 22|1@1+ (1,0) [0|1] ""  gtw
 SG_ APP_sw005_camCommonMsg m5 : 22|1@1+ (1,0) [0|1] ""  gtw
 SG_ APP_sw186_firstFrameGrabFailure m186 : 22|1@1+ (1,0) [0|1] ""  gtw
 SG_ APP_sw279_firstFrameGrabFailure m279 : 22|1@1+ (1,0) [0|1] ""  gtw
 SG_ APP_sw274_firstFrameGrabFailure m274 : 22|1@1+ (1,0) [0|1] ""  gtw
 SG_ APP_sw259_do_stw_rate m259 : 22|1@1+ (1,0) [0|1] ""  gtw
 SG_ APP_sw203_roadClass m203 : 22|3@1+ (1,0) [0|7] ""  gtw
 SG_ APP_sw187_firstFrameGrabFailure m187 : 22|1@1+ (1,0) [0|1] ""  gtw
 SG_ APP_sw017_Camera_Msg_TFL_MIA m17 : 22|1@1+ (1,0) [0|1] ""  gtw
 SG_ APP_sw282_firstFrameGrabFailure m282 : 22|1@1+ (1,0) [0|1] ""  gtw
 SG_ APP_sw193_smearedSpots m193 : 22|1@1+ (1,0) [0|1] ""  gtw
 SG_ APP_sw015_BlurredImage m15 : 22|2@1+ (1,0) [0|3] ""  gtw
 SG_ APP_sw275_firstFrameGrabFailure m275 : 22|1@1+ (1,0) [0|1] ""  gtw
 SG_ APP_sw080_freespace_check m80 : 22|1@1+ (1,0) [0|1] ""  gtw
 SG_ APP_sw259_do_stw_angle m259 : 21|1@1+ (1,0) [0|1] ""  gtw
 SG_ APP_sw199_abortCodePARK m199 : 21|5@1+ (1,0) [0|31] ""  gtw
 SG_ APP_sw270_rPillarBlocked m270 : 21|1@1+ (1,0) [0|1] ""  gtw
 SG_ APP_sw006_Splashes m6 : 21|1@1+ (1,0) [0|1] ""  gtw
 SG_ APP_sw045_lrrRadarStatus m45 : 21|1@1+ (1,0) [0|1] ""  gtw
 SG_ APP_sw195_s12Blocked m195 : 21|1@1+ (1,0) [0|1] ""  gtw
 SG_ APP_sw017_Camera_Msg_FCW_PCW_MIA m17 : 21|1@1+ (1,0) [0|1] ""  gtw
 SG_ APP_sw202_s12Blocked m202 : 21|1@1+ (1,0) [0|1] ""  gtw
 SG_ APP_sw158_coolant m158 : 21|1@1+ (1,0) [0|1] ""  gtw
 SG_ APP_sw213_endSpeed m213 : 21|10@1+ (0.1,-10) [-10|92.3] "m/s"  gtw
 SG_ APP_sw052_chirpError m52 : 21|1@1+ (1,0) [0|1] ""  gtw
 SG_ APP_sw048_ecuWatchdog m48 : 21|1@1+ (1,0) [0|1] ""  gtw
 SG_ APP_sw005_camObjHeader m5 : 21|1@1+ (1,0) [0|1] ""  gtw
 SG_ APP_sw038_FullBlockage m38 : 21|1@1+ (1,0) [0|1] ""  gtw
 SG_ APP_sw263_laneTooNarrow m263 : 21|1@1+ (1,0) [0|1] ""  gtw
 SG_ APP_sw013_numEyeqResets m13 : 21|3@1+ (1,0) [0|7] ""  gtw
 SG_ APP_sw200_endSpeed m200 : 21|10@1+ (0.1,-10) [-10|92.3] "m/s"  gtw
 SG_ APP_sw057_gpsVehicleSpeed m57 : 21|1@1+ (1,0) [0|1] ""  gtw
 SG_ APP_sw273_alarmStrikes m273 : 21|3@1+ (1,0) [0|7] ""  gtw
 SG_ APP_sw069_eacStatus m69 : 21|4@1+ (1,0) [0|15] ""  gtw
 SG_ APP_sw011_scaBlinker m11 : 21|2@1+ (1,0) [0|3] ""  gtw
 SG_ APP_sw193_smearedHalos m193 : 21|1@1+ (1,0) [0|1] ""  gtw
 SG_ APP_sw059_pscVehSlot m59 : 21|1@1+ (1,0) [0|1] ""  gtw
 SG_ APP_sw080_ultrasonic_obs_check m80 : 21|1@1+ (1,0) [0|1] ""  gtw
 SG_ APP_sw269_lRepeaterStreamExit m269 : 21|1@1+ (1,0) [0|1] ""  gtw
 SG_ APP_sw004_radDynamicsError m4 : 21|1@1+ (1,0) [0|1] ""  gtw
 SG_ APP_sw051_unused m51 : 21|3@1+ (1,0) [0|7] ""  gtw
 SG_ APP_sw027_Clock_Monitor_0_Low m27 : 21|1@1+ (1,0) [0|1] ""  gtw
 SG_ APP_sw028_unusedBits m28 : 21|11@1+ (1,0) [0|2047] ""  gtw
 SG_ APP_sw271_direction m271 : 21|1@1+ (1,0) [0|1] ""  gtw
 SG_ APP_sw053_a15adasMIA m53 : 21|1@1+ (1,0) [0|1] ""  gtw
 SG_ APP_sw230_sensor6Blocked m230 : 21|1@1+ (1,0) [0|1] ""  gtw
 SG_ APP_sw192_hardwareType m192 : 20|2@1+ (1,0) [0|2] ""  gtw
 SG_ APP_sw024_numVirtualLaneVeh m24 : 20|4@1+ (1,0) [0|15] ""  gtw
 SG_ APP_sw279_tempMonitorFailure m279 : 20|2@1+ (1,0) [0|2] ""  gtw
 SG_ APP_sw005_fullBlockage m5 : 20|1@1+ (1,0) [0|1] ""  gtw
 SG_ APP_sw051_a52radomeHtrInop m51 : 20|1@1+ (1,0) [0|1] ""  gtw
 SG_ APP_sw028_inv_multifrm_next m28 : 20|1@1+ (1,0) [0|1] ""  gtw
 SG_ APP_sw080_rad_tar_5_check m80 : 20|1@1+ (1,0) [0|1] ""  gtw
 SG_ APP_sw052_underTemperature m52 : 20|1@1+ (1,0) [0|1] ""  gtw
 SG_ APP_sw270_lPillarBlocked m270 : 20|1@1+ (1,0) [0|1] ""  gtw
 SG_ APP_sw073_rawMobileyeLDW m73 : 20|2@1+ (1,0) [0|3] ""  gtw
 SG_ APP_sw038_AutofixOutOfCalibYaw m38 : 20|1@1+ (1,0) [0|1] ""  gtw
 SG_ APP_sw187_tempMonitorFailure m187 : 20|2@1+ (1,0) [0|2] ""  gtw
 SG_ APP_sw195_s11Blocked m195 : 20|1@1+ (1,0) [0|1] ""  gtw
 SG_ APP_sw184_tempMonitorFailure m184 : 20|2@1+ (1,0) [0|2] ""  gtw
 SG_ APP_sw139_rRepeatCamSensorFault m139 : 20|3@1+ (1,0) [0|4] ""  gtw
 SG_ APP_sw045_lrrPacketEnder m45 : 20|1@1+ (1,0) [0|1] ""  gtw
 SG_ APP_sw047_roadClass m47 : 20|3@1+ (1,0) [0|7] ""  gtw
 SG_ APP_sw273_side m273 : 20|1@1+ (1,0) [0|1] ""  gtw
 SG_ APP_sw022_recordId m22 : 20|12@1+ (1,0) [0|4095] ""  gtw
 SG_ APP_sw275_tempMonitorFailure m275 : 20|2@1+ (1,0) [0|2] ""  gtw
 SG_ APP_sw282_tempMonitorFailure m282 : 20|2@1+ (1,0) [0|2] ""  gtw
 SG_ APP_sw015_LowSun m15 : 20|2@1+ (1,0) [0|3] ""  gtw
 SG_ APP_sw057_driverAssistMapData m57 : 20|1@1+ (1,0) [0|1] ""  gtw
 SG_ APP_sw145_problemSaving m145 : 20|1@1+ (1,0) [0|1] ""  gtw
 SG_ APP_sw263_outOfSpeedRegion m263 : 20|1@1+ (1,0) [0|1] ""  gtw
 SG_ APP_sw220_vehicleSpeed m220 : 20|12@1+ (0.05,-25) [-25|179.75] "mph"  gtw
 SG_ APP_sw265_surroundCameraStatus m265 : 20|2@1+ (1,0) [0|2] ""  gtw
 SG_ APP_sw134_narrowCamSensorFault m134 : 20|3@1+ (1,0) [0|4] ""  gtw
 SG_ APP_sw193_partialBlockage m193 : 20|1@1+ (1,0) [0|1] ""  gtw
 SG_ APP_sw053_a14sccmMIA m53 : 20|1@1+ (1,0) [0|1] ""  gtw
 SG_ APP_sw133_mainCamSensorFault m133 : 20|3@1+ (1,0) [0|4] ""  gtw
 SG_ APP_sw011_scaRight m11 : 20|1@1+ (1,0) [0|1] ""  gtw
 SG_ APP_sw136_lPillarCamSensorFault m136 : 20|3@1+ (1,0) [0|4] ""  gtw
 SG_ APP_sw017_Camera_Msg_Common_MIA m17 : 20|1@1+ (1,0) [0|1] ""  gtw
 SG_ APP_sw135_fisheyeCamSensorFault m135 : 20|3@1+ (1,0) [0|4] ""  gtw
 SG_ APP_sw188_tempMonitorFailure m188 : 20|2@1+ (1,0) [0|2] ""  gtw
 SG_ APP_sw006_SunRay m6 : 20|1@1+ (1,0) [0|1] ""  gtw
 SG_ APP_sw213_autopilotRestricted m213 : 20|1@1+ (1,0) [0|1] ""  gtw
 SG_ APP_sw185_tempMonitorFailure m185 : 20|2@1+ (1,0) [0|2] ""  gtw
 SG_ APP_sw281_tempMonitorFailure m281 : 20|2@1+ (1,0) [0|2] ""  gtw
 SG_ APP_sw182_tempMonitorFailure m182 : 20|2@1+ (1,0) [0|2] ""  gtw
 SG_ APP_sw150_chassisControl m150 : 20|1@1+ (1,0) [0|1] ""  gtw
 SG_ APP_sw202_s11Blocked m202 : 20|1@1+ (1,0) [0|1] ""  gtw
 SG_ APP_sw069_parkMismatch m69 : 20|1@1+ (1,0) [0|1] ""  gtw
 SG_ APP_sw276_tempMonitorFailure m276 : 20|2@1+ (1,0) [0|2] ""  gtw
 SG_ APP_sw004_radMia m4 : 20|1@1+ (1,0) [0|1] ""  gtw
 SG_ APP_sw025_road_class m25 : 20|3@1+ (1,0) [0|7] ""  gtw
 SG_ APP_sw137_rPillarCamSensorFault m137 : 20|3@1+ (1,0) [0|4] ""  gtw
 SG_ APP_sw200_autopilotRestricted m200 : 20|1@1+ (1,0) [0|1] ""  gtw
 SG_ APP_sw278_tempMonitorFailure m278 : 20|2@1+ (1,0) [0|2] ""  gtw
 SG_ APP_sw071_endPosX m71 : 20|10@1+ (0.05,-25.6) [-25.6|25.5] "m"  gtw
 SG_ APP_sw219_vehicleSpeed m219 : 20|12@1+ (0.05,-25) [-25|179.75] "mph"  gtw
 SG_ APP_sw027_PLL_0_Failure m27 : 20|1@1+ (1,0) [0|1] ""  gtw
 SG_ APP_sw190_tempMonitorFailure m190 : 20|2@1+ (1,0) [0|2] ""  gtw
 SG_ APP_sw189_tempMonitorFailure m189 : 20|2@1+ (1,0) [0|2] ""  gtw
 SG_ APP_sw059_pscStatus m59 : 20|1@1+ (1,0) [0|1] ""  gtw
 SG_ APP_sw203_curbType m203 : 20|2@1+ (1,0) [0|3] ""  gtw
 SG_ APP_sw010_HorizontalMisalignment m10 : 20|16@1+ (0.00137332,-45) [-45|45.0005262] "deg"  gtw
 SG_ APP_sw186_tempMonitorFailure m186 : 20|2@1+ (1,0) [0|2] ""  gtw
 SG_ APP_sw259_do_aeb_brake_pedal m259 : 20|1@1+ (1,0) [0|1] ""  gtw
 SG_ APP_sw280_tempMonitorFailure m280 : 20|2@1+ (1,0) [0|2] ""  gtw
 SG_ APP_sw230_sensor5Blocked m230 : 20|1@1+ (1,0) [0|1] ""  gtw
 SG_ APP_sw183_tempMonitorFailure m183 : 20|2@1+ (1,0) [0|2] ""  gtw
 SG_ APP_sw277_tempMonitorFailure m277 : 20|2@1+ (1,0) [0|2] ""  gtw
 SG_ APP_sw138_lRepeatCamSensorFault m138 : 20|3@1+ (1,0) [0|4] ""  gtw
 SG_ APP_sw048_checkStop m48 : 20|1@1+ (1,0) [0|1] ""  gtw
 SG_ APP_sw158_sensors m158 : 20|1@1+ (1,0) [0|1] ""  gtw
 SG_ APP_sw269_rPillarStreamExit m269 : 20|1@1+ (1,0) [0|1] ""  gtw
 SG_ APP_sw147_selfieCamSensorFault m147 : 20|3@1+ (1,0) [0|4] ""  gtw
 SG_ APP_sw274_tempMonitorFailure m274 : 20|2@1+ (1,0) [0|2] ""  gtw
 SG_ APP_sw137_rPillarCamI2CbusFault m137 : 19|1@1+ (1,0) [0|1] ""  gtw
 SG_ APP_sw010_a08PlantMode m10 : 19|1@1+ (1,0) [0|1] ""  gtw
 SG_ APP_sw277_gainControlFailure m277 : 19|1@1+ (1,0) [0|1] ""  gtw
 SG_ APP_sw280_gainControlFailure m280 : 19|1@1+ (1,0) [0|1] ""  gtw
 SG_ APP_sw150_torque m150 : 19|1@1+ (1,0) [0|1] ""  gtw
 SG_ APP_sw005_partialBlockage m5 : 19|1@1+ (1,0) [0|1] ""  gtw
 SG_ APP_sw183_gainControlFailure m183 : 19|1@1+ (1,0) [0|1] ""  gtw
 SG_ APP_sw184_gainControlFailure m184 : 19|1@1+ (1,0) [0|1] ""  gtw
 SG_ APP_sw135_fisheyeCamI2CbusFault m135 : 19|1@1+ (1,0) [0|1] ""  gtw
 SG_ APP_sw136_lPillarCamI2CbusFault m136 : 19|1@1+ (1,0) [0|1] ""  gtw
 SG_ APP_sw133_mainCamI2CbusFault m133 : 19|1@1+ (1,0) [0|1] ""  gtw
 SG_ APP_sw190_gainControlFailure m190 : 19|1@1+ (1,0) [0|1] ""  gtw
 SG_ APP_sw259_do_brake_pedal m259 : 19|1@1+ (1,0) [0|1] ""  gtw
 SG_ APP_sw189_gainControlFailure m189 : 19|1@1+ (1,0) [0|1] ""  gtw
 SG_ APP_sw263_notStableInLane m263 : 19|1@1+ (1,0) [0|1] ""  gtw
 SG_ APP_sw070_lastTireFitment m70 : 19|3@1+ (1,0) [0|7] ""  gtw
 SG_ APP_sw048_stackOverflow m48 : 19|1@1+ (1,0) [0|1] ""  gtw
 SG_ APP_sw265_mmLocalizedEdge m265 : 19|1@1+ (1,0) [0|1] ""  gtw
 SG_ APP_sw052_overTemperature m52 : 19|1@1+ (1,0) [0|1] ""  gtw
 SG_ APP_sw027_CPU_Checkstop_Error m27 : 19|1@1+ (1,0) [0|1] ""  gtw
 SG_ APP_sw161_imagerOutOfSpecTemp m161 : 19|1@1+ (1,0) [0|1] ""  gtw
 SG_ APP_sw138_lRepeatCamI2CbusFault m138 : 19|1@1+ (1,0) [0|1] ""  gtw
 SG_ APP_sw145_insaneCal m145 : 19|1@1+ (1,0) [0|1] ""  gtw
 SG_ APP_sw269_lPillarStreamExit m269 : 19|1@1+ (1,0) [0|1] ""  gtw
 SG_ APP_sw193_outOfFocusImage m193 : 19|1@1+ (1,0) [0|1] ""  gtw
 SG_ APP_sw274_gainControlFailure m274 : 19|1@1+ (1,0) [0|1] ""  gtw
 SG_ APP_sw042_abort_reason m42 : 19|5@1+ (1,0) [0|25] ""  gtw
 SG_ APP_sw266_rPillarStreamStatus m266 : 19|3@1+ (1,0) [0|7] ""  gtw
 SG_ APP_sw185_gainControlFailure m185 : 19|1@1+ (1,0) [0|1] ""  gtw
 SG_ APP_sw166_expectedColorFilter m166 : 19|2@1+ (1,0) [0|3] ""  gtw
 SG_ APP_sw017_Camera_Msg_Hlb_MIA m17 : 19|1@1+ (1,0) [0|1] ""  gtw
 SG_ APP_sw004_radSGUFailure m4 : 19|1@1+ (1,0) [0|1] ""  gtw
 SG_ APP_sw186_gainControlFailure m186 : 19|1@1+ (1,0) [0|1] ""  gtw
 SG_ APP_sw146_packageType m146 : 19|3@1+ (1,0) [0|1] ""  gtw
 SG_ APP_sw201_steeringErrorOAL m201 : 19|3@1+ (1,0) [0|7] ""  gtw
 SG_ APP_sw069_sccmMia m69 : 19|1@1+ (1,0) [0|1] ""  gtw
 SG_ APP_sw168_expectedColorFilter m168 : 19|2@1+ (1,0) [0|3] ""  gtw
 SG_ APP_sw053_a13gtwMIA m53 : 19|1@1+ (1,0) [0|1] ""  gtw
 SG_ APP_sw057_autopilotControl m57 : 19|1@1+ (1,0) [0|1] ""  gtw
 SG_ APP_sw147_selfieCamI2CbusFault m147 : 19|1@1+ (1,0) [0|1] ""  gtw
 SG_ APP_sw230_sensor4Blocked m230 : 19|1@1+ (1,0) [0|1] ""  gtw
 SG_ APP_sw140_backupCamDeserFault m140 : 19|3@1+ (1,0) [0|4] ""  gtw
 SG_ APP_sw202_s8Blocked m202 : 19|1@1+ (1,0) [0|1] ""  gtw
 SG_ APP_sw270_rRepeaterStreamExit m270 : 19|1@1+ (1,0) [0|1] ""  gtw
 SG_ APP_sw167_expectedColorFilter m167 : 19|2@1+ (1,0) [0|3] ""  gtw
 SG_ APP_sw278_gainControlFailure m278 : 19|1@1+ (1,0) [0|1] ""  gtw
 SG_ APP_sw028_inv_multifrm_id m28 : 19|1@1+ (1,0) [0|1] ""  gtw
 SG_ APP_sw282_gainControlFailure m282 : 19|1@1+ (1,0) [0|1] ""  gtw
 SG_ APP_sw275_gainControlFailure m275 : 19|1@1+ (1,0) [0|1] ""  gtw
 SG_ APP_sw195_s8Blocked m195 : 19|1@1+ (1,0) [0|1] ""  gtw
 SG_ APP_sw162_expectedColorFilter m162 : 19|2@1+ (1,0) [0|3] ""  gtw
 SG_ APP_sw169_expectedColorFilter m169 : 19|2@1+ (1,0) [0|3] ""  gtw
 SG_ APP_sw281_gainControlFailure m281 : 19|1@1+ (1,0) [0|1] ""  gtw
 SG_ APP_sw198_tsrMsgInvalid m198 : 19|1@1+ (1,0) [0|1] ""  gtw
 SG_ APP_sw182_gainControlFailure m182 : 19|1@1+ (1,0) [0|1] ""  gtw
 SG_ APP_sw276_gainControlFailure m276 : 19|1@1+ (1,0) [0|1] ""  gtw
 SG_ APP_sw170_expectedColorFilter m170 : 19|2@1+ (1,0) [0|3] ""  gtw
 SG_ APP_sw164_expectedColorFilter m164 : 19|2@1+ (1,0) [0|3] ""  gtw
 SG_ APP_sw187_gainControlFailure m187 : 19|1@1+ (1,0) [0|1] ""  gtw
 SG_ APP_sw134_narrowCamI2CbusFault m134 : 19|1@1+ (1,0) [0|1] ""  gtw
 SG_ APP_sw038_AutofixOutOfCalibHorzn m38 : 19|1@1+ (1,0) [0|1] ""  gtw
 SG_ APP_sw045_lrrAlertMatrix0 m45 : 19|1@1+ (1,0) [0|1] ""  gtw
 SG_ APP_sw188_gainControlFailure m188 : 19|1@1+ (1,0) [0|1] ""  gtw
 SG_ APP_sw139_rRepeatCamI2CbusFault m139 : 19|1@1+ (1,0) [0|1] ""  gtw
 SG_ APP_sw059_pasRearMiddle m59 : 19|1@1+ (1,0) [0|1] ""  gtw
 SG_ APP_sw080_stw_angle_check m80 : 19|1@1+ (1,0) [0|1] ""  gtw
 SG_ APP_sw163_expectedColorFilter m163 : 19|2@1+ (1,0) [0|3] ""  gtw
 SG_ APP_sw158_lighting m158 : 19|1@1+ (1,0) [0|1] ""  gtw
 SG_ APP_sw051_a09configMismatch m51 : 19|1@1+ (1,0) [0|1] ""  gtw
 SG_ APP_sw011_scaLeft m11 : 19|1@1+ (1,0) [0|1] ""  gtw
 SG_ APP_sw279_gainControlFailure m279 : 19|1@1+ (1,0) [0|1] ""  gtw
 SG_ APP_sw006_OutOfFocusImage m6 : 19|1@1+ (1,0) [0|1] ""  gtw
 SG_ APP_sw165_expectedColorFilter m165 : 19|2@1+ (1,0) [0|3] ""  gtw
 SG_ APP_sw152_wheelSpeeds m152 : 19|1@1+ (1,0) [0|1] ""  gtw
 SG_ APP_sw202_s7Blocked m202 : 18|1@1+ (1,0) [0|1] ""  gtw
 SG_ APP_sw189_frameGrabFailure m189 : 18|1@1+ (1,0) [0|1] ""  gtw
 SG_ APP_sw045_radcAccTargObj1A m45 : 18|1@1+ (1,0) [0|1] ""  gtw
 SG_ APP_sw190_frameGrabFailure m190 : 18|1@1+ (1,0) [0|1] ""  gtw
 SG_ APP_sw006_radCalibration m6 : 18|1@1+ (1,0) [0|1] ""  gtw
 SG_ APP_sw184_frameGrabFailure m184 : 18|1@1+ (1,0) [0|1] ""  gtw
 SG_ APP_sw009_DI_MIA m9 : 18|1@1+ (1,0) [0|1] ""  gtw
 SG_ APP_sw198_tflMsgInvalid m198 : 18|1@1+ (1,0) [0|1] ""  gtw
 SG_ APP_sw026_tardiness m26 : 18|9@1+ (0.25,0) [0|127.75] "ms"  gtw
 SG_ APP_sw187_frameGrabFailure m187 : 18|1@1+ (1,0) [0|1] ""  gtw
 SG_ APP_sw150_systemStatus m150 : 18|1@1+ (1,0) [0|1] ""  gtw
 SG_ APP_sw080_road_class_check m80 : 18|1@1+ (1,0) [0|1] ""  gtw
 SG_ APP_sw281_frameGrabFailure m281 : 18|1@1+ (1,0) [0|1] ""  gtw
 SG_ APP_sw182_frameGrabFailure m182 : 18|1@1+ (1,0) [0|1] ""  gtw
 SG_ APP_sw276_frameGrabFailure m276 : 18|1@1+ (1,0) [0|1] ""  gtw
 SG_ APP_sw259_do_aeb_accel_pedal m259 : 18|1@1+ (1,0) [0|1] ""  gtw
 SG_ APP_sw263_timerExpired m263 : 18|1@1+ (1,0) [0|1] ""  gtw
 SG_ APP_sw073_escalateLDWreason m73 : 18|2@1+ (1,0) [0|3] ""  gtw
 SG_ APP_sw279_frameGrabFailure m279 : 18|1@1+ (1,0) [0|1] ""  gtw
 SG_ APP_sw059_pasFrontMiddle m59 : 18|1@1+ (1,0) [0|1] ""  gtw
 SG_ APP_sw188_frameGrabFailure m188 : 18|1@1+ (1,0) [0|1] ""  gtw
 SG_ APP_sw010_a06calibNotOK m10 : 18|1@1+ (1,0) [0|1] ""  gtw
 SG_ APP_sw005_RadarMisalignment m5 : 18|1@1+ (1,0) [0|1] ""  gtw
 SG_ APP_sw152_wheelRotation m152 : 18|1@1+ (1,0) [0|1] ""  gtw
 SG_ APP_sw145_rollSpike m145 : 18|1@1+ (1,0) [0|1] ""  gtw
 SG_ APP_sw017_Camera_Msg_Tsr_MIA m17 : 18|1@1+ (1,0) [0|1] ""  gtw
 SG_ APP_sw038_AutofixOutOfCalib m38 : 18|1@1+ (1,0) [0|1] ""  gtw
 SG_ APP_sw230_sensor3Blocked m230 : 18|1@1+ (1,0) [0|1] ""  gtw
 SG_ APP_sw057_driverAssistControl m57 : 18|1@1+ (1,0) [0|1] ""  gtw
 SG_ APP_sw269_fisheyeStreamExit m269 : 18|1@1+ (1,0) [0|1] ""  gtw
 SG_ APP_sw186_frameGrabFailure m186 : 18|1@1+ (1,0) [0|1] ""  gtw
 SG_ APP_sw282_frameGrabFailure m282 : 18|1@1+ (1,0) [0|1] ""  gtw
 SG_ APP_sw275_frameGrabFailure m275 : 18|1@1+ (1,0) [0|1] ""  gtw
 SG_ APP_sw278_frameGrabFailure m278 : 18|1@1+ (1,0) [0|1] ""  gtw
 SG_ APP_sw161_rawImageTimeout m161 : 18|1@1+ (1,0) [0|1] ""  gtw
 SG_ APP_sw193_impairedVD m193 : 18|1@1+ (1,0) [0|1] ""  gtw
 SG_ APP_sw027_Unused_Bit_0 m27 : 18|1@1+ (1,0) [0|1] ""  gtw
 SG_ APP_sw028_inv_multifrm_1st m28 : 18|1@1+ (1,0) [0|1] ""  gtw
 SG_ APP_sw270_lRepeaterStreamExit m270 : 18|1@1+ (1,0) [0|1] ""  gtw
 SG_ APP_sw015_RadarMisalignment m15 : 18|2@1+ (1,0) [0|3] ""  gtw
 SG_ APP_sw227_vehicleSpeed m227 : 18|12@1+ (0.05,-25) [-25|179.75] "mph"  gtw
 SG_ APP_sw158_status m158 : 18|1@1+ (1,0) [0|1] ""  gtw
 SG_ APP_sw004_radSensorBlind m4 : 18|1@1+ (1,0) [0|1] ""  gtw
 SG_ APP_sw053_a12espMIA m53 : 18|1@1+ (1,0) [0|1] ""  gtw
 SG_ APP_sw185_frameGrabFailure m185 : 18|1@1+ (1,0) [0|1] ""  gtw
 SG_ APP_sw192_chassisType m192 : 18|2@1+ (1,0) [0|3] ""  gtw
 SG_ APP_sw274_frameGrabFailure m274 : 18|1@1+ (1,0) [0|1] ""  gtw
 SG_ APP_sw069_parkMia m69 : 18|1@1+ (1,0) [0|1] ""  gtw
 SG_ APP_sw265_mmHasRoute m265 : 18|1@1+ (1,0) [0|1] ""  gtw
 SG_ APP_sw048_powerIssue m48 : 18|1@1+ (1,0) [0|1] ""  gtw
 SG_ APP_sw052_HWFail m52 : 18|1@1+ (1,0) [0|1] ""  gtw
 SG_ APP_sw195_s7Blocked m195 : 18|1@1+ (1,0) [0|1] ""  gtw
 SG_ APP_sw051_a03vBatHigh m51 : 18|1@1+ (1,0) [0|1] ""  gtw
 SG_ APP_sw157_steeringAngleSensor m157 : 18|1@1+ (1,0) [0|1] ""  gtw
 SG_ APP_sw280_frameGrabFailure m280 : 18|1@1+ (1,0) [0|1] ""  gtw
 SG_ APP_sw035_wheelSpeeds m35 : 18|1@1+ (1,0) [0|1] ""  gtw
 SG_ APP_sw183_frameGrabFailure m183 : 18|1@1+ (1,0) [0|1] ""  gtw
 SG_ APP_sw277_frameGrabFailure m277 : 18|1@1+ (1,0) [0|1] ""  gtw
 SG_ APP_sw027_Core_Reset m27 : 17|1@1+ (1,0) [0|1] ""  gtw
 SG_ APP_sw219_roadClass m219 : 17|3@1+ (1,0) [0|7] ""  gtw
 SG_ APP_sw160_thsStatus m160 : 17|1@1+ (1,0) [0|1] ""  gtw
 SG_ APP_sw185_bufferError m185 : 17|1@1+ (1,0) [0|1] ""  gtw
 SG_ APP_sw004_radHWFailure m4 : 17|1@1+ (1,0) [0|1] ""  gtw
 SG_ APP_sw265_mpLocalizedWay m265 : 17|1@1+ (1,0) [0|1] ""  gtw
 SG_ APP_sw161_hdmiDisplayError m161 : 17|1@1+ (1,0) [0|1] ""  gtw
 SG_ APP_sw145_yawSpike m145 : 17|1@1+ (1,0) [0|1] ""  gtw
 SG_ APP_sw057_csaRoadCurvature m57 : 17|1@1+ (1,0) [0|1] ""  gtw
 SG_ APP_sw269_narrowStreamExit m269 : 17|1@1+ (1,0) [0|1] ""  gtw
 SG_ APP_sw153_inertial2 m153 : 17|1@1+ (1,0) [0|1] ""  gtw
 SG_ APP_sw184_bufferError m184 : 17|1@1+ (1,0) [0|1] ""  gtw
 SG_ APP_sw009_DI_aeb_unresponsive m9 : 17|1@1+ (1,0) [0|1] ""  gtw
 SG_ APP_sw230_sensor2Blocked m230 : 17|1@1+ (1,0) [0|1] ""  gtw
 SG_ APP_sw005_AutofixOutOfCalibYaw m5 : 17|1@1+ (1,0) [0|1] ""  gtw
 SG_ APP_sw195_s6Blocked m195 : 17|1@1+ (1,0) [0|1] ""  gtw
 SG_ APP_sw190_bufferError m190 : 17|1@1+ (1,0) [0|1] ""  gtw
 SG_ APP_sw189_bufferError m189 : 17|1@1+ (1,0) [0|1] ""  gtw
 SG_ APP_sw038_OutOfFocusImage m38 : 17|1@1+ (1,0) [0|1] ""  gtw
 SG_ APP_sw280_bufferError m280 : 17|1@1+ (1,0) [0|1] ""  gtw
 SG_ APP_sw193_fullBlockage m193 : 17|1@1+ (1,0) [0|1] ""  gtw
 SG_ APP_sw157_rightStalk m157 : 17|1@1+ (1,0) [0|1] ""  gtw
 SG_ APP_sw227_sensorNumber m227 : 17|1@1+ (1,0) [0|1] ""  gtw
 SG_ APP_sw166_detectedColorFilter m166 : 17|2@1+ (1,0) [0|3] ""  gtw
 SG_ APP_sw277_bufferError m277 : 17|1@1+ (1,0) [0|1] ""  gtw
 SG_ APP_sw010_a05calibReqd m10 : 17|1@1+ (1,0) [0|1] ""  gtw
 SG_ APP_sw183_bufferError m183 : 17|1@1+ (1,0) [0|1] ""  gtw
 SG_ APP_sw198_partialBlockage m198 : 17|1@1+ (1,0) [0|1] ""  gtw
 SG_ APP_sw035_wheelRotation m35 : 17|1@1+ (1,0) [0|1] ""  gtw
 SG_ APP_sw188_bufferError m188 : 17|1@1+ (1,0) [0|1] ""  gtw
 SG_ APP_sw006_RadarMisaligned m6 : 17|1@1+ (1,0) [0|1] ""  gtw
 SG_ APP_sw279_bufferError m279 : 17|1@1+ (1,0) [0|1] ""  gtw
 SG_ APP_sw069_espMia m69 : 17|1@1+ (1,0) [0|1] ""  gtw
 SG_ APP_sw168_detectedColorFilter m168 : 17|2@1+ (1,0) [0|3] ""  gtw
 SG_ APP_sw276_bufferError m276 : 17|1@1+ (1,0) [0|1] ""  gtw
 SG_ APP_sw167_detectedColorFilter m167 : 17|2@1+ (1,0) [0|3] ""  gtw
 SG_ APP_sw029_unusedBits m29 : 17|15@1+ (1,0) [0|32767] ""  gtw
 SG_ APP_sw182_bufferError m182 : 17|1@1+ (1,0) [0|1] ""  gtw
 SG_ APP_sw159_switchStatus m159 : 17|1@1+ (1,0) [0|1] ""  gtw
 SG_ APP_sw052_sensorDirty m52 : 17|1@1+ (1,0) [0|1] ""  gtw
 SG_ APP_sw150_speed m150 : 17|1@1+ (1,0) [0|1] ""  gtw
 SG_ APP_sw281_bufferError m281 : 17|1@1+ (1,0) [0|1] ""  gtw
 SG_ APP_sw045_radcInfo m45 : 17|1@1+ (1,0) [0|1] ""  gtw
 SG_ APP_sw059_oocStatus m59 : 17|1@1+ (1,0) [0|1] ""  gtw
 SG_ APP_sw073_silentEscalatedLDW m73 : 17|1@1+ (1,0) [0|1] ""  gtw
 SG_ APP_sw220_roadClass m220 : 17|3@1+ (1,0) [0|7] ""  gtw
 SG_ APP_sw048_thermalIssue m48 : 17|1@1+ (1,0) [0|1] ""  gtw
 SG_ APP_sw162_detectedColorFilter m162 : 17|2@1+ (1,0) [0|3] ""  gtw
 SG_ APP_sw187_bufferError m187 : 17|1@1+ (1,0) [0|1] ""  gtw
 SG_ APP_sw028_rx_inv_len m28 : 17|1@1+ (1,0) [0|1] ""  gtw
 SG_ APP_sw064_status m64 : 17|1@1+ (1,0) [0|1] ""  gtw
 SG_ APP_sw170_detectedColorFilter m170 : 17|2@1+ (1,0) [0|3] ""  gtw
 SG_ APP_sw202_s6Blocked m202 : 17|1@1+ (1,0) [0|1] ""  gtw
 SG_ APP_sw278_bufferError m278 : 17|1@1+ (1,0) [0|1] ""  gtw
 SG_ APP_sw169_detectedColorFilter m169 : 17|2@1+ (1,0) [0|3] ""  gtw
 SG_ APP_sw053_a11bdyMIA m53 : 17|1@1+ (1,0) [0|1] ""  gtw
 SG_ APP_sw263_eacStatusNotOk m263 : 17|1@1+ (1,0) [0|1] ""  gtw
 SG_ APP_sw033_chNm m33 : 17|1@1+ (1,0) [0|1] ""  gtw
 SG_ APP_sw164_detectedColorFilter m164 : 17|2@1+ (1,0) [0|3] ""  gtw
 SG_ APP_sw158_vehicleStatus m158 : 17|1@1+ (1,0) [0|1] ""  gtw
 SG_ APP_sw282_bufferError m282 : 17|1@1+ (1,0) [0|1] ""  gtw
 SG_ APP_sw275_bufferError m275 : 17|1@1+ (1,0) [0|1] ""  gtw
 SG_ APP_sw273_collisionType m273 : 17|3@1+ (1,0) [0|4] ""  gtw
 SG_ APP_sw186_bufferError m186 : 17|1@1+ (1,0) [0|1] ""  gtw
 SG_ APP_sw163_detectedColorFilter m163 : 17|2@1+ (1,0) [0|3] ""  gtw
 SG_ APP_sw051_a02flashPerformance m51 : 17|1@1+ (1,0) [0|1] ""  gtw
 SG_ APP_sw017_Camera_Msg_Objects_MIA m17 : 17|1@1+ (1,0) [0|1] ""  gtw
 SG_ APP_sw152_status m152 : 17|1@1+ (1,0) [0|1] ""  gtw
 SG_ APP_sw080_dist_travelled_check m80 : 17|1@1+ (1,0) [0|1] ""  gtw
 SG_ APP_sw270_rPillarStreamExit m270 : 17|1@1+ (1,0) [0|1] ""  gtw
 SG_ APP_sw274_bufferError m274 : 17|1@1+ (1,0) [0|1] ""  gtw
 SG_ APP_sw259_do_accel_pedal m259 : 17|1@1+ (1,0) [0|1] ""  gtw
 SG_ APP_sw165_detectedColorFilter m165 : 17|2@1+ (1,0) [0|3] ""  gtw
 SG_ APP_sw016_targetDist m16 : 16|9@1+ (0.2,0) [0|102.2] "m"  gtw
 SG_ APP_sw021_tempSensorId m21 : 16|8@1+ (1,0) [0|255] ""  gtw
 SG_ APP_sw054_Autofix_cnvrgnceStatus m54 : 16|8@1+ (1,0) [0|255] ""  gtw
 SG_ APP_sw162_colorFilterMismatch m162 : 16|1@1+ (1,0) [0|1] ""  gtw
 SG_ APP_sw189_exitStatus m189 : 16|1@1+ (1,0) [0|1] ""  gtw
 SG_ APP_sw190_exitStatus m190 : 16|1@1+ (1,0) [0|1] ""  gtw
 SG_ APP_sw040_accel_pedal_pos m40 : 16|8@1+ (0.5,0) [0|127.5] "%"  gtw
 SG_ APP_sw207_appMobileyeStatus m207 : 16|8@1+ (1,0) [0|255] ""  gtw
 SG_ APP_sw029_tx_buffer_full m29 : 16|1@1+ (1,0) [0|1] ""  gtw
 SG_ APP_sw154_restraintStatus m154 : 16|1@1+ (1,0) [0|1] ""  gtw
 SG_ APP_sw231_timeToImpact m231 : 16|9@1+ (1,0) [0|511] "ms"  gtw
 SG_ APP_sw028_rx_buffer_full m28 : 16|1@1+ (1,0) [0|1] ""  gtw
 SG_ APP_sw152_motorLimits m152 : 16|1@1+ (1,0) [0|1] ""  gtw
 SG_ APP_sw061_states m61 : 16|1@1+ (1,0) [0|1] ""  gtw
 SG_ APP_sw052_a07sensorBlinded m52 : 16|1@1+ (1,0) [0|1] ""  gtw
 SG_ APP_sw030_heaterState m30 : 16|8@1+ (1,0) [0|255] ""  gtw
 SG_ APP_sw082_L_VL m82 : 16|8@1+ (0.05,-6.4) [-6.4|6.35] "m"  gtw
 SG_ APP_sw220_controlledAccess m220 : 16|1@1+ (1,0) [0|1] ""  gtw
 SG_ APP_sw230_sensor1Blocked m230 : 16|1@1+ (1,0) [0|1] ""  gtw
 SG_ APP_sw168_colorFilterMismatch m168 : 16|1@1+ (1,0) [0|1] ""  gtw
 SG_ APP_sw178_lPillarCamExtPitchCal m178 : 16|9@1- (0.05,0.0) [-12.5|12.5] "deg"  gtw
 SG_ APP_sw280_exitStatus m280 : 16|1@1+ (1,0) [0|1] ""  gtw
 SG_ APP_sw172_fisheyeCamExtNoCalFile m172 : 16|1@1+ (1,0) [0|1] ""  gtw
 SG_ APP_sw044_countLSB m44 : 16|8@1+ (1,0) [0|255] ""  gtw
 SG_ APP_sw139_rRepeatCamDeserFault m139 : 16|3@1+ (1,0) [0|4] ""  gtw
 SG_ APP_sw183_exitStatus m183 : 16|1@1+ (1,0) [0|1] ""  gtw
 SG_ APP_sw080_sensors_healty_check m80 : 16|1@1+ (1,0) [0|1] ""  gtw
 SG_ APP_sw156_status m156 : 16|1@1+ (1,0) [0|1] ""  gtw
 SG_ APP_sw203_controlType m203 : 16|4@1+ (1,0) [0|15] ""  gtw
 SG_ APP_sw277_exitStatus m277 : 16|1@1+ (1,0) [0|1] ""  gtw
 SG_ APP_sw014_fileNameHash m14 : 16|16@1+ (1,0) [0|65535] ""  gtw
 SG_ APP_sw060_targetDist m60 : 16|9@1+ (0.2,0) [0|102.2] "m"  gtw
 SG_ APP_sw146_telemProblemType m146 : 16|3@1+ (1,0) [0|1] ""  gtw
 SG_ APP_sw160_doorStatus m160 : 16|1@1+ (1,0) [0|1] ""  gtw
 SG_ APP_sw155_restraintStatus m155 : 16|1@1+ (1,0) [0|1] ""  gtw
 SG_ APP_sw137_rPillarCamDeserFault m137 : 16|3@1+ (1,0) [0|4] ""  gtw
 SG_ APP_sw218_cipvDist m218 : 16|8@1+ (0.2,0) [0|51] "m"  gtw
 SG_ APP_sw274_exitStatus m274 : 16|1@1+ (1,0) [0|1] ""  gtw
 SG_ APP_sw258_target_dx m258 : 16|8@1+ (0.5,0) [0|127.5] "m"  gtw
 SG_ APP_sw213_autopilotIntState m213 : 16|4@1+ (1,0) [0|15] ""  gtw
 SG_ APP_sw163_colorFilterMismatch m163 : 16|1@1+ (1,0) [0|1] ""  gtw
 SG_ APP_sw055_detectedRadcVersion m55 : 16|32@1+ (1,0) [0|4294967295] ""  gtw
 SG_ APP_sw019_taskId m19 : 16|8@1+ (1,0) [0|255] ""  gtw
 SG_ APP_sw150_locStatus m150 : 16|1@1+ (1,0) [0|1] ""  gtw
 SG_ APP_sw006_RadarLowVisibility m6 : 16|1@1+ (1,0) [0|1] ""  gtw
 SG_ APP_sw043_mobileye_status m43 : 16|16@1+ (1,0) [0|65535] ""  gtw
 SG_ APP_sw073_escalateLDWs m73 : 16|1@1+ (1,0) [0|1] ""  gtw
 SG_ APP_sw009_DIaebState_fault m9 : 16|1@1+ (1,0) [0|1] ""  gtw
 SG_ APP_sw077_oocDistance m77 : 16|9@1+ (1,0) [0|512] "cm"  gtw
 SG_ APP_sw185_exitStatus m185 : 16|1@1+ (1,0) [0|1] ""  gtw
 SG_ APP_sw191_abortReason m191 : 16|6@1+ (1,0) [0|63] ""  gtw
 SG_ APP_sw005_AutofixOutOfCalib m5 : 16|1@1+ (1,0) [0|1] ""  gtw
 SG_ APP_sw169_colorFilterMismatch m169 : 16|1@1+ (1,0) [0|1] ""  gtw
 SG_ APP_sw075_scMia m75 : 16|8@1+ (1,0) [0|255] ""  gtw
 SG_ APP_sw067_sccmSTW m67 : 16|14@1+ (0.1,-819.2) [-819.2|819] "deg"  gtw
 SG_ APP_sw141_maxThreshold m141 : 16|8@1- (1,0) [-128|127] "degC"  gtw
 SG_ APP_sw078_camCipv_dx m78 : 16|8@1+ (0.2,0) [0|51] "m"  gtw
 SG_ APP_sw038_RadarMisalignment m38 : 16|1@1+ (1,0) [0|1] ""  gtw
 SG_ APP_sw200_autopilotIntState m200 : 16|4@1+ (1,0) [0|15] ""  gtw
 SG_ APP_sw175_lRepeatCamExtNoCalFile m175 : 16|1@1+ (1,0) [0|1] ""  gtw
 SG_ APP_sw170_colorFilterMismatch m170 : 16|1@1+ (1,0) [0|1] ""  gtw
 SG_ APP_sw064_sysStatus m64 : 16|1@1+ (1,0) [0|1] ""  gtw
 SG_ APP_sw270_lPillarStreamExit m270 : 16|1@1+ (1,0) [0|1] ""  gtw
 SG_ APP_sw057_csaOfframpCurvature m57 : 16|1@1+ (1,0) [0|1] ""  gtw
 SG_ APP_sw263_torsionThreshold m263 : 16|1@1+ (1,0) [0|1] ""  gtw
 SG_ APP_sw164_colorFilterMismatch m164 : 16|1@1+ (1,0) [0|1] ""  gtw
 SG_ APP_sw070_currTireFitment m70 : 16|3@1+ (1,0) [0|7] ""  gtw
 SG_ APP_sw004_radIssue m4 : 16|1@1+ (1,0) [0|1] ""  gtw
 SG_ APP_sw271_abortReason m271 : 16|5@1+ (1,0) [0|21] ""  gtw
 SG_ APP_sw145_pitchSpike m145 : 16|1@1+ (1,0) [0|1] ""  gtw
 SG_ APP_sw076_targetDist m76 : 16|9@1+ (0.2,0) [0|102.2] "m"  gtw
 SG_ APP_sw135_fisheyeCamDeserFault m135 : 16|3@1+ (1,0) [0|4] ""  gtw
 SG_ APP_sw130_narrowCamExtNoCalFile m130 : 16|1@1+ (1,0) [0|1] ""  gtw
 SG_ APP_sw133_mainCamDeserFault m133 : 16|3@1+ (1,0) [0|4] ""  gtw
 SG_ APP_sw015_RadarLowVisibility m15 : 16|2@1+ (1,0) [0|3] ""  gtw
 SG_ APP_sw177_fisheyeCamExtPitchCal m177 : 16|9@1- (0.05,0.0) [-12.5|12.5] "deg"  gtw
 SG_ APP_sw074_ipsoDx m74 : 16|6@1+ (2,0) [0|126] "m"  gtw
 SG_ APP_sw202_s1Blocked m202 : 16|1@1+ (1,0) [0|1] ""  gtw
 SG_ APP_sw071_selfParkType m71 : 16|4@1+ (1,0) [0|15] ""  gtw
 SG_ APP_sw227_sensorSide m227 : 16|1@1+ (1,0) [0|1] ""  gtw
 SG_ APP_sw062_HorizontalMisalignment m62 : 16|16@1+ (0.00137332,-45) [-45|45.0005262] "deg"  gtw
 SG_ APP_sw085_radarDistance m85 : 16|8@1+ (0.0625,0) [0|15.9375] "m"  gtw
 SG_ APP_sw084_ipsoTTC m84 : 16|8@1+ (0.02,0) [0|5.11] "seconds"  gtw
 SG_ APP_sw136_lPillarCamDeserFault m136 : 16|3@1+ (1,0) [0|4] ""  gtw
 SG_ APP_sw053_a10canBusOff m53 : 16|1@1+ (1,0) [0|1] ""  gtw
 SG_ APP_sw259_do_turn_indicator m259 : 16|1@1+ (1,0) [0|1] ""  gtw
 SG_ APP_sw278_exitStatus m278 : 16|1@1+ (1,0) [0|1] ""  gtw
 SG_ APP_sw063_expectedMajorVer m63 : 16|8@1+ (1,0) [0|255] ""  gtw
 SG_ APP_sw051_a01ecuInternalPerf m51 : 16|1@1+ (1,0) [0|1] ""  gtw
 SG_ APP_sw106_torsionBarOffset m106 : 16|8@1+ (0.005,-0.64) [-0.64|0.635] "Nm"  gtw
 SG_ APP_sw149_diskUsageVar m149 : 16|8@1+ (1,0) [0|255] "percent"  gtw
 SG_ APP_sw192_speakerFailureType m192 : 16|2@1+ (1,0) [0|3] ""  gtw
 SG_ APP_sw066_app_mobileye_status m66 : 16|8@1+ (1,0) [0|255] ""  gtw
 SG_ APP_sw138_lRepeatCamDeserFault m138 : 16|3@1+ (1,0) [0|4] ""  gtw
 SG_ APP_sw132_narrowCamExtPitchCal m132 : 16|9@1- (0.05,0.0) [-12.5|12.5] "deg"  gtw
 SG_ APP_sw157_leftStalk m157 : 16|1@1+ (1,0) [0|1] ""  gtw
 SG_ APP_sw194_leadAx m194 : 16|6@1- (0.2,0.0) [-6|6] "m/s^2"  gtw
 SG_ APP_sw272_unavailableReason m272 : 16|4@1+ (1,0) [0|9] ""  gtw
 SG_ APP_sw266_lPillarStreamStatus m266 : 16|3@1+ (1,0) [0|7] ""  gtw
 SG_ APP_sw275_exitStatus m275 : 16|1@1+ (1,0) [0|1] ""  gtw
 SG_ APP_sw018_minThreshold m18 : 16|13@1+ (1,0) [0|4500] "mV"  gtw
 SG_ APP_sw219_controlledAccess m219 : 16|1@1+ (1,0) [0|1] ""  gtw
 SG_ APP_sw034_sccmMia m34 : 16|8@1+ (1,0) [0|255] ""  gtw
 SG_ APP_sw010_a04calibNotDone m10 : 16|1@1+ (1,0) [0|1] ""  gtw
 SG_ APP_sw282_exitStatus m282 : 16|1@1+ (1,0) [0|1] ""  gtw
 SG_ APP_sw047_edrStatus m47 : 16|4@1+ (1,0) [0|15] ""  gtw
 SG_ APP_sw140_backupCamCSIBridgeFlt m140 : 16|3@1+ (1,0) [0|4] ""  gtw
 SG_ APP_sw173_lPillarCamExtNoCalFile m173 : 16|1@1+ (1,0) [0|1] ""  gtw
 SG_ APP_sw180_lRepeatCamExtPitchCal m180 : 16|9@1- (0.05,0.0) [-12.5|12.5] "deg"  gtw
 SG_ APP_sw165_colorFilterMismatch m165 : 16|1@1+ (1,0) [0|1] ""  gtw
 SG_ APP_sw056_diMia m56 : 16|8@1+ (1,0) [0|255] ""  gtw
 SG_ APP_sw171_APP_parkerATemp m171 : 16|8@1+ (1,-128) [-128|127] "C"  gtw
 SG_ APP_sw181_rRepeatCamExtPitchCal m181 : 16|9@1- (0.05,0.0) [-12.5|12.5] "deg"  gtw
 SG_ APP_sw026_task_id m26 : 16|2@1+ (1,0) [0|3] ""  gtw
 SG_ APP_sw186_exitStatus m186 : 16|1@1+ (1,0) [0|1] ""  gtw
 SG_ APP_sw103_objectDx m103 : 16|8@1+ (0.5,0) [0|127.5] "m"  gtw
 SG_ APP_sw083_Targ5_RCS m83 : 16|16@1+ (0.0039063096,0) [0|256] "dB"  gtw
 SG_ APP_sw068_percentConsistency m68 : 16|10@1+ (0.1,0) [0|100] "%"  gtw
 SG_ APP_sw081_radarDistance m81 : 16|8@1+ (0.0625,0) [0|15.9375] "m"  gtw
 SG_ APP_sw011_scaState m11 : 16|3@1+ (1,0) [0|7] ""  gtw
 SG_ APP_sw050_targetDist m50 : 16|9@1+ (0.2,0) [0|102.2] "m"  gtw
 SG_ APP_sw153_inertial1 m153 : 16|1@1+ (1,0) [0|1] ""  gtw
 SG_ APP_sw158_lvPowerState m158 : 16|1@1+ (1,0) [0|1] ""  gtw
 SG_ APP_sw260_target_dx m260 : 16|8@1+ (0.5,0) [0|127.5] "m"  gtw
 SG_ APP_sw001_APP_alertDataW0 m1 : 16|16@1+ (1,0) [0|65535] ""  gtw
 SG_ APP_sw193_blurredImage m193 : 16|1@1+ (1,0) [0|1] ""  gtw
 SG_ APP_sw131_mainCamExtPitchCal m131 : 16|9@1- (0.05,0.0) [-12.5|12.5] "deg"  gtw
 SG_ APP_sw148_unusedW0 m148 : 16|16@1+ (1,0) [0|65535] ""  gtw
 SG_ APP_sw264_faultReason m264 : 16|3@1+ (1,0) [0|7] ""  gtw
 SG_ APP_sw129_mainCamExtNoCalFile m129 : 16|1@1+ (1,0) [0|1] ""  gtw
 SG_ APP_sw174_rPillarCamExtNoCalFile m174 : 16|1@1+ (1,0) [0|1] ""  gtw
 SG_ APP_sw188_exitStatus m188 : 16|1@1+ (1,0) [0|1] ""  gtw
 SG_ APP_sw025_state_before_override m25 : 16|4@1+ (1,0) [0|15] ""  gtw
 SG_ APP_sw144_fanctrldErrorType m144 : 16|8@1+ (1,0) [0|14] ""  gtw
 SG_ APP_sw268_backupCamExtNoCalFile m268 : 16|1@1+ (1,0) [0|1] ""  gtw
 SG_ APP_sw037_camera m37 : 16|8@1+ (1,0) [0|255] ""  gtw
 SG_ APP_sw072_vehicleX m72 : 16|10@1+ (0.05,-25.6) [-25.6|25.5] "m"  gtw
 SG_ APP_sw022_operation m22 : 16|4@1+ (1,0) [0|15] ""  gtw
 SG_ APP_sw069_epasMia m69 : 16|1@1+ (1,0) [0|1] ""  gtw
 SG_ APP_sw049_boot_version_msw m49 : 16|16@1+ (1,0) [0|65535] ""  gtw
 SG_ APP_sw161_frameTimeout m161 : 16|1@1+ (1,0) [0|1] ""  gtw
 SG_ APP_sw201_virtualLaneInputOAL m201 : 16|3@1+ (1,0) [0|7] ""  gtw
 SG_ APP_sw166_colorFilterMismatch m166 : 16|1@1+ (1,0) [0|1] ""  gtw
 SG_ APP_sw199_abortCodeDAS m199 : 16|5@1+ (1,0) [0|24] ""  gtw
 SG_ APP_sw151_sysStatus m151 : 16|1@1+ (1,0) [0|1] ""  gtw
 SG_ APP_sw279_exitStatus m279 : 16|1@1+ (1,0) [0|1] ""  gtw
 SG_ APP_sw045_radcAlertMatrix m45 : 16|1@1+ (1,0) [0|1] ""  gtw
 SG_ APP_sw205_oocDistance m205 : 16|8@1+ (1,0) [0|255] "cm"  gtw
 SG_ APP_sw182_exitStatus m182 : 16|1@1+ (1,0) [0|1] ""  gtw
 SG_ APP_sw276_exitStatus m276 : 16|1@1+ (1,0) [0|1] ""  gtw
 SG_ APP_sw159_doorStatus m159 : 16|1@1+ (1,0) [0|1] ""  gtw
 SG_ APP_sw265_mpHasRoute m265 : 16|1@1+ (1,0) [0|1] ""  gtw
 SG_ APP_sw195_s1Blocked m195 : 16|1@1+ (1,0) [0|1] ""  gtw
 SG_ APP_sw027_JTAG_Reset m27 : 16|1@1+ (1,0) [0|1] ""  gtw
 SG_ APP_sw041_rate m41 : 16|10@1- (1,0) [-512|511] "deg/s"  gtw
 SG_ APP_sw036_bdyMia m36 : 16|8@1+ (1,0) [0|255] ""  gtw
 SG_ APP_sw281_exitStatus m281 : 16|1@1+ (1,0) [0|1] ""  gtw
 SG_ APP_sw058_epbMia m58 : 16|8@1+ (1,0) [0|255] ""  gtw
 SG_ APP_sw065_app_mobileye_status m65 : 16|8@1+ (1,0) [0|255] ""  gtw
 SG_ APP_sw059_oloDict m59 : 16|1@1+ (1,0) [0|1] ""  gtw
 SG_ APP_sw048_swAssert m48 : 16|1@1+ (1,0) [0|1] ""  gtw
 SG_ APP_sw031_canBus m31 : 16|4@1+ (1,0) [0|7] ""  gtw
 SG_ APP_sw033_carConfig m33 : 16|1@1+ (1,0) [0|1] ""  gtw
 SG_ APP_sw147_selfieCamDeserFault m147 : 16|3@1+ (1,0) [0|4] ""  gtw
 SG_ APP_sw042_health_state m42 : 16|3@1+ (1,0) [0|7] ""  gtw
 SG_ APP_sw187_exitStatus m187 : 16|1@1+ (1,0) [0|1] ""  gtw
 SG_ APP_sw046_recordId m46 : 16|16@1+ (1,0) [0|65535] ""  gtw
 SG_ APP_sw269_mainStreamExit m269 : 16|1@1+ (1,0) [0|1] ""  gtw
 SG_ APP_sw035_status m35 : 16|1@1+ (1,0) [0|1] ""  gtw
 SG_ APP_sw176_rRepeatCamExtNoCalFile m176 : 16|1@1+ (1,0) [0|1] ""  gtw
 SG_ APP_sw086_distanceException m86 : 16|8@1+ (1,90) [90|165] "m"  gtw
 SG_ APP_sw143_timeToImpact m143 : 16|9@1+ (1,0) [0|511] "ms"  gtw
 SG_ APP_sw273_eventType m273 : 16|1@1+ (1,0) [0|1] ""  gtw
 SG_ APP_sw257_target_dx m257 : 16|8@1+ (0.5,0) [0|127.5] "m"  gtw
 SG_ APP_sw261_correctableErrors m261 : 16|8@1+ (1,0) [0|255] ""  gtw
 SG_ APP_sw204_frLeft m204 : 16|8@1+ (1,0) [0|255] "cm"  gtw
 SG_ APP_sw198_fullBlockage m198 : 16|1@1+ (1,0) [0|1] ""  gtw
 SG_ APP_sw142_camExtPitchCal m142 : 16|9@1+ (0.05,-12.5) [-12.5|12.5] "deg"  gtw
 SG_ APP_sw013_stateBeforeWatchdog m13 : 16|5@1+ (1,0) [0|31] ""  gtw
 SG_ APP_sw032_canBus m32 : 16|4@1+ (1,0) [0|15] ""  gtw
 SG_ APP_sw017_Camera_Msg_Lanes_MIA m17 : 16|1@1+ (1,0) [0|1] ""  gtw
 SG_ APP_sw024_Task_ID m24 : 16|4@1+ (1,0) [0|15] ""  gtw
 SG_ APP_sw134_narrowCamDeserFault m134 : 16|3@1+ (1,0) [0|4] ""  gtw
 SG_ APP_sw167_colorFilterMismatch m167 : 16|1@1+ (1,0) [0|1] ""  gtw
 SG_ APP_sw020_unusedW0 m20 : 16|16@1+ (1,0) [0|65535] ""  gtw
 SG_ APP_sw179_rPillarCamExtPitchCal m179 : 16|9@1- (0.05,0.0) [-12.5|12.5] "deg"  gtw
 SG_ APP_sw012_bootTestResults m12 : 16|16@1+ (1,0) [0|65535] ""  gtw
 SG_ APP_sw039_sdm_rcm_Mia m39 : 16|8@1+ (1,0) [0|255] ""  gtw
 SG_ APP_sw184_exitStatus m184 : 16|1@1+ (1,0) [0|1] ""  gtw
 SG_ APP_alertState : 15|1@1+ (1,0) [0|1] ""  gtw
 SG_ APP_alertID M : 0|15@1+ (1,0) [0|282] ""  gtw

BO_ 792 GTW_carState: 8 CH
 SG_ GTW_carStateChecksum : 56|8@1+ (1,0) [0|255] ""  aps
 SG_ GTW_carStateCounter : 49|4@1+ (1,0) [0|15] ""  aps
 SG_ GTW_factoryGated : 48|1@1+ (1,0) [0|1] ""  aps
 SG_ GTW_tsMinute : 40|6@1+ (1,0) [0|59] "minutes"  rcm
 SG_ GTW_tsDay : 32|5@1+ (1,0) [0|31] "days"  rcm
 SG_ GTW_tsHour : 24|5@1+ (1,0) [0|23] "hours"  rcm
 SG_ GTW_tsSecond : 16|6@1+ (1,0) [0|59] "seconds"  rcm
 SG_ GTW_tsMonth : 8|4@1+ (1,0) [1|12] "months"  rcm
 SG_ GTW_tsYear : 0|7@1+ (1,2000) [2000|2127] "Year"  rcm

BO_ 1614 UDS_parkRequest: 8 CH
 SG_ UDS_parkRequestData : 7|64@0+ (1,0) [0|18446744073709551615] ""  park

BA_DEF_ SG_  "SystemSignalLongSymbol" STRING ;
BA_DEF_DEF_  "SystemSignalLongSymbol" "";
VAL_ 536 UI_splineLocConfidence 0 "SNA" ;
VAL_ 536 UI_rampType 1 "ENTRANCE" 4 "INTERCHANGE_EXIT" 2 "EXIT" 0 "NONE_SNA" 3 "INTERCHANGE_ENTRANCE" ;
VAL_ 536 UI_meanFleetSplineAccelMPS2 255 "SNA" ;
VAL_ 536 UI_topQrtlFleetSpeedMPS 255 "SNA" ;
VAL_ 536 UI_stopSignStopLineConf 0 "SNA" ;
VAL_ 536 UI_trafficLightStopLineConf 0 "SNA" ;
VAL_ 536 UI_medianFleetSpeedMPS 255 "SNA" ;
VAL_ 536 UI_bottomQrtlFleetSpeedMPS 255 "SNA" ;
VAL_ 536 UI_currSplineIdFull 0 "SNA" ;
VAL_ 536 UI_meanFleetSplineSpeedMPS 255 "SNA" ;
VAL_ 536 UI_trafficLightStopLineDist 1023 "SNA" ;
VAL_ 536 UI_stopSignStopLineDist 1023 "SNA" ;
VAL_ 536 UI_baseMapSpeedLimitMPS 255 "SNA" ;
VAL_ 536 UI_roadSign 255 "ROAD_SIGN_SNA" 5 "ROAD_SIGN_SPLINE_ID_FULL" 4 "ROAD_SIGN_SPEED_SPLINE" 1 "ROAD_SIGN_STOP_SIGN" 2 "ROAD_SIGN_TRAFFIC_LIGHT" 3 "ROAD_SIGN_SPEED_LIMIT" 0 "ROAD_SIGN_NONE" ;
VAL_ 622 PARK_obj_type 2 "OLO_STRAIGHT_O_CORNER" 1 "OLO_POINT" 4 "OLO_STRAIGHT_2_CORNER" 0 "OLO_NO_OBJECT" 3 "OLO_STRAIGHT_1_CORNER" ;
VAL_ 969 APS_apbGpioState 0 "AP_GPIO_STATE_PWR_DOWN_REBOOT" 3 "AP_GPIO_STATE_HEALTHY" 1 "AP_GPIO_STATE_DISABLED" 2 "AP_GPIO_STATE_CRITICAL" ;
VAL_ 969 APS_apbStatusMonitorState 1 "STATUS_MONITOR_STATE_PWR_OFF" 2 "STATUS_MONITOR_STATE_INIT" 7 "STATUS_MONITOR_NUM_STATES" 0 "STATUS_MONITOR_STATE_UNKNOWN" 4 "STATUS_MONITOR_STATE_CRITICAL" 6 "STATUS_MONITOR_STATE_RECOVERY" 5 "STATUS_MONITOR_STATE_SHUTTING_DOWN" 3 "STATUS_MONITOR_STATE_NOMINAL" ;
VAL_ 969 APS_eacInternalState 1 "APS_EAC_STATE_MOMENTARY" 3 "APS_EAC_STATE_AUTOPARK" 5 "APS_EAC_STATE_OVERRIDE" 4 "APS_EAC_STATE_INHIBIT" 0 "APS_EAC_STATE_INIT" 2 "APS_EAC_STATE_CONTINUOUS" 7 "APS_EAC_NUM_STATES" 6 "APS_EAC_STATE_LSS" ;
VAL_ 969 APS_appGpioState 0 "AP_GPIO_STATE_PWR_DOWN_REBOOT" 3 "AP_GPIO_STATE_HEALTHY" 1 "AP_GPIO_STATE_DISABLED" 2 "AP_GPIO_STATE_CRITICAL" ;
VAL_ 969 APS_canMaster 0 "CAN_MASTER_APS" 2 "CAN_MASTER_APB" 3 "CAN_MASTER_SNA" 1 "CAN_MASTER_APP" ;
VAL_ 969 APS_vehBehaviorState 0 "VEH_BEHAVIOR_STATE_UNKNOWN" 3 "VEH_BEHAVIOR_STATE_APS_BRIDGE_APP" 1 "VEH_BEHAVIOR_STATE_APS_AVAILABLE" 5 "VEH_BEHAVIOR_STATE_APS_FAIL_SAFE" 7 "VEH_BEHAVIOR_NUM_STATES" 2 "VEH_BEHAVIOR_STATE_APS_CONTROL" 6 "VEH_BEHAVIOR_STATE_APS_OVERRIDE" 4 "VEH_BEHAVIOR_STATE_APS_BRIDGE_APB" ;
VAL_ 969 APS_appStatusMonitorState 1 "STATUS_MONITOR_STATE_PWR_OFF" 2 "STATUS_MONITOR_STATE_INIT" 7 "STATUS_MONITOR_NUM_STATES" 0 "STATUS_MONITOR_STATE_UNKNOWN" 4 "STATUS_MONITOR_STATE_CRITICAL" 6 "STATUS_MONITOR_STATE_RECOVERY" 5 "STATUS_MONITOR_STATE_SHUTTING_DOWN" 3 "STATUS_MONITOR_STATE_NOMINAL" ;
VAL_ 1469 IBST_alertState 0 "ALERT_CLEARED" 1 "ALERT_SET" ;
VAL_ 1469 IBST_alertID 106 "IBST_a106_LiPS5VSupply" 39 "IBST_a039_GTMRefFrequencyError" 144 "IBST_a144_ESPparty3Timeout" 152 "IBST_a152_PSCVoltageImplausible" 132 "IBST_a132_DTSPlausiCheck1vs2" 85 "IBST_a085_supplyUndervoltageLvl3" 5 "IBST_a005_microSafetyFault" 100 "IBST_a100_current2OffsetHigh" 33 "IBST_a033_ecuWdStartuptestFault" 2 "IBST_a002_HWBISTError" 121 "IBST_a121_RPSVectorRangeLow" 41 "IBST_a041_micAsicClkInError" 166 "IBST_a166_ESPpMcVirtualInvalid" 153 "IBST_a153_PSCImpedanceTooHigh" 84 "IBST_a084_CANTransceiverHWFault" 83 "IBST_a083_spindlePositionTooHigh" 27 "IBST_a027_ecuFastWdTestFault" 174 "IBST_a174_LVOffStateInvalid" 69 "IBST_a069_greasingRoutineFault" 149 "IBST_a149_MLITMCAreaReadFault" 54 "IBST_a054_AdcPeripheralFault" 122 "IBST_a122_RPSVectorOscillating" 81 "IBST_a081_travelDeviation" 65 "IBST_a065_tempSens2ShortToGround" 22 "IBST_a022_U5VTestFault" 101 "IBST_a101_current2OffsetLow" 45 "IBST_a045_WdhAsicWdErrorCntStuck" 15 "IBST_a015_asicOscillatorError" 175 "IBST_a175_LVGoingDownInvalid" 112 "IBST_a112_LiPS1SentTransmission" 157 "IBST_a157_masterCylPressInvalid" 170 "IBST_a170_LVPowerStateTimeout" 168 "IBST_a168_CANOvervoltage" 9 "IBST_a009_systemErrorHook" 3 "IBST_a003_RAMFault" 88 "IBST_a088_rotorCosOutOfRangeLow" 0 "IBST_ALERT_DO_NOT_USE_ZERO" 133 "IBST_a133_DTSOffsetTooLow" 155 "IBST_a155_supplyUndervoltageLvl1" 91 "IBST_a091_SMMOneRequestsInit" 25 "IBST_a025_ecuClockTestFault" 125 "IBST_a125_OBDCurrent2OORHigh" 102 "IBST_a102_current1OffsetHigh" 31 "IBST_a031_decoupleBitTestFault" 72 "IBST_a072_notShutDownRight" 111 "IBST_a111_LiPS1SentLineLow" 107 "IBST_a107_LiPS2PwmLineHigh" 127 "IBST_a127_OBDCurrent2OORLow" 1 "IBST_a001_microSupplyError" 55 "IBST_a055_UB6SupplyPathFault" 92 "IBST_a092_systemStartTimeOut" 163 "IBST_a163_ESPpEstMaxInvalid" 47 "IBST_a047_WdhAsicWdCmdMissing" 82 "IBST_a082_motorSpeedDeviation" 130 "IBST_a130_DTSFunctionalRangeLow" 108 "IBST_a108_LiPS2PwmLineLow" 60 "IBST_a060_NvMMigrationFault" 78 "IBST_a078_wearOffsetCompNVMRead" 172 "IBST_a172_LVPowerStateDLC" 162 "IBST_a162_idlePosNotDetected" 4 "IBST_a004_flashFault" 46 "IBST_a046_WdhAsicWdErrorCntLimit" 17 "IBST_a017_assertionFault" 68 "IBST_a068_chargePumpUndervoltage" 13 "IBST_a013_systemTaskJitter" 7 "IBST_a007_RBCPUException" 95 "IBST_a095_XPASSTimeOut" 136 "IBST_a136_ESPparty1Timeout" 145 "IBST_a145_ESPparty3Checksum" 24 "IBST_a024_chargePumpFault" 143 "IBST_a143_ESPparty3DLC" 10 "IBST_a010_OSErrorHook" 14 "IBST_a014_DMATransferError" 173 "IBST_a173_LVPowerStateCounter" 93 "IBST_a093_UEXSOvertemperature" 19 "IBST_a019_supplyASICInitFault" 141 "IBST_a141_ESPparty2Checksum" 44 "IBST_a044_NvMEepromWIP" 94 "IBST_a094_XPASSEchoTimeDeviation" 164 "IBST_a164_ESPVehicleSpeedInvalid" 103 "IBST_a103_current1OffsetLow" 110 "IBST_a110_LiPS1SentLineHigh" 67 "IBST_a067_tempSensImplausVoltage" 36 "IBST_a036_MRGPathTestFault" 6 "IBST_a006_microSafetyLogicFault" 140 "IBST_a140_ESPparty2Timeout" 16 "IBST_a016_RBBLMShaftShiftError" 59 "IBST_a059_NvMEepromSize" 128 "IBST_a128_BLMMuxerTimeoutError" 71 "IBST_a071_notShutDownNvMRead" 48 "IBST_a048_WdhSwBistConCnt" 161 "IBST_a161_powerPackMismatch" 137 "IBST_a137_ESPparty1Checksum" 142 "IBST_a142_ESPparty2Counter" 114 "IBST_a114_partyBusOff" 167 "IBST_a167_ESPqTargetExterInvalid" 165 "IBST_a165_ESPpForceBlendInvalid" 123 "IBST_a123_bridgeDriverUnavail" 43 "IBST_a043_micSpiTransferError" 77 "IBST_a077_runOutMotorSaturated" 74 "IBST_a074_FindIdleDataNvMWrite" 124 "IBST_a124_OBDCurrent1OORHigh" 70 "IBST_a070_notShutDownNvMWrite" 96 "IBST_a096_bridgeDriverMonError" 160 "IBST_a160_DTSIDTimeOut" 134 "IBST_a134_DTSOffsetTooHigh" 139 "IBST_a139_ESPparty2DLC" 126 "IBST_a126_OBDCurrent1OORLow" 156 "IBST_a156_supplyOvervoltageLvl1" 37 "IBST_a037_ecuWdSContinuousError" 63 "IBST_a063_tempSens2ShortToSupply" 120 "IBST_a120_RPSVectorRangeHigh" 176 "IBST_a176_blockedPedalDetected" 8 "IBST_a008_stackOverUnderFlow" 158 "IBST_a158_DTSOffsHighSuspicious" 98 "IBST_a098_bridgeShortedPhase" 138 "IBST_a138_ESPparty1Counter" 75 "IBST_a075_FindIdleRoutineFault" 58 "IBST_a058_NvMWriteCycleExceed" 99 "IBST_a099_bridgeSwitchInitError" 23 "IBST_a023_U5VOutOfRange" 89 "IBST_a089_rotorSinOutOfRangeHigh" 148 "IBST_a148_MLIGainMechReadFault" 97 "IBST_a097_bridgeDriverError" 12 "IBST_a012_OSTaskSchemeError" 11 "IBST_a011_systemTaskOverRun" 109 "IBST_a109_LiPS2PwmTransmission" 52 "IBST_a052_AdcPinTest" 51 "IBST_a051_ecuBandgap" 79 "IBST_a079_motorTempHighLevel1" 64 "IBST_a064_tempSens1ShortToGround" 34 "IBST_a034_ecuEnableHyHighFault" 105 "IBST_a105_LiPSUndervoltage" 171 "IBST_a171_LVPowerStateChecksum" 169 "IBST_a169_CANUndervoltage" 28 "IBST_a028_ecuBistFaultCtrFault" 40 "IBST_a040_GTMTbuMonError" 135 "IBST_a135_ESPparty1DLC" 20 "IBST_a020_VPREU5VOutOfRange" 151 "IBST_a151_PSCGearRatioReadFault" 42 "IBST_a042_micAsicInitTestError" 76 "IBST_a076_masterCylLengthRead" 26 "IBST_a026_ecuBistCmdTestFault" 80 "IBST_a080_motorTempHighLevel2" 115 "IBST_a115_chassisBusOff" 30 "IBST_a030_ecuEnableElLowFault" 38 "IBST_a038_ecuEnContinuousError" 129 "IBST_a129_loadDumpOnFSLTest" 131 "IBST_a131_DTSFunctionalRangeHigh" 113 "IBST_a113_LiPS1SentSensor" 104 "IBST_a104_bridgeDriverShort" 56 "IBST_a056_UB6PlausiMonFault" 32 "IBST_a032_ecuEnableElHighFault" 119 "IBST_a119_RPSWrongCalibData" 73 "IBST_a073_jumpInAdjustNvMRead" 57 "IBST_a057_microRegisterFault" 50 "IBST_a050_VPreExternalFeeding" 116 "IBST_a116_supplyUndervoltageLvl2" 21 "IBST_a021_IREFOutOfRange" 87 "IBST_a087_rotorSinOutOfRangeLow" 150 "IBST_a150_motorTestFault" 159 "IBST_a159_FindIdleNvMReadError" 35 "IBST_a035_ecuEnableHyLowFault" 18 "IBST_a018_unsupportedHW" 117 "IBST_a117_supplyOvervoltageLvl2" 61 "IBST_a061_AswSystemTimeOut" 53 "IBST_a053_AdcSelftestC5P" 49 "IBST_a049_WdhTaskMonConCnt" 90 "IBST_a090_rotorCosOutOfRangeHigh" 118 "IBST_a118_RPSNvMReadFault" 147 "IBST_a147_PSCMotorSizeReadFault" 154 "IBST_a154_PSCImpedanceTooLow" 29 "IBST_a029_ecuErrpinCounterFault" 86 "IBST_a086_supplyOvervoltageLvl3" 62 "IBST_a062_MICB6TransferError" 146 "IBST_a146_ESPparty3Counter" 66 "IBST_a066_tempSens1ShortToSupply" ;
VAL_ 1005 TAS_CPULoad1000msTask 255 "SNA" ;
VAL_ 1005 TAS_CPULoad100msTask 255 "SNA" ;
VAL_ 1005 TAS_CPULoad10msTask 255 "SNA" ;
VAL_ 1005 TAS_CPULoad1msTask 255 "SNA" ;
VAL_ 1005 TAS_CPULoadTotal 255 "SNA" ;
VAL_ 1033 DAS_nmKeepAwakeReason 2 "DAS_KEEPAWAKE_REASON_TELEMETRY" 1 "DAS_KEEPAWAKE_REASON_PRECONDITIONING" 0 "DAS_KEEPAWAKE_REASON_NONE_SNA" ;
VAL_ 782 PARK_sdiBlindSpotLeft 3 "SNA" 0 "NO_WARNING" 2 "UNUSED" 1 "WARNING" ;
VAL_ 782 PARK_sdiBlindSpotRight 3 "SNA" 0 "NO_WARNING" 2 "UNUSED" 1 "WARNING" ;
VAL_ 782 PARK_sdiNoise 3 "SDI_NOISE_SNA" 2 "SDI_NOISE_RAIN" 0 "SDI_NOISE_NOMINAL" 1 "SDI_NOISE_HIGH" ;
VAL_ 782 PARK_sdiActive 0 "SDI_DISABLED" 1 "SDI_ENABLED" ;
VAL_ 782 PARK_rackDetected 3 "SNA" 0 "UNKNOWN" 2 "RACK_DETECTED" 1 "NO_RACK" ;
VAL_ 782 PARK_tireFitment 3 "SNA" 2 "NOT_USED" 0 "SQUARE" 1 "STAGGERED" ;
VAL_ 782 PARK_geometryType 1 "MODELS_2" 3 "MODEL3" 0 "MODELS" 2 "MODELX" ;
VAL_ 782 PARK_autoCalComplete 0 "INCOMPLETE" 1 "COMPLETE" ;
VAL_ 782 PARK_pscLeftCurbType 2 "HIGH_CURB" 1 "LOW_CURB" 0 "VIRTUAL_CURB" ;
VAL_ 782 PARK_pscRightCurbType 2 "HIGH_CURB" 1 "LOW_CURB" 0 "VIRTUAL_CURB" ;
VAL_ 557 TAS_componentPressureRL 255 "SNA" ;
VAL_ 557 TAS_componentPressureFR 255 "SNA" ;
VAL_ 557 TAS_componentPressureFL 255 "SNA" ;
VAL_ 557 TAS_componentPressureRR 255 "SNA" ;
VAL_ 557 TAS_componentPressureIndex 3 "TAS_componentPressureRR" 0 "TAS_componentPressureFL" 1 "TAS_componentPressureFR" 2 "TAS_componentPressureRL" ;
VAL_ 557 TAS_rawHeightRR 255 "SNA" ;
VAL_ 557 TAS_rawHeightRL 255 "SNA" ;
VAL_ 557 TAS_rawHeightFR 255 "SNA" ;
VAL_ 557 TAS_rawHeightFL 255 "SNA" ;
VAL_ 806 PARK_infoBuildType 1 "INFO_PLATFORM_BUILD" 3 "INFO_TRACEABLE_CI_BUILD" 4 "INFO_MFG_BUILD" 2 "INFO_LOCAL_BUILD" 0 "INFO_UNKNOWN_BUILD" ;
VAL_ 806 PARK_infoIndex 25 "INFO_PACKAGE_PN_1_7" 30 "INFO_PACKAGE_SN_8_14" 27 "INFO_PACKAGE_PN_15_20" 0 "INFO_DEPRECATED_0" 29 "INFO_PACKAGE_SN_1_7" 10 "INFO_BUILD_HWID_COMPONENTID" 14 "INFO_BOOTLOADER_SVN" 31 "INFO_SUBCOMPONENT_GITHASH" 19 "INFO_VERSION_DEPRECATED" 7 "INFO_DEPRECATED_7" 255 "INFO_END" 9 "INFO_DEPRECATED_9" 6 "INFO_DEPRECATED_6" 20 "INFO_UDS_PROTOCOL_BOOTCRC" 3 "INFO_DEPRECATED_3" 22 "INFO_VARIANTCRC" 17 "INFO_APP_GITHASH" 8 "INFO_DEPRECATED_8" 26 "INFO_PACKAGE_PN_8_14" 5 "INFO_DEPRECATED_5" 16 "INFO_SUBCOMPONENT" 13 "INFO_APP_CRC" 2 "INFO_DEPRECATED_2" 4 "INFO_DEPRECATED_4" 15 "INFO_BOOTLOADER_CRC" 1 "INFO_DEPRECATED_1" 11 "INFO_PCBAID_ASSYID_USAGEID" 18 "INFO_BOOTLOADER_GITHASH" ;
VAL_ 830 PARK_rearDtcPresent 3 "SNA" 0 "FALSE" 1 "TRUE" 2 "UNUSED" ;
VAL_ 830 PARK_systemStatusRear 3 "SNA" 1 "ENABLED" 0 "DISABLED" 2 "UNUSED" ;
VAL_ 830 PARK_rearRightRawDistData 255 "SNA" ;
VAL_ 830 PARK_rearLeftRawDistData 255 "SNA" ;
VAL_ 830 PARK_rearLeftSensorState 3 "SNA" 2 "TEMPORARY_FAILURE" 0 "NO_FAILURE" 1 "PERMANENT_FAILURE" ;
VAL_ 830 PARK_rearLeftMiddleSensorState 3 "SNA" 2 "TEMPORARY_FAILURE" 0 "NO_FAILURE" 1 "PERMANENT_FAILURE" ;
VAL_ 830 PARK_rearRightMiddleSensorState 3 "SNA" 2 "TEMPORARY_FAILURE" 0 "NO_FAILURE" 1 "PERMANENT_FAILURE" ;
VAL_ 830 PARK_rearRightSensorState 3 "SNA" 2 "TEMPORARY_FAILURE" 0 "NO_FAILURE" 1 "PERMANENT_FAILURE" ;
VAL_ 2047 GTW_eCallEnabled 1 "ENABLED" 0 "DISABLED" ;
VAL_ 2047 GTW_trackModePackage 0 "NONE" 1 "PERFORMANCE" ;
VAL_ 2047 GTW_roofGlassType 1 "TSA5_NOPET" 0 "TSA3_PET" ;
VAL_ 2047 GTW_restraintsHardwareType 23 "M3_EUROW_NO_ECALL" 22 "M3_EUROW_ECALL" 21 "M3_NA" ;
VAL_ 2047 GTW_brakeHWType 1 "BREMBO_P42_BREMBO_44MOC" 0 "BREMBO_P42_MANDO_43MOC" ;
VAL_ 2047 GTW_pedestrianWarningSound 0 "NONE" 1 "SPEAKER" ;
VAL_ 2047 GTW_numberHVILNodes 0 "HVIL_NODES_0" 1 "HVIL_NODES_1" 4 "HVIL_NODES_4" 2 "HVIL_NODES_2" 5 "HVIL_NODES_5" 3 "HVIL_NODES_3" ;
VAL_ 2047 GTW_exteriorColor 2 "SILVER_METALLIC" 3 "MIDNIGHT_SILVER" 0 "RED_MULTICOAT" 6 "PEARL_WHITE" 1 "SOLID_BLACK" 5 "DEEP_BLUE" ;
VAL_ 2047 GTW_wheelType 2 "STILETTO_20" 1 "STILETTO_19" 0 "PINWHEEL_18" 3 "STILETTO_20_STAGGERED" ;
VAL_ 2047 GTW_superchargingAccess 2 "PAY_AS_YOU_GO" 0 "NOT_ALLOWED" 1 "ALLOWED" ;
VAL_ 2047 GTW_autopilot 0 "NONE" 3 "SELF_DRIVING" 2 "ENHANCED" 1 "HIGHWAY" ;
VAL_ 2047 GTW_dasHw 3 "PARKER_PASCAL_2_5" 4 "TESLA_AP3" ;
VAL_ 2047 GTW_roofType 0 "METAL" 2 "PANORAMIC" 1 "FIXED_GLASS" ;
VAL_ 2047 GTW_rearFogLamps 0 "NOT_INSTALLED" 1 "INSTALLED" ;
VAL_ 2047 GTW_rearGlassType 1 "TSA5_NOPET" 0 "NX" ;
VAL_ 2047 GTW_spoilerType 1 "PASSIVE" 0 "NOT_INSTALLED" ;
VAL_ 2047 GTW_intrusionSensorType 1 "VODAFONE" 0 "NOT_INSTALLED" ;
VAL_ 2047 GTW_airbagCutoffSwitch 0 "CUTOFF_SWITCH_DISABLED" 1 "CUTOFF_SWITCH_ENABLED" ;
VAL_ 2047 GTW_activeHighBeam 0 "NOT_ACTIVE" 1 "ACTIVE" ;
VAL_ 2047 GTW_windshieldType 0 "SEKISUI_ACOUSTIC" 1 "EASTMAN_ACOUSTIC" ;
VAL_ 2047 GTW_tireType 4 "CONTI_ALL_SEASON_19" 5 "MICHELIN_SUMMER_20" 0 "UNKNOWN" 1 "MICHELIN_ALL_SEASON_18" 3 "HANKOOK_SUMMER_19" 2 "MICHELIN_SUMMER_18" ;
VAL_ 2047 GTW_eBuckConfig 0 "NONE" 1 "DEV_BUCK" ;
VAL_ 2047 GTW_performancePackage 0 "BASE" 1 "PERFORMANCE" ;
VAL_ 2047 GTW_CabinBlowerCtrlType 1 "TMS320F28027F" 0 "LV8907" ;
VAL_ 2047 GTW_hvacPanelVaneType 0 "PARALLEL_V1" 1 "CONVERGENT_V1" ;
VAL_ 2047 GTW_hvacQuietSnorkelType 0 "DEFAULT" 1 "QUIET_V1" ;
VAL_ 2047 GTW_auxParkLamps 0 "NA_BASE" 2 "EU" 1 "NA_PREMIUM" ;
VAL_ 2047 GTW_frontSeatType 0 "TESLA_BASE" 1 "TESLA_PREMIUM" ;
VAL_ 2047 GTW_ibstWakeType 0 "NONE" 1 "WAKE_PIN_20" ;
VAL_ 2047 GTW_lumbarECUType 0 "NONE" 1 "ALFMEIER" ;
VAL_ 2047 GTW_audioType 0 "BASE" 1 "PREMIUM" ;
VAL_ 2047 GTW_headlamps 0 "BASE" 1 "PREMIUM" ;
VAL_ 2047 GTW_frontFogLamps 0 "NOT_INSTALLED" 1 "INSTALLED" ;
VAL_ 2047 GTW_interiorLighting 0 "BASE" 1 "PREMIUM" ;
VAL_ 2047 GTW_powerSteeringColumn 1 "TK" 0 "NOT_INSTALLED" ;
VAL_ 2047 GTW_memoryMirrors 1 "SMR" 0 "NOT_INSTALLED" ;
VAL_ 2047 GTW_rearLightType 0 "NA" 1 "EU_CN" ;
VAL_ 2047 GTW_xcpESP 0 "FALSE" 1 "TRUE" ;
VAL_ 2047 GTW_xcpIbst 0 "FALSE" 1 "TRUE" ;
VAL_ 2047 GTW_vdcType 1 "TESLA_VDC" 0 "BOSCH_VDC" ;
VAL_ 2047 GTW_homelinkType 0 "NONE" 1 "HOMELINK_V_OPT_2" ;
VAL_ 2047 GTW_rightHandDrive 0 "LEFT" 1 "RIGHT" ;
VAL_ 2047 GTW_packEnergy 0 "PACK_50_KWH" 1 "PACK_74_KWH" 2 "PACK_62_KWH" ;
VAL_ 2047 GTW_rearSeatHeaters 0 "NONE" 1 "KONGSBERG_LOW_POWER" ;
VAL_ 2047 GTW_drivetrainType 1 "AWD" 0 "RWD" ;
VAL_ 2047 GTW_epasType 0 "MANDO_VGR69_GEN3" ;
VAL_ 2047 GTW_frontSeatHeaters 0 "NONE" 1 "KONGSBERG_LOW_POWER" ;
VAL_ 2047 GTW_mapRegion 4 "AU" 2 "NONE" 5 "JP" 8 "ME" 0 "US" 7 "KR" 3 "CN" 1 "EU" 6 "TW" ;
VAL_ 2047 GTW_heatedWipers 0 "FALSE" 1 "TRUE" ;
VAL_ 2047 GTW_airSuspension 0 "NONE" 1 "TESLA_STANDARD" ;
VAL_ 81 EPAS3S_role 1 "SLAVE" 0 "MASTER" 2 "RESERVED" ;
VAL_ 81 EPAS3S_powerMode 7 "SNA" 2 "DRIVE_ON" 6 "POWERING_DOWN" 0 "DRIVE_OFF" 5 "LIMP_3" 1 "EMERGENCY_ON" 4 "LIMP_2" 3 "LIMP_1" ;
VAL_ 81 EPAS3S_state 2 "INIT_COMPLETE" 7 "EAC_ACTIVE" 4 "PASSIVE_FAULTED" 6 "ASSIST_STANDBY" 3 "PASSIVE" 0 "INIT_ARBITRATION" 15 "INVALID" 1 "INIT_PHASECUT_TEST" 5 "ASSIST_ACTIVE" 8 "EAC_STANDBY" ;
VAL_ 781 TAS_compTempModel 255 "SNA" ;
VAL_ 781 TAS_compTempSensor 255 "SNA" ;
VAL_ 521 DAS_locAccelMax 511 "SNA" ;
VAL_ 521 DAS_locAccelMin 511 "SNA" ;
VAL_ 521 DAS_locSpeed 2047 "SNA" ;
VAL_ 521 DAS_locJerkMax 255 "SNA" ;
VAL_ 521 DAS_locJerkMin 255 "SNA" ;
VAL_ 521 DAS_locRequest 1 "DAS_RQ_FORWARD" 0 "DAS_RQ_IDLE" 3 "DAS_RQ_HOLD" 4 "DAS_RQ_PARK" 2 "DAS_RQ_BACKWARD" ;
VAL_ 521 DAS_locState 0 "DAS_LOC_HEALTHY" 2 "DAS_LOC_CANCEL_SILENT" 1 "DAS_LOC_CANCEL_GENERIC" 7 "DAS_LOC_FAULT_SNA" 6 "DAS_LOC_AEB_ACTIVE" ;
VAL_ 521 DAS_locMode 1 "DAS_LOC_NORMAL" 2 "DAS_LOC_RESTRICTED" 0 "DAS_LOC_OFF" 3 "DAS_LOC_DRIVERLESS" ;
VAL_ 963 VCRIGHT_rearRightBuckleSwitch 2 "SWITCH_ON" 0 "SWITCH_SNA" 3 "SWITCH_FAULT" 1 "SWITCH_OFF" ;
VAL_ 963 VCRIGHT_rearCenterBuckleSwitch 2 "SWITCH_ON" 0 "SWITCH_SNA" 3 "SWITCH_FAULT" 1 "SWITCH_OFF" ;
VAL_ 963 VCRIGHT_frontOccupancySwitch 2 "SWITCH_ON" 0 "SWITCH_SNA" 3 "SWITCH_FAULT" 1 "SWITCH_OFF" ;
VAL_ 963 VCRIGHT_frontBuckleSwitch 2 "SWITCH_ON" 0 "SWITCH_SNA" 3 "SWITCH_FAULT" 1 "SWITCH_OFF" ;
VAL_ 963 VCRIGHT_frontSeatLumbarOut 2 "SWITCH_ON" 0 "SWITCH_SNA" 3 "SWITCH_FAULT" 1 "SWITCH_OFF" ;
VAL_ 963 VCRIGHT_frontSeatLumbarIn 2 "SWITCH_ON" 0 "SWITCH_SNA" 3 "SWITCH_FAULT" 1 "SWITCH_OFF" ;
VAL_ 963 VCRIGHT_frontSeatLumbarUp 2 "SWITCH_ON" 0 "SWITCH_SNA" 3 "SWITCH_FAULT" 1 "SWITCH_OFF" ;
VAL_ 963 VCRIGHT_frontSeatLumbarDown 2 "SWITCH_ON" 0 "SWITCH_SNA" 3 "SWITCH_FAULT" 1 "SWITCH_OFF" ;
VAL_ 963 VCRIGHT_frontSeatBackrestForward 2 "SWITCH_ON" 0 "SWITCH_SNA" 3 "SWITCH_FAULT" 1 "SWITCH_OFF" ;
VAL_ 963 VCRIGHT_frontSeatBackrestBack 2 "SWITCH_ON" 0 "SWITCH_SNA" 3 "SWITCH_FAULT" 1 "SWITCH_OFF" ;
VAL_ 963 VCRIGHT_frontSeatLiftUp 2 "SWITCH_ON" 0 "SWITCH_SNA" 3 "SWITCH_FAULT" 1 "SWITCH_OFF" ;
VAL_ 963 VCRIGHT_frontSeatLiftDown 2 "SWITCH_ON" 0 "SWITCH_SNA" 3 "SWITCH_FAULT" 1 "SWITCH_OFF" ;
VAL_ 963 VCRIGHT_frontSeatTiltUp 2 "SWITCH_ON" 0 "SWITCH_SNA" 3 "SWITCH_FAULT" 1 "SWITCH_OFF" ;
VAL_ 963 VCRIGHT_frontSeatTiltDown 2 "SWITCH_ON" 0 "SWITCH_SNA" 3 "SWITCH_FAULT" 1 "SWITCH_OFF" ;
VAL_ 963 VCRIGHT_frontSeatTrackForward 2 "SWITCH_ON" 0 "SWITCH_SNA" 3 "SWITCH_FAULT" 1 "SWITCH_OFF" ;
VAL_ 963 VCRIGHT_frontSeatTrackBack 2 "SWITCH_ON" 0 "SWITCH_SNA" 3 "SWITCH_FAULT" 1 "SWITCH_OFF" ;
VAL_ 814 PARK_frontDtcPresent 3 "SNA" 0 "FALSE" 1 "TRUE" 2 "UNUSED" ;
VAL_ 814 PARK_systemStatusFront 3 "SNA" 1 "ENABLED" 0 "DISABLED" 2 "UNUSED" ;
VAL_ 814 PARK_frontRightRawDistData 255 "SNA" ;
VAL_ 814 PARK_frontLeftRawDistData 255 "SNA" ;
VAL_ 814 PARK_frontLeftSensorState 3 "SNA" 2 "TEMPORARY_FAILURE" 0 "NO_FAILURE" 1 "PERMANENT_FAILURE" ;
VAL_ 814 PARK_frontLeftMiddleSensorState 3 "SNA" 2 "TEMPORARY_FAILURE" 0 "NO_FAILURE" 1 "PERMANENT_FAILURE" ;
VAL_ 814 PARK_frontRightMiddleSensorState 3 "SNA" 2 "TEMPORARY_FAILURE" 0 "NO_FAILURE" 1 "PERMANENT_FAILURE" ;
VAL_ 814 PARK_frontRightSensorState 3 "SNA" 2 "TEMPORARY_FAILURE" 0 "NO_FAILURE" 1 "PERMANENT_FAILURE" ;
VAL_ 1513 APP_sw257_user_sensitivity 3 "SNA" 2 "AEB_SENSITIVITY_LATE" 1 "AEB_SENSITIVITY_AVERAGE" 0 "AEB_SENSITIVITY_EARLY" ;
VAL_ 1513 APP_sw260_user_sensitivity 3 "SNA" 2 "AEB_SENSITIVITY_LATE" 1 "AEB_SENSITIVITY_AVERAGE" 0 "AEB_SENSITIVITY_EARLY" ;
VAL_ 1513 APP_sw191_cameraFailsafes 0 "NONE" 7 "MAX_CAM_FAILSAFES" ;
VAL_ 1513 APP_sw191_radarBlind 0 "FALSE" 1 "TRUE" ;
VAL_ 1513 APP_sw060_collisionWarningSource 1 "SOURCE_FCW_VEHICLE" 4 "SOURCE_BCW_CIPV" 5 "SOURCE_BCW_CIPV2" 0 "SOURCE_FCW_PEDESTRIAN" 3 "SOURCE_BCW_CUTIN" 7 "SOURCE_BCW_PEDESTRIAN" 2 "SOURCE_STOPLINE" 6 "SOURCE_BCW_MCVLR" ;
VAL_ 1513 APP_sw191_radarFault 0 "FALSE" 1 "TRUE" ;
VAL_ 1513 APP_sw191_roadEstMode 2 "ROAD_ESTIMATOR_MODE_FULL" 1 "ROAD_ESTIMATOR_MODE_VL" 0 "ROAD_ESTIMATOR_MODE_MAP" ;
VAL_ 1513 APP_sw279_maxTemperature 255 "SNA" ;
VAL_ 1513 APP_sw187_maxTemperature 255 "SNA" ;
VAL_ 1513 APP_sw184_maxTemperature 255 "SNA" ;
VAL_ 1513 APP_sw275_maxTemperature 255 "SNA" ;
VAL_ 1513 APP_sw282_maxTemperature 255 "SNA" ;
VAL_ 1513 APP_sw188_maxTemperature 255 "SNA" ;
VAL_ 1513 APP_sw185_maxTemperature 255 "SNA" ;
VAL_ 1513 APP_sw276_maxTemperature 255 "SNA" ;
VAL_ 1513 APP_sw281_maxTemperature 255 "SNA" ;
VAL_ 1513 APP_sw182_maxTemperature 255 "SNA" ;
VAL_ 1513 APP_sw278_maxTemperature 255 "SNA" ;
VAL_ 1513 APP_sw189_maxTemperature 255 "SNA" ;
VAL_ 1513 APP_sw190_maxTemperature 255 "SNA" ;
VAL_ 1513 APP_sw186_maxTemperature 255 "SNA" ;
VAL_ 1513 APP_sw280_maxTemperature 255 "SNA" ;
VAL_ 1513 APP_sw183_maxTemperature 255 "SNA" ;
VAL_ 1513 APP_sw277_maxTemperature 255 "SNA" ;
VAL_ 1513 APP_sw274_maxTemperature 255 "SNA" ;
VAL_ 1513 APP_sw191_roadEstHealth 1 "ROAD_ESTIMATOR_UNSTABLE_MEASUREMENTS" 3 "ROAD_ESTIMATOR_CRITICAL" 0 "ROAD_ESTIMATOR_HEALTHY" 2 "ROAD_ESTIMATOR_DEGRADED" ;
VAL_ 1513 APP_sw191_solverHealth 2 "SOLVER_CRITICAL" 0 "SOLVER_HEALTHY" 1 "SOLVER_DEGRADED" 3 "SOLVER_FAILURE" ;
VAL_ 1513 APP_sw191_referenceHealth 1 "REFERENCE_UNHEALTHY" 2 "REFERENCE_INDETERMINATE" 0 "REFERENCE_HEALTHY" ;
VAL_ 1513 APP_sw280_minTemperature 255 "SNA" ;
VAL_ 1513 APP_sw277_minTemperature 255 "SNA" ;
VAL_ 1513 APP_sw183_minTemperature 255 "SNA" ;
VAL_ 1513 APP_sw184_minTemperature 255 "SNA" ;
VAL_ 1513 APP_sw190_minTemperature 255 "SNA" ;
VAL_ 1513 APP_sw189_minTemperature 255 "SNA" ;
VAL_ 1513 APP_sw274_minTemperature 255 "SNA" ;
VAL_ 1513 APP_sw185_minTemperature 255 "SNA" ;
VAL_ 1513 APP_sw186_minTemperature 255 "SNA" ;
VAL_ 1513 APP_sw278_minTemperature 255 "SNA" ;
VAL_ 1513 APP_sw275_minTemperature 255 "SNA" ;
VAL_ 1513 APP_sw282_minTemperature 255 "SNA" ;
VAL_ 1513 APP_sw269_laneDepartureWarning 10 "LSS_LIMITED_CONSTRUCTION" 6 "LSS_LIMITED_MAIN_CAMERA" 0 "LSS_NOMINAL" 11 "LSS_LIMITED_WEATHER" 1 "LSS_LIMITED_LEFT_PILLAR_CAMERA" 5 "LSS_LIMITED_BACKUP_CAMERA" 8 "LSS_LIMITED_FISHEYE_CAMERA" 9 "LSS_LIMITED_TURN_INDICATOR_FAULT" 4 "LSS_LIMITED_RIGHT_REPEATER_CAMERA" 15 "LSS_LIMITED_SNA" 3 "LSS_LIMITED_LEFT_REPEATER_CAMERA" 2 "LSS_LIMITED_RIGHT_PILLAR_CAMERA" 7 "LSS_LIMITED_NARROW_CAMERA" ;
VAL_ 1513 APP_sw276_minTemperature 255 "SNA" ;
VAL_ 1513 APP_sw281_minTemperature 255 "SNA" ;
VAL_ 1513 APP_sw182_minTemperature 255 "SNA" ;
VAL_ 1513 APP_sw187_minTemperature 255 "SNA" ;
VAL_ 1513 APP_sw188_minTemperature 255 "SNA" ;
VAL_ 1513 APP_sw191_roadClass 1 "CLASS_1_MAJOR" 6 "CLASS_6_MINOR" 0 "UNKNOWN_INVALID_SNA" 5 "CLASS_5" 3 "CLASS_3" 4 "CLASS_4" 2 "CLASS_2" ;
VAL_ 1513 APP_sw279_minTemperature 255 "SNA" ;
VAL_ 1513 APP_sw269_blindspot 10 "LSS_LIMITED_CONSTRUCTION" 6 "LSS_LIMITED_MAIN_CAMERA" 0 "LSS_NOMINAL" 11 "LSS_LIMITED_WEATHER" 1 "LSS_LIMITED_LEFT_PILLAR_CAMERA" 5 "LSS_LIMITED_BACKUP_CAMERA" 8 "LSS_LIMITED_FISHEYE_CAMERA" 9 "LSS_LIMITED_TURN_INDICATOR_FAULT" 4 "LSS_LIMITED_RIGHT_REPEATER_CAMERA" 15 "LSS_LIMITED_SNA" 3 "LSS_LIMITED_LEFT_REPEATER_CAMERA" 2 "LSS_LIMITED_RIGHT_PILLAR_CAMERA" 7 "LSS_LIMITED_NARROW_CAMERA" ;
VAL_ 1513 APP_sw194_reasonForHold 15 "SNA" 9 "CAM_ONLY_CONTROL" 1 "CAM_PEDESTRIAN" 7 "DRIVER_SEATBELT" 2 "ULTRASONIC_OBSTACLE" 4 "CAM_STOP_AND_GO" 5 "STOP_SIGN" 6 "TRAFFIC_LIGHT" 3 "TARGET_LOSS" 0 "TIMEOUT" 8 "MCP_CONTROL" ;
VAL_ 1513 APP_sw274_currentTemperature 255 "SNA" ;
VAL_ 1513 APP_sw187_currentTemperature 255 "SNA" ;
VAL_ 1513 APP_sw189_currentTemperature 255 "SNA" ;
VAL_ 1513 APP_sw190_currentTemperature 255 "SNA" ;
VAL_ 1513 APP_sw278_currentTemperature 255 "SNA" ;
VAL_ 1513 APP_sw280_currentTemperature 255 "SNA" ;
VAL_ 1513 APP_sw277_currentTemperature 255 "SNA" ;
VAL_ 1513 APP_sw183_currentTemperature 255 "SNA" ;
VAL_ 1513 APP_sw186_currentTemperature 255 "SNA" ;
VAL_ 1513 APP_sw185_currentTemperature 255 "SNA" ;
VAL_ 1513 APP_sw259_previous_lcm_app_state 6 "LCM_STATE_JERK_ACTIVE" 9 "LCM_STATE_AEB_OVERRIDE" 8 "LCM_STATE_AEB_ACTIVE" 7 "LCM_STATE_JERK_OVERRIDE" 10 "LCM_STATE_STATIONARY_MANAGEMENT" 3 "LCM_STATE_AVAILABLE" 4 "LCM_STATE_FCW_ACTIVE" 5 "LCM_STATE_FCW_OVERRIDE" 0 "LCM_STATE_FAULT" 2 "LCM_STATE_UNAVAILABLE" 1 "LCM_STATE_OFF" ;
VAL_ 1513 APP_sw188_currentTemperature 255 "SNA" ;
VAL_ 1513 APP_sw281_currentTemperature 255 "SNA" ;
VAL_ 1513 APP_sw182_currentTemperature 255 "SNA" ;
VAL_ 1513 APP_sw276_currentTemperature 255 "SNA" ;
VAL_ 1513 APP_sw282_currentTemperature 255 "SNA" ;
VAL_ 1513 APP_sw275_currentTemperature 255 "SNA" ;
VAL_ 1513 APP_sw184_currentTemperature 255 "SNA" ;
VAL_ 1513 APP_sw269_laneKeepAssist 10 "LSS_LIMITED_CONSTRUCTION" 6 "LSS_LIMITED_MAIN_CAMERA" 0 "LSS_NOMINAL" 11 "LSS_LIMITED_WEATHER" 1 "LSS_LIMITED_LEFT_PILLAR_CAMERA" 5 "LSS_LIMITED_BACKUP_CAMERA" 8 "LSS_LIMITED_FISHEYE_CAMERA" 9 "LSS_LIMITED_TURN_INDICATOR_FAULT" 4 "LSS_LIMITED_RIGHT_REPEATER_CAMERA" 15 "LSS_LIMITED_SNA" 3 "LSS_LIMITED_LEFT_REPEATER_CAMERA" 2 "LSS_LIMITED_RIGHT_PILLAR_CAMERA" 7 "LSS_LIMITED_NARROW_CAMERA" ;
VAL_ 1513 APP_sw279_currentTemperature 255 "SNA" ;
VAL_ 1513 APP_sw263_side 1 "LSS_SIDE_LEFT" 0 "LSS_SIDE_RIGHT" ;
VAL_ 1513 APP_sw269_emergencyLaneKeep 10 "LSS_LIMITED_CONSTRUCTION" 6 "LSS_LIMITED_MAIN_CAMERA" 0 "LSS_NOMINAL" 11 "LSS_LIMITED_WEATHER" 1 "LSS_LIMITED_LEFT_PILLAR_CAMERA" 5 "LSS_LIMITED_BACKUP_CAMERA" 8 "LSS_LIMITED_FISHEYE_CAMERA" 9 "LSS_LIMITED_TURN_INDICATOR_FAULT" 4 "LSS_LIMITED_RIGHT_REPEATER_CAMERA" 15 "LSS_LIMITED_SNA" 3 "LSS_LIMITED_LEFT_REPEATER_CAMERA" 2 "LSS_LIMITED_RIGHT_PILLAR_CAMERA" 7 "LSS_LIMITED_NARROW_CAMERA" ;
VAL_ 1513 APP_sw207_lcUnavailableReason 44 "RR_UNAVAILABLE_INVALID_LANE_LINE_TYPE" 5 "LC_UNAVAILABLE_VEHICLE_NOT_IN_DRIVE" 31 "RR_UNAVAILABLE_HK_TW_RESTRICTED" 35 "RR_UNAVAILABLE_ME_MAIN_STATE_NOT_VISION" 14 "LC_UNAVAILABLE_USER_STRIKEOUT" 40 "RR_UNAVAILABLE_NOT_ON_HIGHWAY" 33 "RR_UNAVAILABLE_EAC_REQUEST_TIMEOUT" 9 "LC_UNAVAILABLE_TRAILER_MODE_ACTIVE" 30 "RR_UNAVAILABLE_CAM_WATCHDOG" 1 "LC_UNAVAILABLE_EPAS_EAC_DENIED" 27 "RR_UNAVAILABLE_STEERING_LIMITS_EXCEEDED" 16 "LC_UNAVAILABLE_APP_ME_STATE_NOT_VISION" 255 "LC_UNAVAILABLE_UNKNOWN" 7 "LC_UNAVAILABLE_STEERING_LIMITS_EXCEEDED" 18 "LC_UNAVAILABLE_NOT_ON_HIGHWAY" 15 "LC_UNAVAILABLE_ME_MAIN_STATE_NOT_VISION" 34 "RR_UNAVAILABLE_USER_STRIKEOUT" 10 "LC_UNAVAILABLE_CAM_WATCHDOG" 2 "LC_UNAVAILABLE_COMPONENT_MIA" 11 "LC_UNAVAILABLE_HK_TW_RESTRICTED" 25 "RR_UNAVAILABLE_VEHICLE_NOT_IN_DRIVE" 23 "RR_UNAVAILABLE_COMPONENT_NOT_READY" 36 "RR_UNAVAILABLE_CONTROL_OUTSIDE_LIMITS" 6 "LC_UNAVAILABLE_VEHICLE_SPEED_ABOVE_MAX" 37 "RR_UNAVAILABLE_CONTROL_PATH_UNHEALTHY" 42 "RR_UNAVAILABLE_ROAD_ESTIMATOR_NOT_ALLOWED" 26 "RR_UNAVAILABLE_VEHICLE_SPEED_ABOVE_MAX" 3 "LC_UNAVAILABLE_COMPONENT_NOT_READY" 24 "RR_UNAVAILABLE_CRUISE_FAULT" 28 "RR_UNAVAILABLE_CAMERA_FAILSAFES" 17 "LC_UNAVAILABLE_SPEED_LIMIT_EXCEEDED" 0 "LC_UNAVAILABLE_NONE" 19 "LC_UNAVAILABLE_VEHICLE_SPEED_ABOVE_MAX_HYST" 22 "RR_UNAVAILABLE_COMPONENT_MIA" 38 "RR_UNAVAILABLE_CONTROL_SOLVER_UNHEALTHY" 21 "RR_UNAVAILABLE_EPAS_EAC_DENIED" 43 "RR_UNAVAILABLE_DRIVE_ON_MAPS_NOT_ALLOWED" 29 "RR_UNAVAILABLE_TRAILER_MODE_ACTIVE" 41 "RR_UNAVAILABLE_VEHICLE_SPEED_ABOVE_MAX_HYST" 13 "LC_UNAVAILABLE_EAC_REQUEST_TIMEOUT" 20 "RR_UNAVAILABLE_NONE" 4 "LC_UNAVAILABLE_CRUISE_FAULT" 8 "LC_UNAVAILABLE_CAMERA_FAILSAFES" 39 "RR_UNAVAILABLE_SPEED_LIMIT_EXCEEDED" 12 "LC_UNAVAILABLE_CAM_MSG_MIA" 32 "RR_UNAVAILABLE_CAM_MSG_MIA" ;
VAL_ 1513 APP_sw266_backupStreamStatus 3 "CAMERA_STREAM_INIT_DEFERRED" 6 "CAMERA_STREAM_FAILED" 5 "CAMERA_STREAM_RECOVERING" 7 "CAMERA_STREAM_FINISHED" 1 "CAMERA_STREAM_INITIALIZING" 2 "CAMERA_STREAM_INIT_FAILED" 0 "CAMERA_STREAM_NOT_ACTIVE" 4 "CAMERA_STREAM_ACTIVE" ;
VAL_ 1513 APP_sw191_epasErrorCode 15 "SNA" 11 "EAC_ERROR_HIGH_TORSION_SAFETY" 4 "EAC_ERROR_TMP_FAULT" 2 "EAC_ERROR_MAX_SPEED" 7 "EAC_ERROR_HIGH_ANGLE_RATE_REQ" 0 "EAC_ERROR_IDLE" 10 "EAC_ERROR_HIGH_MMOT_SAFETY" 6 "EAC_ERROR_HIGH_ANGLE_REQ" 8 "EAC_ERROR_HIGH_ANGLE_SAFETY" 5 "EAR_ERROR_MAX_STEER_DELTA" 13 "EAC_ERROR_PINION_VEL_DIFF" 1 "EAC_ERROR_MIN_SPEED" 14 "EAC_EXTERNAL_MONITOR_INHIBIT" 12 "EAC_ERROR_LOW_ASSIST" 9 "EAC_ERROR_HIGH_ANGLE_RATE_SAFETY" 3 "EAC_ERROR_HANDS_ON" ;
VAL_ 1513 APP_sw140_backupCamSerFault 0 "NO_I2C_FAULT" 4 "I2C_UNKNOWN_IOCTL_ERR" 3 "I2C_DATA_NACK" 2 "I2C_SLAVE_ADDR_NACK" 1 "I2C_BUS_FAULT" ;
VAL_ 1513 APP_sw263_markerType 4 "LSS_MARKER_TYPE_SOLID" 2 "LSS_MARKER_TYPE_EDGE" 1 "LSS_MARKER_TYPE_INVALID" 7 "LSS_MARKER_TYPE_DOTTED" 3 "LSS_MARKER_TYPE_UNMARKED" 5 "LSS_MARKER_TYPE_DOUBLE_SOLID" 0 "LSS_MARKER_TYPE_UNKNOWN" 6 "LSS_MARKER_TYPE_DASHED" ;
VAL_ 1513 APP_sw140_backupCamDeserLock 0 "LOCK_STATUS_LOCKED" 1 "LOCK_STATUS_LOST" 2 "LOCK_STATUS_UNKNOWN" ;
VAL_ 1513 APP_sw279_serializerCrcErrCount 255 "SNA" ;
VAL_ 1513 APP_sw276_serializerCrcErrCount 255 "SNA" ;
VAL_ 1513 APP_sw182_serializerCrcErrCount 255 "SNA" ;
VAL_ 1513 APP_sw281_serializerCrcErrCount 255 "SNA" ;
VAL_ 1513 APP_sw187_serializerCrcErrCount 255 "SNA" ;
VAL_ 1513 APP_sw278_serializerCrcErrCount 255 "SNA" ;
VAL_ 1513 APP_sw275_serializerCrcErrCount 255 "SNA" ;
VAL_ 1513 APP_sw282_serializerCrcErrCount 255 "SNA" ;
VAL_ 1513 APP_sw186_serializerCrcErrCount 255 "SNA" ;
VAL_ 1513 APP_sw274_serializerCrcErrCount 255 "SNA" ;
VAL_ 1513 APP_sw185_serializerCrcErrCount 255 "SNA" ;
VAL_ 1513 APP_sw184_serializerCrcErrCount 255 "SNA" ;
VAL_ 1513 APP_sw191_cruiseState 0 "CRS_STATE_UNAVAILABLE" 6 "CRS_STATE_PRE_FAULT" 5 "CRS_STATE_FAULT" 7 "CRS_STATE_PRE_CANCEL" 3 "CRS_STATE_STANDSTILL" 1 "CRS_STATE_STANDBY" 2 "CRS_STATE_ENABLED" 4 "CRS_STATE_OVERRIDE" ;
VAL_ 1513 APP_sw190_serializerCrcErrCount 255 "SNA" ;
VAL_ 1513 APP_sw189_serializerCrcErrCount 255 "SNA" ;
VAL_ 1513 APP_sw183_serializerCrcErrCount 255 "SNA" ;
VAL_ 1513 APP_sw277_serializerCrcErrCount 255 "SNA" ;
VAL_ 1513 APP_sw280_serializerCrcErrCount 255 "SNA" ;
VAL_ 1513 APP_sw188_serializerCrcErrCount 255 "SNA" ;
VAL_ 1513 APP_sw266_rRepeaterStreamStatus 3 "CAMERA_STREAM_INIT_DEFERRED" 6 "CAMERA_STREAM_FAILED" 5 "CAMERA_STREAM_RECOVERING" 7 "CAMERA_STREAM_FINISHED" 1 "CAMERA_STREAM_INITIALIZING" 2 "CAMERA_STREAM_INIT_FAILED" 0 "CAMERA_STREAM_NOT_ACTIVE" 4 "CAMERA_STREAM_ACTIVE" ;
VAL_ 1513 APP_sw274_imagerHeartbeat 1 "IMAGER_HEARTBEAT_STATIC" 0 "IMAGER_HEARTBEAT_NOMINAL" 3 "IMAGER_HEARTBEAT_SNA" ;
VAL_ 1513 APP_sw275_imagerHeartbeat 1 "IMAGER_HEARTBEAT_STATIC" 0 "IMAGER_HEARTBEAT_NOMINAL" 3 "IMAGER_HEARTBEAT_SNA" ;
VAL_ 1513 APP_sw282_imagerHeartbeat 1 "IMAGER_HEARTBEAT_STATIC" 0 "IMAGER_HEARTBEAT_NOMINAL" 3 "IMAGER_HEARTBEAT_SNA" ;
VAL_ 1513 APP_sw278_imagerHeartbeat 1 "IMAGER_HEARTBEAT_STATIC" 0 "IMAGER_HEARTBEAT_NOMINAL" 3 "IMAGER_HEARTBEAT_SNA" ;
VAL_ 1513 APP_sw186_imagerHeartbeat 1 "IMAGER_HEARTBEAT_STATIC" 0 "IMAGER_HEARTBEAT_NOMINAL" 3 "IMAGER_HEARTBEAT_SNA" ;
VAL_ 1513 APP_sw279_imagerHeartbeat 1 "IMAGER_HEARTBEAT_STATIC" 0 "IMAGER_HEARTBEAT_NOMINAL" 3 "IMAGER_HEARTBEAT_SNA" ;
VAL_ 1513 APP_sw188_imagerHeartbeat 1 "IMAGER_HEARTBEAT_STATIC" 0 "IMAGER_HEARTBEAT_NOMINAL" 3 "IMAGER_HEARTBEAT_SNA" ;
VAL_ 1513 APP_sw187_imagerHeartbeat 1 "IMAGER_HEARTBEAT_STATIC" 0 "IMAGER_HEARTBEAT_NOMINAL" 3 "IMAGER_HEARTBEAT_SNA" ;
VAL_ 1513 APP_sw281_imagerHeartbeat 1 "IMAGER_HEARTBEAT_STATIC" 0 "IMAGER_HEARTBEAT_NOMINAL" 3 "IMAGER_HEARTBEAT_SNA" ;
VAL_ 1513 APP_sw276_imagerHeartbeat 1 "IMAGER_HEARTBEAT_STATIC" 0 "IMAGER_HEARTBEAT_NOMINAL" 3 "IMAGER_HEARTBEAT_SNA" ;
VAL_ 1513 APP_sw182_imagerHeartbeat 1 "IMAGER_HEARTBEAT_STATIC" 0 "IMAGER_HEARTBEAT_NOMINAL" 3 "IMAGER_HEARTBEAT_SNA" ;
VAL_ 1513 APP_sw190_imagerHeartbeat 1 "IMAGER_HEARTBEAT_STATIC" 0 "IMAGER_HEARTBEAT_NOMINAL" 3 "IMAGER_HEARTBEAT_SNA" ;
VAL_ 1513 APP_sw189_imagerHeartbeat 1 "IMAGER_HEARTBEAT_STATIC" 0 "IMAGER_HEARTBEAT_NOMINAL" 3 "IMAGER_HEARTBEAT_SNA" ;
VAL_ 1513 APP_sw184_imagerHeartbeat 1 "IMAGER_HEARTBEAT_STATIC" 0 "IMAGER_HEARTBEAT_NOMINAL" 3 "IMAGER_HEARTBEAT_SNA" ;
VAL_ 1513 APP_sw277_imagerHeartbeat 1 "IMAGER_HEARTBEAT_STATIC" 0 "IMAGER_HEARTBEAT_NOMINAL" 3 "IMAGER_HEARTBEAT_SNA" ;
VAL_ 1513 APP_sw183_imagerHeartbeat 1 "IMAGER_HEARTBEAT_STATIC" 0 "IMAGER_HEARTBEAT_NOMINAL" 3 "IMAGER_HEARTBEAT_SNA" ;
VAL_ 1513 APP_sw280_imagerHeartbeat 1 "IMAGER_HEARTBEAT_STATIC" 0 "IMAGER_HEARTBEAT_NOMINAL" 3 "IMAGER_HEARTBEAT_SNA" ;
VAL_ 1513 APP_sw185_imagerHeartbeat 1 "IMAGER_HEARTBEAT_STATIC" 0 "IMAGER_HEARTBEAT_NOMINAL" 3 "IMAGER_HEARTBEAT_SNA" ;
VAL_ 1513 APP_sw069_diAPState 6 "DI_APC_ABORTED" 8 "DI_APC_UNPARK_COMPLETE" 7 "DI_APC_RESUMED" 0 "DI_APC_UNAVAILABLE" 4 "DI_APC_COMPLETE" 5 "DI_APC_PAUSED" 1 "DI_APC_STANDBY" 3 "DI_APC_ACTIVE" 9 "DI_APC_SNA" 2 "DI_APC_STARTED" ;
VAL_ 1513 APP_sw137_rPillarCamSerFault 0 "NO_I2C_FAULT" 4 "I2C_UNKNOWN_IOCTL_ERR" 3 "I2C_DATA_NACK" 2 "I2C_SLAVE_ADDR_NACK" 1 "I2C_BUS_FAULT" ;
VAL_ 1513 APP_sw147_selfieCamSerFault 0 "NO_I2C_FAULT" 4 "I2C_UNKNOWN_IOCTL_ERR" 3 "I2C_DATA_NACK" 2 "I2C_SLAVE_ADDR_NACK" 1 "I2C_BUS_FAULT" ;
VAL_ 1513 APP_sw024_currentVehicleApp 7 "DAS_VA_BSD" 88 "DAS_VA_VL_GM_COV_VEH_ID1" 150 "DAS_VA_VL_GM_HEADING_VEH_ID3" 36 "DAS_VA_VL_UU" 128 "DAS_VA_VL_GM_DP_FUSE_VEH_ID5" 12 "DAS_VA_TSR" 76 "DAS_VA_VL_GM_CHK_ID_VEH_ID1" 83 "DAS_VA_VL_GM_CHK_LANE_VEH_ID2" 52 "DAS_VA_VL_GM_VEH_ID4" 44 "DAS_VA_VL_GM_HPP_2" 20 "DAS_VA_VL_RLV" 55 "DAS_VA_VL_GM_EVAL_SETUP" 47 "DAS_VA_VL_GM_VEH_2" 95 "DAS_VA_VL_GM_OBS_XFM_VEH_ID2" 141 "DAS_VA_VL_GM_NODP_LONG_VEH_ID0" 14 "DAS_VA_TRAJECTORY_PLANNER" 121 "DAS_VA_VL_GM_DP_OLD_VEH_ID4" 64 "DAS_VA_VL_GM_EVAL_VEH_3" 138 "DAS_VA_VL_GM_NODP_LAT_VEH_ID3" 67 "DAS_VA_VL_GM_EVAL_NEW_VEH_0" 54 "DAS_VA_VL_GM_EVAL" 85 "DAS_VA_VL_GM_CHK_LANE_VEH_ID4" 50 "DAS_VA_VL_GM_VEH_ID2" 106 "DAS_VA_VL_GM_DP_PRECHK_VEH_ID1" 43 "DAS_VA_VL_GM_LANE_2" 154 "DAS_VA_VL_GM_MISC_END_VEH_ID1" 40 "DAS_VA_VL_GM_FS_1" 6 "DAS_VA_AHB" 152 "DAS_VA_VL_GM_HEADING_VEH_ID5" 126 "DAS_VA_VL_GM_DP_FUSE_VEH_ID3" 100 "DAS_VA_VL_GM_INV_COV_VEH_ID1" 75 "DAS_VA_VL_GM_CHK_ID_VEH_ID0" 84 "DAS_VA_VL_GM_CHK_LANE_VEH_ID3" 159 "DAS_VA_VL_GM_VEH_EXIT" 53 "DAS_VA_VL_GM_VEH_ID5" 87 "DAS_VA_VL_GM_COV_VEH_ID0" 149 "DAS_VA_VL_GM_HEADING_VEH_ID2" 161 "DAS_VA_EAC_MONITOR" 127 "DAS_VA_VL_GM_DP_FUSE_VEH_ID4" 120 "DAS_VA_VL_GM_DP_OLD_VEH_ID3" 65 "DAS_VA_VL_GM_EVAL_VEH_4" 19 "DAS_VA_VL_SO" 129 "DAS_VA_VL_GM_NODP_FUSE_VEH_ID0" 139 "DAS_VA_VL_GM_NODP_LAT_VEH_ID4" 111 "DAS_VA_VL_GM_DP_NEW_VEH_ID0" 23 "DAS_VA_VL_UNO" 57 "DAS_VA_VL_GM_EVAL_LL" 29 "DAS_VA_VL_UELP" 98 "DAS_VA_VL_GM_OBS_XFM_VEH_ID5" 151 "DAS_VA_VL_GM_HEADING_VEH_ID4" 125 "DAS_VA_VL_GM_DP_FUSE_VEH_ID2" 99 "DAS_VA_VL_GM_INV_COV_VEH_ID0" 30 "DAS_VA_VL_CFELC" 86 "DAS_VA_VL_GM_CHK_LANE_VEH_ID5" 51 "DAS_VA_VL_GM_VEH_ID3" 105 "DAS_VA_VL_GM_DP_PRECHK_VEH_ID0" 35 "DAS_VA_VL_CDH" 153 "DAS_VA_VL_GM_MISC_END_VEH_ID0" 58 "DAS_VA_VL_GM_EVAL_RL" 148 "DAS_VA_VL_GM_HEADING_VEH_ID1" 90 "DAS_VA_VL_GM_COV_VEH_ID3" 11 "DAS_VA_LDW" 104 "DAS_VA_VL_GM_INV_COV_VEH_ID5" 78 "DAS_VA_VL_GM_CHK_ID_VEH_ID3" 81 "DAS_VA_VL_GM_CHK_LANE_VEH_ID0" 110 "DAS_VA_VL_GM_DP_PRECHK_VEH_ID5" 158 "DAS_VA_VL_GM_MISC_END_VEH_ID5" 112 "DAS_VA_VL_GM_DP_NEW_VEH_ID1" 17 "DAS_VA_VIRTUAL_WALL" 31 "DAS_VA_VL_CMC" 97 "DAS_VA_VL_GM_OBS_XFM_VEH_ID4" 119 "DAS_VA_VL_GM_DP_OLD_VEH_ID2" 60 "DAS_VA_VL_GM_EVAL_NAV" 66 "DAS_VA_VL_GM_EVAL_VEH_5" 28 "DAS_VA_VL_CCM" 130 "DAS_VA_VL_GM_NODP_FUSE_VEH_ID1" 34 "DAS_VA_VL_MP" 9 "DAS_VA_FCM" 140 "DAS_VA_VL_GM_NODP_LAT_VEH_ID5" 135 "DAS_VA_VL_GM_NODP_LAT_VEH_ID0" 70 "DAS_VA_VL_GM_EVAL_NEW_VEH_3" 115 "DAS_VA_VL_GM_DP_NEW_VEH_ID4" 41 "DAS_VA_VL_GM_VEH_1" 94 "DAS_VA_VL_GM_OBS_XFM_VEH_ID1" 144 "DAS_VA_VL_GM_NODP_LONG_VEH_ID3" 25 "DAS_VA_VL_UFC" 61 "DAS_VA_VL_GM_EVAL_VEH_0" 133 "DAS_VA_VL_GM_NODP_FUSE_VEH_ID4" 103 "DAS_VA_VL_GM_INV_COV_VEH_ID4" 56 "DAS_VA_VL_GM_EVAL_MODEL" 77 "DAS_VA_VL_GM_CHK_ID_VEH_ID2" 82 "DAS_VA_VL_GM_CHK_LANE_VEH_ID1" 109 "DAS_VA_VL_GM_DP_PRECHK_VEH_ID4" 39 "DAS_VA_VL_GM_HPP_1" 157 "DAS_VA_VL_GM_MISC_END_VEH_ID4" 22 "DAS_VA_VL_ULWE" 147 "DAS_VA_VL_GM_HEADING_VEH_ID0" 89 "DAS_VA_VL_GM_COV_VEH_ID2" 24 "DAS_VA_VL_FM" 146 "DAS_VA_VL_GM_NODP_LONG_VEH_ID5" 118 "DAS_VA_VL_GM_DP_OLD_VEH_ID1" 26 "DAS_VA_VL_SM" 131 "DAS_VA_VL_GM_NODP_FUSE_VEH_ID2" 72 "DAS_VA_VL_GM_EVAL_NEW_VEH_5" 113 "DAS_VA_VL_GM_DP_NEW_VEH_ID2" 160 "DAS_VA_VL_PROFILER" 93 "DAS_VA_VL_GM_OBS_XFM_VEH_ID0" 143 "DAS_VA_VL_GM_NODP_LONG_VEH_ID2" 46 "DAS_VA_VL_GM_NAV_2" 62 "DAS_VA_VL_GM_EVAL_VEH_1" 21 "DAS_VA_VL_CFKO" 134 "DAS_VA_VL_GM_NODP_FUSE_VEH_ID5" 136 "DAS_VA_VL_GM_NODP_LAT_VEH_ID1" 69 "DAS_VA_VL_GM_EVAL_NEW_VEH_2" 116 "DAS_VA_VL_GM_DP_NEW_VEH_ID5" 59 "DAS_VA_VL_GM_EVAL_HPP" 108 "DAS_VA_VL_GM_DP_PRECHK_VEH_ID3" 156 "DAS_VA_VL_GM_MISC_END_VEH_ID3" 92 "DAS_VA_VL_GM_COV_VEH_ID5" 124 "DAS_VA_VL_GM_DP_FUSE_VEH_ID1" 5 "DAS_VA_SCA" 102 "DAS_VA_VL_GM_INV_COV_VEH_ID3" 80 "DAS_VA_VL_GM_CHK_ID_VEH_ID5" 10 "DAS_VA_ACC" 13 "DAS_VA_CSA" 48 "DAS_VA_VL_GM_VEH_ID0" 71 "DAS_VA_VL_GM_EVAL_NEW_VEH_4" 4 "DAS_VA_APC" 15 "DAS_VA_WORLD_MODEL" 114 "DAS_VA_VL_GM_DP_NEW_VEH_ID3" 1 "DAS_VA_INIT" 0 "DAS_VA_NONE" 145 "DAS_VA_VL_GM_NODP_LONG_VEH_ID4" 117 "DAS_VA_VL_GM_DP_OLD_VEH_ID0" 132 "DAS_VA_VL_GM_NODP_FUSE_VEH_ID3" 8 "DAS_VA_LC" 74 "DAS_VA_ROB" 18 "DAS_VA_ROAD_FURNITURE" 32 "DAS_VA_VL_GM" 137 "DAS_VA_VL_GM_NODP_LAT_VEH_ID2" 68 "DAS_VA_VL_GM_EVAL_NEW_VEH_1" 33 "DAS_VA_VL_ETC" 27 "DAS_VA_VL_CDE" 37 "DAS_VA_VL_GM_SETUP" 96 "DAS_VA_VL_GM_OBS_XFM_VEH_ID3" 142 "DAS_VA_VL_GM_NODP_LONG_VEH_ID1" 42 "DAS_VA_VL_GM_NAV_1" 122 "DAS_VA_VL_GM_DP_OLD_VEH_ID5" 63 "DAS_VA_VL_GM_EVAL_VEH_2" 2 "DAS_VA_VEHICLE" 123 "DAS_VA_VL_GM_DP_FUSE_VEH_ID0" 101 "DAS_VA_VL_GM_INV_COV_VEH_ID2" 73 "DAS_VA_VL_GM_EVAL_SAVE" 3 "DAS_VA_PMM" 79 "DAS_VA_VL_GM_CHK_ID_VEH_ID4" 49 "DAS_VA_VL_GM_VEH_ID1" 107 "DAS_VA_VL_GM_DP_PRECHK_VEH_ID2" 155 "DAS_VA_VL_GM_MISC_END_VEH_ID2" 38 "DAS_VA_VL_GM_LANE_1" 45 "DAS_VA_VL_GM_FS_2" 16 "DAS_VA_VIRTUAL_LANE" 91 "DAS_VA_VL_GM_COV_VEH_ID4" ;
VAL_ 1513 APP_sw266_lRepeaterStreamStatus 3 "CAMERA_STREAM_INIT_DEFERRED" 6 "CAMERA_STREAM_FAILED" 5 "CAMERA_STREAM_RECOVERING" 7 "CAMERA_STREAM_FINISHED" 1 "CAMERA_STREAM_INITIALIZING" 2 "CAMERA_STREAM_INIT_FAILED" 0 "CAMERA_STREAM_NOT_ACTIVE" 4 "CAMERA_STREAM_ACTIVE" ;
VAL_ 1513 APP_sw138_lRepeatCamSerFault 0 "NO_I2C_FAULT" 4 "I2C_UNKNOWN_IOCTL_ERR" 3 "I2C_DATA_NACK" 2 "I2C_SLAVE_ADDR_NACK" 1 "I2C_BUS_FAULT" ;
VAL_ 1513 APP_sw191_handsOnState 8 "LC_HANDS_ON_SUSPENDED" 15 "LC_HANDS_ON_SNA" 7 "LC_HANDS_ON_REQD_STRUCK_OUT" 3 "LC_HANDS_ON_REQD_VISUAL" 4 "LC_HANDS_ON_REQD_CHIME_1" 6 "LC_HANDS_ON_REQD_SLOWING" 1 "LC_HANDS_ON_REQD_DETECTED" 2 "LC_HANDS_ON_REQD_NOT_DETECTED" 5 "LC_HANDS_ON_REQD_CHIME_2" 0 "LC_HANDS_ON_NOT_REQD" ;
VAL_ 1513 APP_sw139_rRepeatCamSerFault 0 "NO_I2C_FAULT" 4 "I2C_UNKNOWN_IOCTL_ERR" 3 "I2C_DATA_NACK" 2 "I2C_SLAVE_ADDR_NACK" 1 "I2C_BUS_FAULT" ;
VAL_ 1513 APP_sw031_errorType 1 "Length" 6 "Mailbox" 0 "None" 2 "Checksum" 5 "Overrun" 3 "Sequence" 7 "CAN_Bus" 4 "Invalid_Data" 8 "Generic" ;
VAL_ 1513 APP_sw136_lPillarCamSerFault 0 "NO_I2C_FAULT" 4 "I2C_UNKNOWN_IOCTL_ERR" 3 "I2C_DATA_NACK" 2 "I2C_SLAVE_ADDR_NACK" 1 "I2C_BUS_FAULT" ;
VAL_ 1513 APP_sw135_fisheyeCamSerFault 0 "NO_I2C_FAULT" 4 "I2C_UNKNOWN_IOCTL_ERR" 3 "I2C_DATA_NACK" 2 "I2C_SLAVE_ADDR_NACK" 1 "I2C_BUS_FAULT" ;
VAL_ 1513 APP_sw133_mainCamSerFault 0 "NO_I2C_FAULT" 4 "I2C_UNKNOWN_IOCTL_ERR" 3 "I2C_DATA_NACK" 2 "I2C_SLAVE_ADDR_NACK" 1 "I2C_BUS_FAULT" ;
VAL_ 1513 APP_sw134_narrowCamSerFault 0 "NO_I2C_FAULT" 4 "I2C_UNKNOWN_IOCTL_ERR" 3 "I2C_DATA_NACK" 2 "I2C_SLAVE_ADDR_NACK" 1 "I2C_BUS_FAULT" ;
VAL_ 1513 APP_sw140_backupCamSensorFault 0 "NO_I2C_FAULT" 4 "I2C_UNKNOWN_IOCTL_ERR" 3 "I2C_DATA_NACK" 2 "I2C_SLAVE_ADDR_NACK" 1 "I2C_BUS_FAULT" ;
VAL_ 1513 APP_sw265_unavailableReason 0 "DON_UNAVAILABLE_NONE" 9 "DON_AUTO_WIPER_ACTIVE" 10 "DON_CONSTRUCTION_DETECTED" 11 "DON_TOLLBOOTH_DETECTED" 14 "DON_AUTOPILOT_UNAVAILABLE" 3 "DON_UNAVAILABLE_CAMERA_BLOCKED" 4 "DON_ROUTE_DOWNLOAD_FAILED" 16 "DON_NAV_ROUTE_NOT_ACTIVE" 1 "DON_INVALID_NAV_GOAL" 13 "DON_INCOMPATIBLE_WAY" 8 "DON_IMPLAUSIBLE_MAP_DATA" 12 "DON_HIGH_CURVATURE" 2 "DON_CAMERA_UNAVAILABLE" 15 "DON_FEATURE_NOT_ENABLED" 5 "DON_EDGE_LOCALIZATION_FAILED" 7 "DON_GPS_DEGRADED" 6 "DON_ULTRASONICS_INVALID" ;
VAL_ 1513 APP_sw192_vehicleAutopilotType 1 "VEHICLE_AUTOPILOT_HW2" 2 "VEHICLE_AUTOPILOT_HW2_5" 0 "VEHICLE_AUTOPILOT_UNKNOWN" ;
VAL_ 1513 APP_sw199_abortCodePARK 31 "SNA" 15 "SYSTEM_SERVICE" 11 "HANDS_ON_DETECTED" 6 "MAX_SWA_DEV_EXCEEDED" 0 "NONE" 8 "OBSTACLE_ON_PATH" 1 "VELOCITY_TOO_HIGH" 17 "ERROR" 12 "VEHICLE_DYNAMICS_INTERVENTION" 10 "FULL_WARNING_ON_BOTH_SIDES" 5 "OFF_TRACK" 13 "EPAS_FAULT" 3 "NO_VALID_PATH" 9 "PARK_SPACE_TOO_SMALL" 4 "UNCONTROLLED_TRAVEL_DIST_REACHED" 16 "SYSTEM_FAULT" 14 "DAS_ABORT" 2 "MAX_NUM_OF_MOVES" 7 "MAX_YAW_ANGLE_REACHED" ;
VAL_ 1513 APP_sw271_direction 1 "ALC_DIRECTION_LEFT" 0 "ALC_DIRECTION_RIGHT" ;
VAL_ 1513 APP_sw192_hardwareType 2 "HARDWARE_25" 0 "HARDWARE_UNKNOWN" 1 "HARDWARE_2" ;
VAL_ 1513 APP_sw279_tempMonitorFailure 0 "TEMPERATURE_MONITOR_NO_FAILURE" 1 "TEMPERATURE_OUT_OF_SPEC" 2 "TEMPERATURE_MONITOR_OTHER_FAILURE" ;
VAL_ 1513 APP_sw187_tempMonitorFailure 0 "TEMPERATURE_MONITOR_NO_FAILURE" 1 "TEMPERATURE_OUT_OF_SPEC" 2 "TEMPERATURE_MONITOR_OTHER_FAILURE" ;
VAL_ 1513 APP_sw184_tempMonitorFailure 0 "TEMPERATURE_MONITOR_NO_FAILURE" 1 "TEMPERATURE_OUT_OF_SPEC" 2 "TEMPERATURE_MONITOR_OTHER_FAILURE" ;
VAL_ 1513 APP_sw139_rRepeatCamSensorFault 0 "NO_I2C_FAULT" 4 "I2C_UNKNOWN_IOCTL_ERR" 3 "I2C_DATA_NACK" 2 "I2C_SLAVE_ADDR_NACK" 1 "I2C_BUS_FAULT" ;
VAL_ 1513 APP_sw273_side 1 "LSS_SIDE_LEFT" 0 "LSS_SIDE_RIGHT" ;
VAL_ 1513 APP_sw275_tempMonitorFailure 0 "TEMPERATURE_MONITOR_NO_FAILURE" 1 "TEMPERATURE_OUT_OF_SPEC" 2 "TEMPERATURE_MONITOR_OTHER_FAILURE" ;
VAL_ 1513 APP_sw282_tempMonitorFailure 0 "TEMPERATURE_MONITOR_NO_FAILURE" 1 "TEMPERATURE_OUT_OF_SPEC" 2 "TEMPERATURE_MONITOR_OTHER_FAILURE" ;
VAL_ 1513 APP_sw265_surroundCameraStatus 0 "CAMERA_AVAILABLE" 2 "CAMERA_PERMANENT_UNAVAILABLE" 1 "CAMERA_TEMPORARY_UNAVAILABLE" ;
VAL_ 1513 APP_sw134_narrowCamSensorFault 0 "NO_I2C_FAULT" 4 "I2C_UNKNOWN_IOCTL_ERR" 3 "I2C_DATA_NACK" 2 "I2C_SLAVE_ADDR_NACK" 1 "I2C_BUS_FAULT" ;
VAL_ 1513 APP_sw133_mainCamSensorFault 0 "NO_I2C_FAULT" 4 "I2C_UNKNOWN_IOCTL_ERR" 3 "I2C_DATA_NACK" 2 "I2C_SLAVE_ADDR_NACK" 1 "I2C_BUS_FAULT" ;
VAL_ 1513 APP_sw136_lPillarCamSensorFault 0 "NO_I2C_FAULT" 4 "I2C_UNKNOWN_IOCTL_ERR" 3 "I2C_DATA_NACK" 2 "I2C_SLAVE_ADDR_NACK" 1 "I2C_BUS_FAULT" ;
VAL_ 1513 APP_sw135_fisheyeCamSensorFault 0 "NO_I2C_FAULT" 4 "I2C_UNKNOWN_IOCTL_ERR" 3 "I2C_DATA_NACK" 2 "I2C_SLAVE_ADDR_NACK" 1 "I2C_BUS_FAULT" ;
VAL_ 1513 APP_sw188_tempMonitorFailure 0 "TEMPERATURE_MONITOR_NO_FAILURE" 1 "TEMPERATURE_OUT_OF_SPEC" 2 "TEMPERATURE_MONITOR_OTHER_FAILURE" ;
VAL_ 1513 APP_sw185_tempMonitorFailure 0 "TEMPERATURE_MONITOR_NO_FAILURE" 1 "TEMPERATURE_OUT_OF_SPEC" 2 "TEMPERATURE_MONITOR_OTHER_FAILURE" ;
VAL_ 1513 APP_sw281_tempMonitorFailure 0 "TEMPERATURE_MONITOR_NO_FAILURE" 1 "TEMPERATURE_OUT_OF_SPEC" 2 "TEMPERATURE_MONITOR_OTHER_FAILURE" ;
VAL_ 1513 APP_sw182_tempMonitorFailure 0 "TEMPERATURE_MONITOR_NO_FAILURE" 1 "TEMPERATURE_OUT_OF_SPEC" 2 "TEMPERATURE_MONITOR_OTHER_FAILURE" ;
VAL_ 1513 APP_sw276_tempMonitorFailure 0 "TEMPERATURE_MONITOR_NO_FAILURE" 1 "TEMPERATURE_OUT_OF_SPEC" 2 "TEMPERATURE_MONITOR_OTHER_FAILURE" ;
VAL_ 1513 APP_sw137_rPillarCamSensorFault 0 "NO_I2C_FAULT" 4 "I2C_UNKNOWN_IOCTL_ERR" 3 "I2C_DATA_NACK" 2 "I2C_SLAVE_ADDR_NACK" 1 "I2C_BUS_FAULT" ;
VAL_ 1513 APP_sw278_tempMonitorFailure 0 "TEMPERATURE_MONITOR_NO_FAILURE" 1 "TEMPERATURE_OUT_OF_SPEC" 2 "TEMPERATURE_MONITOR_OTHER_FAILURE" ;
VAL_ 1513 APP_sw190_tempMonitorFailure 0 "TEMPERATURE_MONITOR_NO_FAILURE" 1 "TEMPERATURE_OUT_OF_SPEC" 2 "TEMPERATURE_MONITOR_OTHER_FAILURE" ;
VAL_ 1513 APP_sw189_tempMonitorFailure 0 "TEMPERATURE_MONITOR_NO_FAILURE" 1 "TEMPERATURE_OUT_OF_SPEC" 2 "TEMPERATURE_MONITOR_OTHER_FAILURE" ;
VAL_ 1513 APP_sw186_tempMonitorFailure 0 "TEMPERATURE_MONITOR_NO_FAILURE" 1 "TEMPERATURE_OUT_OF_SPEC" 2 "TEMPERATURE_MONITOR_OTHER_FAILURE" ;
VAL_ 1513 APP_sw280_tempMonitorFailure 0 "TEMPERATURE_MONITOR_NO_FAILURE" 1 "TEMPERATURE_OUT_OF_SPEC" 2 "TEMPERATURE_MONITOR_OTHER_FAILURE" ;
VAL_ 1513 APP_sw183_tempMonitorFailure 0 "TEMPERATURE_MONITOR_NO_FAILURE" 1 "TEMPERATURE_OUT_OF_SPEC" 2 "TEMPERATURE_MONITOR_OTHER_FAILURE" ;
VAL_ 1513 APP_sw277_tempMonitorFailure 0 "TEMPERATURE_MONITOR_NO_FAILURE" 1 "TEMPERATURE_OUT_OF_SPEC" 2 "TEMPERATURE_MONITOR_OTHER_FAILURE" ;
VAL_ 1513 APP_sw138_lRepeatCamSensorFault 0 "NO_I2C_FAULT" 4 "I2C_UNKNOWN_IOCTL_ERR" 3 "I2C_DATA_NACK" 2 "I2C_SLAVE_ADDR_NACK" 1 "I2C_BUS_FAULT" ;
VAL_ 1513 APP_sw147_selfieCamSensorFault 0 "NO_I2C_FAULT" 4 "I2C_UNKNOWN_IOCTL_ERR" 3 "I2C_DATA_NACK" 2 "I2C_SLAVE_ADDR_NACK" 1 "I2C_BUS_FAULT" ;
VAL_ 1513 APP_sw274_tempMonitorFailure 0 "TEMPERATURE_MONITOR_NO_FAILURE" 1 "TEMPERATURE_OUT_OF_SPEC" 2 "TEMPERATURE_MONITOR_OTHER_FAILURE" ;
VAL_ 1513 APP_sw042_abort_reason 0 "LC_ABORT_NONE" 24 "LC_ABORT_DRIVE_ON_MAPS" 6 "LC_ABORT_HEALTH_MONITOR" 20 "RR_ABORT_CONTROLLER_HEALTH" 11 "LC_ABORT_CAMERA_FAILSAFES" 18 "LC_ABORT_APP_ME_STATE" 25 "LC_ABORT_AEB" 3 "LC_ABORT_CRUISE_FAULT" 15 "LC_ABORT_CAMERA_WATCHDOG" 4 "LC_ABORT_CID_SWITCH_DISABLED" 17 "LC_ABORT_ME_MAIN_STATE" 22 "LC_ABORT_CRUISE_WENT_UNAVAILABLE" 23 "LC_ABORT_ECU_THERMAL_ISSUE" 10 "LC_ABORT_EPAS_ERROR_CODE" 14 "LC_ABORT_TRAILER_MODE_ACTIVATION" 1 "LC_ABORT_EPAS_EAC_DENIED" 5 "LC_ABORT_DRIVING_OFF_NAV" 8 "LC_ABORT_FOLLOWER_OUTPUT_INVALID" 12 "LC_ABORT_ACC_CANCEL" 21 "RR_ABORT_CONTROL_NOT_ALLOWED" 16 "LC_ABORT_CAMERA_MSG_MIA" 19 "RR_ABORT_WATCHDOG_HEALTH_CRITICAL" 2 "LC_ABORT_COMPONENT_MIA" 7 "LC_ABORT_VEHICLE_SPEED_ABOVE_MAX" 13 "LC_ABORT_SIDE_COLLISION_IMMINENT" 9 "LC_ABORT_PLANNER_OUTPUT_INVALID" ;
VAL_ 1513 APP_sw266_rPillarStreamStatus 3 "CAMERA_STREAM_INIT_DEFERRED" 6 "CAMERA_STREAM_FAILED" 5 "CAMERA_STREAM_RECOVERING" 7 "CAMERA_STREAM_FINISHED" 1 "CAMERA_STREAM_INITIALIZING" 2 "CAMERA_STREAM_INIT_FAILED" 0 "CAMERA_STREAM_NOT_ACTIVE" 4 "CAMERA_STREAM_ACTIVE" ;
VAL_ 1513 APP_sw166_expectedColorFilter 0 "COLOR_FILTER_RCCC" 2 "COLOR_FILTER_RGGB" 3 "COLOR_FILTER_UNKNOWN" 1 "COLOR_FILTER_RCCB" ;
VAL_ 1513 APP_sw146_packageType 0 "STREAM" 1 "S3_UPLOAD" ;
VAL_ 1513 APP_sw168_expectedColorFilter 0 "COLOR_FILTER_RCCC" 2 "COLOR_FILTER_RGGB" 3 "COLOR_FILTER_UNKNOWN" 1 "COLOR_FILTER_RCCB" ;
VAL_ 1513 APP_sw140_backupCamDeserFault 0 "NO_I2C_FAULT" 4 "I2C_UNKNOWN_IOCTL_ERR" 3 "I2C_DATA_NACK" 2 "I2C_SLAVE_ADDR_NACK" 1 "I2C_BUS_FAULT" ;
VAL_ 1513 APP_sw167_expectedColorFilter 0 "COLOR_FILTER_RCCC" 2 "COLOR_FILTER_RGGB" 3 "COLOR_FILTER_UNKNOWN" 1 "COLOR_FILTER_RCCB" ;
VAL_ 1513 APP_sw162_expectedColorFilter 0 "COLOR_FILTER_RCCC" 2 "COLOR_FILTER_RGGB" 3 "COLOR_FILTER_UNKNOWN" 1 "COLOR_FILTER_RCCB" ;
VAL_ 1513 APP_sw169_expectedColorFilter 0 "COLOR_FILTER_RCCC" 2 "COLOR_FILTER_RGGB" 3 "COLOR_FILTER_UNKNOWN" 1 "COLOR_FILTER_RCCB" ;
VAL_ 1513 APP_sw170_expectedColorFilter 0 "COLOR_FILTER_RCCC" 2 "COLOR_FILTER_RGGB" 3 "COLOR_FILTER_UNKNOWN" 1 "COLOR_FILTER_RCCB" ;
VAL_ 1513 APP_sw164_expectedColorFilter 0 "COLOR_FILTER_RCCC" 2 "COLOR_FILTER_RGGB" 3 "COLOR_FILTER_UNKNOWN" 1 "COLOR_FILTER_RCCB" ;
VAL_ 1513 APP_sw163_expectedColorFilter 0 "COLOR_FILTER_RCCC" 2 "COLOR_FILTER_RGGB" 3 "COLOR_FILTER_UNKNOWN" 1 "COLOR_FILTER_RCCB" ;
VAL_ 1513 APP_sw165_expectedColorFilter 0 "COLOR_FILTER_RCCC" 2 "COLOR_FILTER_RGGB" 3 "COLOR_FILTER_UNKNOWN" 1 "COLOR_FILTER_RCCB" ;
VAL_ 1513 APP_sw073_escalateLDWreason 0 "LC_ELDW_REASON_NONE" 1 "LC_ELDW_REASON_SINGLE_PULL" 3 "LC_ELDW_REASON_STW_TAKEOVER" 2 "LC_ELDW_REASON_DOUBLE_PULL" ;
VAL_ 1513 APP_sw192_chassisType 0 "CHASSIS_UNKNOWN" 2 "CHASSIS_MODELX" 3 "CHASSIS_MODEL3" 1 "CHASSIS_MODELS" ;
VAL_ 1513 APP_sw227_sensorNumber 1 "SENSOR_MIDDLE" 0 "SENSOR_FRONT" ;
VAL_ 1513 APP_sw166_detectedColorFilter 0 "COLOR_FILTER_RCCC" 2 "COLOR_FILTER_RGGB" 3 "COLOR_FILTER_UNKNOWN" 1 "COLOR_FILTER_RCCB" ;
VAL_ 1513 APP_sw168_detectedColorFilter 0 "COLOR_FILTER_RCCC" 2 "COLOR_FILTER_RGGB" 3 "COLOR_FILTER_UNKNOWN" 1 "COLOR_FILTER_RCCB" ;
VAL_ 1513 APP_sw167_detectedColorFilter 0 "COLOR_FILTER_RCCC" 2 "COLOR_FILTER_RGGB" 3 "COLOR_FILTER_UNKNOWN" 1 "COLOR_FILTER_RCCB" ;
VAL_ 1513 APP_sw162_detectedColorFilter 0 "COLOR_FILTER_RCCC" 2 "COLOR_FILTER_RGGB" 3 "COLOR_FILTER_UNKNOWN" 1 "COLOR_FILTER_RCCB" ;
VAL_ 1513 APP_sw170_detectedColorFilter 0 "COLOR_FILTER_RCCC" 2 "COLOR_FILTER_RGGB" 3 "COLOR_FILTER_UNKNOWN" 1 "COLOR_FILTER_RCCB" ;
VAL_ 1513 APP_sw169_detectedColorFilter 0 "COLOR_FILTER_RCCC" 2 "COLOR_FILTER_RGGB" 3 "COLOR_FILTER_UNKNOWN" 1 "COLOR_FILTER_RCCB" ;
VAL_ 1513 APP_sw164_detectedColorFilter 0 "COLOR_FILTER_RCCC" 2 "COLOR_FILTER_RGGB" 3 "COLOR_FILTER_UNKNOWN" 1 "COLOR_FILTER_RCCB" ;
VAL_ 1513 APP_sw273_collisionType 4 "APP_LSS_COLLISION_TYPE_ROAD_EDGE" 1 "APP_LSS_COLLISION_TYPE_OVERTAKING" 3 "APP_LSS_COLLISION_TYPE_ONCOMING" 2 "APP_LSS_COLLISION_TYPE_ADJACENT" 0 "APP_LSS_COLLISION_TYPE_NONE" ;
VAL_ 1513 APP_sw163_detectedColorFilter 0 "COLOR_FILTER_RCCC" 2 "COLOR_FILTER_RGGB" 3 "COLOR_FILTER_UNKNOWN" 1 "COLOR_FILTER_RCCB" ;
VAL_ 1513 APP_sw165_detectedColorFilter 0 "COLOR_FILTER_RCCC" 2 "COLOR_FILTER_RGGB" 3 "COLOR_FILTER_UNKNOWN" 1 "COLOR_FILTER_RCCB" ;
VAL_ 1513 APP_sw189_exitStatus 0 "STREAM_EXIT_NOMINAL" 1 "STREAM_EXIT_FAULT" ;
VAL_ 1513 APP_sw190_exitStatus 0 "STREAM_EXIT_NOMINAL" 1 "STREAM_EXIT_FAULT" ;
VAL_ 1513 APP_sw280_exitStatus 0 "STREAM_EXIT_NOMINAL" 1 "STREAM_EXIT_FAULT" ;
VAL_ 1513 APP_sw139_rRepeatCamDeserFault 0 "NO_I2C_FAULT" 4 "I2C_UNKNOWN_IOCTL_ERR" 3 "I2C_DATA_NACK" 2 "I2C_SLAVE_ADDR_NACK" 1 "I2C_BUS_FAULT" ;
VAL_ 1513 APP_sw183_exitStatus 0 "STREAM_EXIT_NOMINAL" 1 "STREAM_EXIT_FAULT" ;
VAL_ 1513 APP_sw277_exitStatus 0 "STREAM_EXIT_NOMINAL" 1 "STREAM_EXIT_FAULT" ;
VAL_ 1513 APP_sw146_telemProblemType 0 "UNKNOWN" 1 "PACKAGE_EXPIRED" ;
VAL_ 1513 APP_sw137_rPillarCamDeserFault 0 "NO_I2C_FAULT" 4 "I2C_UNKNOWN_IOCTL_ERR" 3 "I2C_DATA_NACK" 2 "I2C_SLAVE_ADDR_NACK" 1 "I2C_BUS_FAULT" ;
VAL_ 1513 APP_sw274_exitStatus 0 "STREAM_EXIT_NOMINAL" 1 "STREAM_EXIT_FAULT" ;
VAL_ 1513 APP_sw185_exitStatus 0 "STREAM_EXIT_NOMINAL" 1 "STREAM_EXIT_FAULT" ;
VAL_ 1513 APP_sw191_abortReason 20 "ABORT_RADAR_FAULT" 27 "ABORT_CONTROLLER_NOT_ALLOWED" 11 "ABORT_CRUISE_NOT_ACTIVE" 24 "ABORT_ROAD_ESTIMATOR_HEALTH" 13 "ABORT_TRAILER_MODE_ACTIVE" 63 "ABORT_REASON_MAX" 29 "ABORT_MAP_HEALTH" 16 "ABORT_EPAS_EAC_ERROR" 30 "ABORT_CONTROLLER_STALE_REFERENCE" 28 "ABORT_THERMAL_ISSUE" 12 "ABORT_USER_DISABLED" 8 "ABORT_VCFRONT_MIA" 22 "ABORT_ACC_CANCEL_SILENT" 15 "ABORT_EPAS_EAC_NOT_ACTIVE" 1 "ABORT_WATCHDOG_HEALTH" 37 "ABORT_REACHED_END_OF_NAV_STOP" 14 "ABORT_VEHICLE_SPEED_ABOVE_MAX" 6 "ABORT_SCCM_MIA" 32 "ABORT_CONTROLLER_BAD_REF_UPDATE" 23 "ABORT_ACC_FAULT" 0 "ABORT_NONE" 26 "ABORT_CONTROLLER_SOLVER" 2 "ABORT_DI_MIA" 35 "ABORT_MISSION_PLANNER_NO_VISION_LANES_FOUND" 9 "ABORT_VCRIGHT_MIA" 36 "ABORT_GORE_INCURSION" 25 "ABORT_CONTROLLER_REFERENCE" 31 "ABORT_CONTROLLER_STALE_LOCALIZATION" 38 "ABORT_STEERING_SATURATED_LANE_DEPARTURE" 4 "ABORT_EPAS_MIA" 10 "ABORT_CRUISE_FAULT" 17 "ABORT_CAMERA_FAILSAFES" 21 "ABORT_ACC_CANCEL_GENERIC" 5 "ABORT_GTW_MIA" 33 "ABORT_AEB" 7 "ABORT_RADAR_MIA" 19 "ABORT_RADAR_BLIND" 3 "ABORT_ESP_MIA" 18 "ABORT_CAMERA_CALIBRATION" 34 "ABORT_CONTROLLER_REF_TOO_SHORT" ;
VAL_ 1513 APP_sw271_abortReason 9 "ALC_ABORT_AUTOSTEER_ACTIVATED" 20 "ALC_ABORT_NO_HANDS_ON" 19 "ALC_ABORT_TOLL_BOOTH_DETECTED" 4 "ALC_ABORT_BLIND_SPOT_OCCUPIED_TIMEOUT" 11 "ALC_ABORT_BELOW_MIN_SPEED" 6 "ALC_ABORT_FORK_AVAILABLE" 21 "ALC_ABORT_SOURCE_AND_TARGET_LANES_MERGED" 15 "ALC_ABORT_ULC_CONFIRMATION_TIMEOUT" 5 "ALC_ABORT_LINE_TYPE" 3 "ALC_ABORT_BLINKER_CHANGE" 13 "ALC_ABORT_ULC_BLINKER_TIMEOUT" 18 "ALC_ABORT_CONSTRUCTION_DETECTED" 17 "ALC_ABORT_GORE_POINT" 0 "ALC_ABORT_NONE" 2 "ALC_ABORT_ALC_TIMEOUT" 1 "ALC_ABORT_CONTROL_INACTIVE" 16 "ALC_ABORT_ALC_REQUEST_BEFORE_ULC_CONFIRM" 12 "ALC_ABORT_REQUESTED_BEHAVIOR_CHANGED" 8 "ALC_ABORT_LOST_VISION_POSE" 10 "ALC_ABORT_INVALID_BEHAVIOR" 14 "ALC_ABORT_HIGH_ALC_PROGRESS_ERROR" 7 "ALC_ABORT_INVALID_MODE" ;
VAL_ 1513 APP_sw135_fisheyeCamDeserFault 0 "NO_I2C_FAULT" 4 "I2C_UNKNOWN_IOCTL_ERR" 3 "I2C_DATA_NACK" 2 "I2C_SLAVE_ADDR_NACK" 1 "I2C_BUS_FAULT" ;
VAL_ 1513 APP_sw133_mainCamDeserFault 0 "NO_I2C_FAULT" 4 "I2C_UNKNOWN_IOCTL_ERR" 3 "I2C_DATA_NACK" 2 "I2C_SLAVE_ADDR_NACK" 1 "I2C_BUS_FAULT" ;
VAL_ 1513 APP_sw227_sensorSide 0 "VEHICLE_SIDE_LEFT" 1 "VEHICLE_SIDE_RIGHT" ;
VAL_ 1513 APP_sw136_lPillarCamDeserFault 0 "NO_I2C_FAULT" 4 "I2C_UNKNOWN_IOCTL_ERR" 3 "I2C_DATA_NACK" 2 "I2C_SLAVE_ADDR_NACK" 1 "I2C_BUS_FAULT" ;
VAL_ 1513 APP_sw278_exitStatus 0 "STREAM_EXIT_NOMINAL" 1 "STREAM_EXIT_FAULT" ;
VAL_ 1513 APP_sw192_speakerFailureType 1 "INIT_ERROR" 2 "SETUP_ERROR" 0 "INIT_WAITING" 3 "WAKEUP_ERROR" ;
VAL_ 1513 APP_sw138_lRepeatCamDeserFault 0 "NO_I2C_FAULT" 4 "I2C_UNKNOWN_IOCTL_ERR" 3 "I2C_DATA_NACK" 2 "I2C_SLAVE_ADDR_NACK" 1 "I2C_BUS_FAULT" ;
VAL_ 1513 APP_sw272_unavailableReason 5 "ALC_FORK_MODE" 9 "ALC_NO_REAR_OBJECT_DETECTED" 0 "ALC_NONE" 1 "ALC_NOT_ENABLED" 6 "ALC_ULTRASONICS_NOT_READY" 4 "ALC_NO_LANES" 8 "ALC_CRITICAL_SITUATION" 2 "ALC_ROAD_NOT_APPROPRIATE" 7 "ALC_BLINDSPOT_RESTRICTED" 3 "ALC_SPEED" ;
VAL_ 1513 APP_sw266_lPillarStreamStatus 3 "CAMERA_STREAM_INIT_DEFERRED" 6 "CAMERA_STREAM_FAILED" 5 "CAMERA_STREAM_RECOVERING" 7 "CAMERA_STREAM_FINISHED" 1 "CAMERA_STREAM_INITIALIZING" 2 "CAMERA_STREAM_INIT_FAILED" 0 "CAMERA_STREAM_NOT_ACTIVE" 4 "CAMERA_STREAM_ACTIVE" ;
VAL_ 1513 APP_sw275_exitStatus 0 "STREAM_EXIT_NOMINAL" 1 "STREAM_EXIT_FAULT" ;
VAL_ 1513 APP_sw282_exitStatus 0 "STREAM_EXIT_NOMINAL" 1 "STREAM_EXIT_FAULT" ;
VAL_ 1513 APP_sw140_backupCamCSIBridgeFlt 0 "NO_I2C_FAULT" 4 "I2C_UNKNOWN_IOCTL_ERR" 3 "I2C_DATA_NACK" 2 "I2C_SLAVE_ADDR_NACK" 1 "I2C_BUS_FAULT" ;
VAL_ 1513 APP_sw186_exitStatus 0 "STREAM_EXIT_NOMINAL" 1 "STREAM_EXIT_FAULT" ;
VAL_ 1513 APP_sw264_faultReason 4 "LSS_FAULT_REASON_CAMERA_MAIN" 3 "LSS_FAULT_REASON_EPAS_MIA" 6 "LSS_FAULT_REASON_CAMERA_FISHEYE" 7 "LSS_FAULT_REASON_INVALID" 1 "LSS_FAULT_REASON_EAC_INHIBIT" 5 "LSS_FAULT_REASON_CAMERA_NARROW" 2 "LSS_FAULT_REASON_EPAS_UNRESPONSIVE" 0 "LSS_FAULT_REASON_NO_FAULT" ;
VAL_ 1513 APP_sw188_exitStatus 0 "STREAM_EXIT_NOMINAL" 1 "STREAM_EXIT_FAULT" ;
VAL_ 1513 APP_sw144_fanctrldErrorType 13 "ERROR_FAILED_SET_FAN_MIN_SPEED" 9 "ERROR_SUB_ZERO" 2 "ERROR_TERMINATE" 11 "ERROR_FAILED_ENABLE_FAN" 14 "ERROR_FAILED_SET_FAN_MAX_SPEED" 5 "ERROR_FAILED_READ_PASCAL_TMP" 4 "ERROR_FAILED_READ_PARKER_TMP" 1 "ERROR_INIT" 6 "ERROR_FAILED_READ_MAXIM_TMP" 8 "ERROR_FAILED_CHECK_FAN_STATUS" 7 "ERROR_FAILED_WRITE_RESISTOR" 10 "ERROR_THERMAL_LIMIT" 3 "ERROR_FAILED_READ_TMP451_TMP" 0 "FANCTRL_NO_ERROR" 12 "ERROR_FAILED_DISABLE_FAN" ;
VAL_ 1513 APP_sw199_abortCodeDAS 10 "APC_ABORT_SCCM_MIA" 11 "APC_ABORT_ESP_MIA" 6 "APC_ABORT_PARK_MIA" 21 "APC_ABORT_USER_KEYFOB" 20 "APC_ABORT_SC_MIA" 5 "APC_ABORT_PREGUIDANCE_TIMEOUT" 13 "APC_ABORT_PAUSE_USER_TIMEOUT" 23 "APC_ABORT_PAUSE_CYCLES" 15 "APC_ABORT_PARK_GEAR" 19 "APC_ABORT_SENSOR_FAILURE" 9 "APC_ABORT_MCU_MIA" 8 "APC_ABORT_DI_MIA" 1 "APC_ABORT_LOST_ANGLE_CONTROL" 0 "APC_ABORT_NONE" 4 "APC_ABORT_INVALID_SPACE" 17 "APC_ABORT_UI_REQUEST" 7 "APC_ABORT_EPAS_MIA" 22 "APC_ABORT_EPAS_INHIBITED" 2 "APC_ABORT_PARK_GUIDANCE_ENDED" 12 "APC_ABORT_PAUSE_OBSTACLE_TIMEOUT" 18 "APC_ABORT_PRECRUISE_TIMEOUT" 14 "APC_ABORT_RESTART_TIMEOUT" 24 "APC_ABORT_APP_MIA" 3 "APC_ABORT_MCU_REQUEST_MISMATCH" 16 "APC_ABORT_LOST_DI_CONTROL" ;
VAL_ 1513 APP_sw279_exitStatus 0 "STREAM_EXIT_NOMINAL" 1 "STREAM_EXIT_FAULT" ;
VAL_ 1513 APP_sw182_exitStatus 0 "STREAM_EXIT_NOMINAL" 1 "STREAM_EXIT_FAULT" ;
VAL_ 1513 APP_sw276_exitStatus 0 "STREAM_EXIT_NOMINAL" 1 "STREAM_EXIT_FAULT" ;
VAL_ 1513 APP_sw281_exitStatus 0 "STREAM_EXIT_NOMINAL" 1 "STREAM_EXIT_FAULT" ;
VAL_ 1513 APP_sw031_canBus 1 "RAD0" 7 "Unknown" 0 "CH" 2 "PARTY" ;
VAL_ 1513 APP_sw147_selfieCamDeserFault 0 "NO_I2C_FAULT" 4 "I2C_UNKNOWN_IOCTL_ERR" 3 "I2C_DATA_NACK" 2 "I2C_SLAVE_ADDR_NACK" 1 "I2C_BUS_FAULT" ;
VAL_ 1513 APP_sw042_health_state 3 "AP_HEALTH_SEVERELY_DEGRADED" 2 "AP_HEALTH_DEGRADED" 6 "AP_HEALTH_UNUSED" 7 "AP_HEALTH_SNA" 0 "AP_HEALTH_UNAVAILABLE" 5 "AP_HEALTH_FAULT" 4 "AP_HEALTH_ABORTING" 1 "AP_HEALTH_NOMINAL" ;
VAL_ 1513 APP_sw187_exitStatus 0 "STREAM_EXIT_NOMINAL" 1 "STREAM_EXIT_FAULT" ;
VAL_ 1513 APP_sw273_eventType 0 "APP_LSS_EVENT_TYPE_LKA" 1 "APP_LSS_EVENT_TYPE_ELK" ;
VAL_ 1513 APP_sw134_narrowCamDeserFault 0 "NO_I2C_FAULT" 4 "I2C_UNKNOWN_IOCTL_ERR" 3 "I2C_DATA_NACK" 2 "I2C_SLAVE_ADDR_NACK" 1 "I2C_BUS_FAULT" ;
VAL_ 1513 APP_sw184_exitStatus 0 "STREAM_EXIT_NOMINAL" 1 "STREAM_EXIT_FAULT" ;
VAL_ 1513 APP_alertState 0 "ALERT_CLEARED" 1 "ALERT_SET" ;
VAL_ 1513 APP_alertID 92 "APP_w092_DEPRECATED" 158 "APP_w158_vcfrontMiaVehBus" 149 "APP_w149_diskFull" 274 "APP_w274_mainCameraStreamErr" 28 "APP_w028_spi_rx_error" 30 "APP_w030_Heater_Issue" 51 "APP_w051_radcEcuIssue" 48 "APP_w048_APP_Features_Disabled" 167 "APP_w167_lRepeatCameraTypeError" 210 "APP_w210_camObstrcted" 102 "APP_w102_DEPRECATED" 27 "APP_w027_ECU_Reset_Fault" 188 "APP_w188_rRepeatCameraStreamExit" 169 "APP_w169_backupCameraTypeError" 101 "APP_w101_DEPRECATED" 88 "APP_w088_DEPRECATED" 0 "APP_ALERT_DO_NOT_USE_ZERO" 199 "APP_w199_apcAbort" 32 "APP_w032_canTxError" 204 "APP_w204_apcFinalFront" 193 "APP_w193_camWindshieldUnclean" 91 "APP_w091_DEPRECATED" 40 "APP_w040_autopilotAngleSaturated" 181 "APP_w181_rRepeatCamCalSaved" 26 "APP_w026_ECU_timingIssue" 139 "APP_w139_rRepeatCamInitFault" 129 "APP_w129_mainCamExtNotCal" 172 "APP_w172_fisheyeCamExtNotCal" 82 "APP_w082_inPathFSviolation" 104 "APP_w104_DEPRECATED" 153 "APP_w153_rcmMiaPartyBus" 77 "APP_w077_pmmActive" 94 "APP_w094_DEPRECATED" 5 "APP_w005_fcwCancelled" 215 "APP_w215_contDriverNotIntracting" 31 "APP_w031_canRxError" 213 "APP_w213_autosteerStruckOut" 225 "APP_w225_lcDegradedVisSpeedLmt" 140 "APP_w140_backupCamInitFault" 52 "APP_w052_radcSensorIssue" 76 "APP_w076_mobilEyeSetC" 69 "APP_w069_apcSpaceMasked" 219 "APP_w219_lcTempUnavailableSpeed" 79 "APP_w079_edrAvailable" 56 "APP_w056_diMia" 74 "APP_w074_inPathStationaryObst" 49 "APP_w049_eyeqVersionMismatch" 45 "APP_w045_radMia" 67 "APP_w067_steeringAlignment" 265 "APP_w265_drvOnNavUnavailable" 22 "APP_w022_ECU_EEPROM_Failure" 83 "APP_w083_inPathRADObject" 41 "APP_w041_autopilotRateSaturated" 87 "APP_w087_DEPRECATED" 211 "APP_w211_accNoSeatBelt" 276 "APP_w276_fisheyeCameraStreamErr" 201 "APP_w201_lcAborting" 217 "APP_w217_lcUnavailableSpeeding" 180 "APP_w180_lRepeatCamCalSaved" 54 "APP_w054_camAutofix" 150 "APP_w150_diMiaPartyBus" 206 "APP_w206_autosteerNotEnabled" 136 "APP_w136_lPillarCamInitFault" 68 "APP_w068_vlInconsistency" 17 "APP_w017_Cam_Msg_MIA" 144 "APP_w144_fanctrldError" 190 "APP_w190_selfieCameraStreamExit" 218 "APP_w218_lcSpeedExceededLimit" 165 "APP_w165_lPillarCameraTypeError" 229 "APP_w229_alcUltrasoundDamaged" 278 "APP_w278_rPillarCameraStreamErr" 141 "APP_w141_ECU_Thermal_Issue" 147 "APP_w147_selfieCamInitFault" 135 "APP_w135_fisheyeCamInitFault" 151 "APP_w151_epasMiaPartyBus" 21 "APP_w021_ECU_Temperature_Issue" 184 "APP_w184_fisheyeCameraStreamExit" 11 "APP_w011_scaEvent" 70 "APP_w070_apcIncompleteCal" 61 "APP_w061_airSuspensionMia" 272 "APP_w272_laneChangeUnavailable" 176 "APP_w176_rRepeatCamExtNotCal" 8 "APP_w008_parkDisabled" 166 "APP_w166_rPillarCameraTypeError" 202 "APP_w202_scwNoisyEnvironment" 269 "APP_w269_autopilotLimited" 259 "APP_w259_aebOverrideEvent" 130 "APP_w130_narrowCamExtNotCal" 282 "APP_w282_selfieCameraStreamErr" 1 "APP_w001_DEPRECATED" 200 "APP_w200_lcSlowdown" 100 "APP_w100_DEPRECATED" 89 "APP_w089_DEPRECATED" 227 "APP_w227_virtualWallBlocked" 72 "APP_w072_selfparkComplete" 183 "APP_w183_narrowCameraStreamExit" 64 "APP_w064_epasMia" 3 "APP_w003_isaDisabled" 90 "APP_w090_DEPRECATED" 177 "APP_w177_fisheyeCamCalSaved" 85 "APP_w085_pmmSteering" 7 "APP_w007_ahlbDisabled" 171 "APP_w171_appHighCoolantFlowReq" 157 "APP_w157_sccmMiaVehBus" 36 "APP_w036_bdyMia" 81 "APP_w081_pmmActiveBraking" 266 "APP_w266_visionScheduleFallback" 261 "APP_w261_pcieHardwareErrors" 97 "APP_w097_DEPRECATED" 53 "APP_w053_radcCommIssue" 222 "APP_w222_accCameraBlind" 194 "APP_w194_accDriverResumeRqrd" 75 "APP_w075_scMia" 62 "APP_w062_radcAlignment" 208 "APP_w208_rackDetected" 58 "APP_w058_epbMia" 198 "APP_w198_tsrUnavailable" 162 "APP_w162_mainCameraTypeError" 13 "APP_w013_Cam_Watchdog" 174 "APP_w174_rPillarCamExtNotCal" 137 "APP_w137_rPillarCamInitFault" 216 "APP_w216_driverOverriding" 55 "APP_w055_radcVersionMismatch" 66 "APP_w066_deserializerLockLost" 163 "APP_w163_narrowCameraTypeError" 186 "APP_w186_rPillarCameraStreamExit" 15 "APP_w015_Camera_Failsafes" 209 "APP_w209_autoSummonRequest" 192 "APP_w192_emergencySpeakerFail" 191 "APP_w191_autopilotAborting" 230 "APP_w230_alcUltrasoundBlocked" 220 "APP_w220_lcTempUnavailableRoad" 106 "APP_w106_torsionBarOffset" 39 "APP_w039_sdm_rcm_Mia" 228 "APP_w228_DEPRECATED" 154 "APP_w154_vcleftMiaPartyBus" 10 "APP_w010_radcCalibIssue" 159 "APP_w159_vcleftMiaVehBus" 267 "APP_w267_benchtopEcu" 19 "APP_w019_ECU_Stack_Overflow" 65 "APP_w065_deserializerOvercurrent" 84 "APP_w084_pmmIPSO" 78 "APP_w078_pmmActive2" 25 "APP_w025_LC_Steering_Override" 263 "APP_w263_lssAbort" 33 "APP_w033_gtwMia" 221 "APP_w221_accRadarBlind" 226 "APP_w226_lcCamCalNeededSpeedLmt" 59 "APP_w059_parkMia" 99 "APP_w099_DEPRECATED" 18 "APP_w018_ECU_Power_Issue" 262 "APP_w262_apeCalibMode" 178 "APP_w178_lPillarCamCalSaved" 145 "APP_w145_camSelfCalIssue" 57 "APP_w057_mcuMia" 131 "APP_w131_mainCamCalSaved" 47 "APP_w047_edrEvent" 34 "APP_w034_sccmMia" 37 "APP_w037_camTacIssue" 38 "APP_w038_camFailure" 277 "APP_w277_lPillarCameraStreamErr" 260 "APP_w260_collisionWarningEvent" 71 "APP_w071_selfparkStarted" 6 "APP_w006_aebCancelled" 63 "APP_w063_parkVersionMismatch" 168 "APP_w168_rRepeatCameraTypeError" 148 "APP_w148_overlayActive" 93 "APP_w093_DEPRECATED" 155 "APP_w155_vcrightMiaPartyBus" 156 "APP_w156_epblMiaVehBus" 132 "APP_w132_narrowCamCalSaved" 161 "APP_w161_backupCameraUnavailable" 189 "APP_w189_backupCameraStreamExit" 14 "APP_w014_swAssert" 179 "APP_w179_rPillarCamCalSaved" 214 "APP_w214_driverNotIntracting" 264 "APP_w264_lssFault" 80 "APP_w080_accFailedActivation" 143 "APP_w143_IDF_event" 224 "APP_w224_accCameraCalibration" 73 "APP_w073_issueEscalatedLDW" 96 "APP_w096_DEPRECATED" 23 "APP_w023_ECU_Cam_Statemismatc" 134 "APP_w134_narrowCamInitFault" 173 "APP_w173_lPillarCamExtNotCal" 273 "APP_w273_lssEvent" 43 "APP_w043_camLongRunTime" 138 "APP_w138_lRepeatCamInitFault" 29 "APP_w029_spi_tx_error" 42 "APP_w042_autopilotAborting" 12 "APP_w012_Cam_BootFailure" 95 "APP_w095_DEPRECATED" 207 "APP_w207_autosteerUnavailable" 24 "APP_w024_ECU_Watchdog_Reset" 281 "APP_w281_backupCameraStreamErr" 270 "APP_w270_blindspotRestricted" 182 "APP_w182_mainCameraStreamExit" 105 "APP_w105_DEPRECATED" 2 "APP_w002_ldwDisabled" 133 "APP_w133_mainCamInitFault" 9 "APP_w009_aebFault" 257 "APP_w257_brakeJerkEvent" 4 "APP_w004_accDisabled" 35 "APP_w035_espMia" 205 "APP_w205_apcFinalRear" 223 "APP_w223_accObjectInPath" 175 "APP_w175_lRepeatCamExtNotCal" 258 "APP_w258_aebEvent" 44 "APP_w044_appMobileyeFailure" 20 "APP_w020_ECU_checkstopError" 16 "APP_w016_aeb_e_event" 142 "APP_w142_fwdCamPitchProblem" 187 "APP_w187_lRepeatCameraStreamExit" 212 "APP_w212_lcUnavailableStrikeOut" 197 "APP_w197_redLightWarning" 46 "APP_w046_eepromRecordAbsent" 160 "APP_w160_vcrightMiaVehBus" 195 "APP_w195_scwUnavailable" 98 "APP_w098_DEPRECATED" 50 "APP_w050_aeb_event" 275 "APP_w275_narrowCameraStreamErr" 152 "APP_w152_espMiaPartyBus" 60 "APP_w060_fcw_event" 203 "APP_w203_apcActivation" 103 "APP_w103_robExperimentalAEB" 146 "APP_w146_telemetryProblem" 271 "APP_w271_laneChangeAborted" 170 "APP_w170_selfieCameraTypeError" 86 "APP_w086_robCollision" 268 "APP_w268_backupCamExtNotCal" 164 "APP_w164_fisheyeCameraTypeError" 280 "APP_w280_rRepeatCameraStreamErr" 279 "APP_w279_lRepeatCameraStreamErr" 231 "APP_w231_idfEvent" 185 "APP_w185_lPillarCameraStreamExit" 196 "APP_w196_stopSignWarning" ;
VAL_ 792 GTW_tsMonth 9 "SEPTEMBER" 12 "DECEMBER" 10 "OCTOBER" 1 "JANUARY" 7 "JULY" 11 "NOVEMBER" 5 "MAY" 4 "APRIL" 6 "JUNE" 2 "FEBRUARY" 3 "MARCH" 8 "AUGUST" ;
